VERSION ""

NS_ :

BS_:

BU_: Cooling DasFront DasRear Ecu Imu Lvac Pedals Pipo Raspberry Steering SteeringWheel TsacMainboard Acquisinator

BO_ 1260 ImuAngularRate: 6 Imu
 SG_ x : 7|16@0- (0.01,0) [0|245] "dps"  Vector__XXX
 SG_ y : 23|16@0- (0.01,0) [0|245] "dps"  Vector__XXX
 SG_ z : 39|16@0- (0.01,0) [0|245] "dps"  Vector__XXX

BO_ 1261 ImuAcceleration: 8 Imu
 SG_ x : 7|16@0- (0.01,0) [0|8] "g"  Vector__XXX
 SG_ y : 23|16@0- (0.01,0) [0|8] "g"  Vector__XXX
 SG_ z : 39|16@0- (0.01,0) [0|8] "g"  Vector__XXX
 SG_ temperature : 55|16@0- (1,-32768) [-32768|32767] "degC"  Vector__XXX

BO_ 1227 DasRearFsm: 1 DasRear
 SG_ status : 0|2@1+ (1,0) [0|0] "enum"  Vector__XXX

BO_ 1636 DasRearVersion: 6 DasRear
 SG_ major : 0|16@1+ (1,0) [0|65535] "U"  Vector__XXX
 SG_ minor : 16|16@1+ (1,0) [0|65535] "U"  Vector__XXX
 SG_ patch : 32|16@1+ (1,0) [0|65535] "U"  Vector__XXX

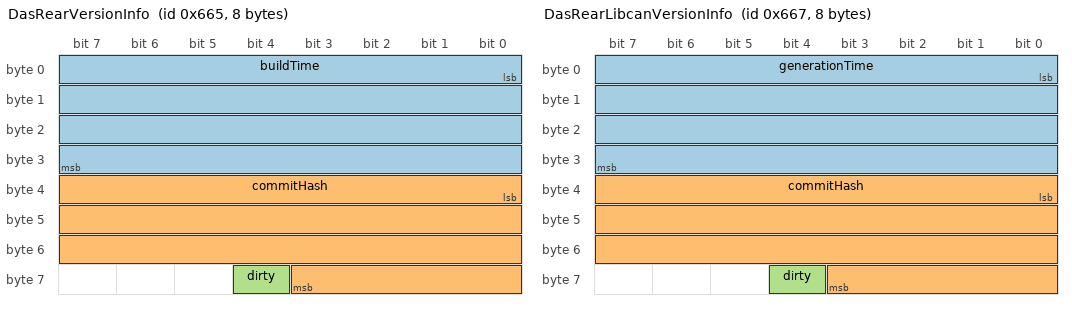
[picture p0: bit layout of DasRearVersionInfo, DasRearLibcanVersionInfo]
BO_ 1637 DasRearVersionInfo: 8 DasRear
 SG_ buildTime : 0|32@1+ (1,0) [0|4294967295] "s"  Vector__XXX
 SG_ commitHash : 32|28@1+ (1,0) [0|268435455] "U"  Vector__XXX
 SG_ dirty : 60|1@1+ (1,0) [0|1] "bool"  Vector__XXX

BO_ 1638 DasRearLibcanVersion: 6 DasRear
 SG_ major : 0|16@1+ (1,0) [0|65535] "U"  Vector__XXX
 SG_ minor : 16|16@1+ (1,0) [0|65535] "U"  Vector__XXX
 SG_ patch : 32|16@1+ (1,0) [0|65535] "U"  Vector__XXX

BO_ 1639 DasRearLibcanVersionInfo: 8 DasRear
 SG_ generationTime : 0|32@1+ (1,0) [0|4294967295] "s"  Vector__XXX
 SG_ commitHash : 32|28@1+ (1,0) [0|268435455] "U"  Vector__XXX
 SG_ dirty : 60|1@1+ (1,0) [0|1] "bool"  Vector__XXX

BO_ 1228 TyreTemperatureRear: 2 DasRear
 SG_ rearRight : 0|8@1+ (1,-20) [-20|150] "degC"  Vector__XXX
 SG_ rearLeft : 8|8@1+ (1,-20) [-20|150] "degC"  Vector__XXX

BO_ 1229 SuspensionRear: 4 DasRear
 SG_ heave : 0|13@1+ (0.01,0) [0|50] "mm"  Vector__XXX
 SG_ roll : 13|14@1+ (0.01,-50) [-50|50] "mm"  Vector__XXX

BO_ 1230 PipoFsm: 1 Pipo
 SG_ status : 0|2@1+ (1,0) [0|0] "enum"  Vector__XXX

BO_ 1640 PipoVersion: 6 Pipo
 SG_ major : 0|16@1+ (1,0) [0|65535] "U"  Vector__XXX
 SG_ minor : 16|16@1+ (1,0) [0|65535] "U"  Vector__XXX
 SG_ patch : 32|16@1+ (1,0) [0|65535] "U"  Vector__XXX

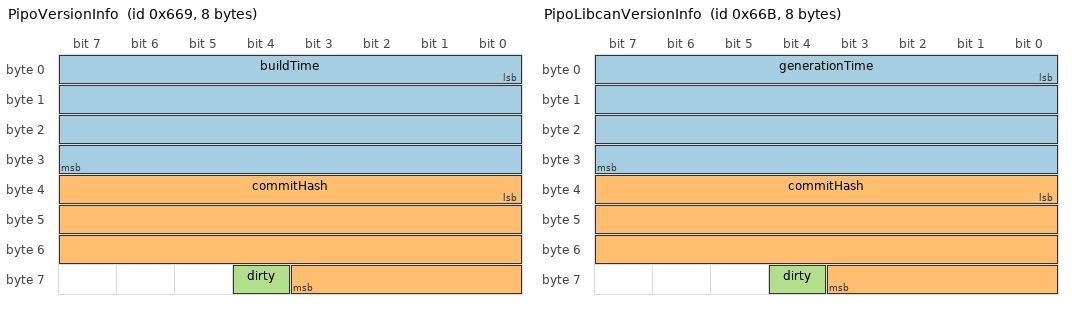
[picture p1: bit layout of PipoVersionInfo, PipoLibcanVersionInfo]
BO_ 1641 PipoVersionInfo: 8 Pipo
 SG_ buildTime : 0|32@1+ (1,0) [0|4294967295] "s"  Vector__XXX
 SG_ commitHash : 32|28@1+ (1,0) [0|268435455] "U"  Vector__XXX
 SG_ dirty : 60|1@1+ (1,0) [0|1] "bool"  Vector__XXX

BO_ 1642 PipoLibcanVersion: 6 Pipo
 SG_ major : 0|16@1+ (1,0) [0|65535] "U"  Vector__XXX
 SG_ minor : 16|16@1+ (1,0) [0|65535] "U"  Vector__XXX
 SG_ patch : 32|16@1+ (1,0) [0|65535] "U"  Vector__XXX

BO_ 1643 PipoLibcanVersionInfo: 8 Pipo
 SG_ generationTime : 0|32@1+ (1,0) [0|4294967295] "s"  Vector__XXX
 SG_ commitHash : 32|28@1+ (1,0) [0|268435455] "U"  Vector__XXX
 SG_ dirty : 60|1@1+ (1,0) [0|1] "bool"  Vector__XXX

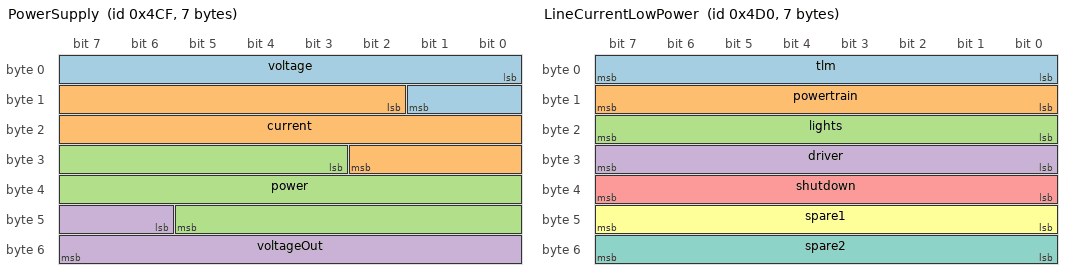
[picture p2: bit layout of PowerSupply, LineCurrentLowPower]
BO_ 1231 PowerSupply: 7 Pipo
 SG_ voltage : 0|10@1+ (0.03,0) [0|27] "V"  Vector__XXX
 SG_ current : 10|17@1+ (0.001,0) [0|100] "A"  Vector__XXX
 SG_ power : 27|19@1+ (0.01,0) [0|2700] "W"  Vector__XXX
 SG_ voltageOut : 46|10@1+ (0.03,0) [0|27] "V"  Vector__XXX

BO_ 1232 LineCurrentLowPower: 7 Pipo
 SG_ tlm : 0|8@1+ (0.05,0) [0|10] "A"  Vector__XXX
 SG_ powertrain : 8|8@1+ (0.05,0) [0|10] "A"  Vector__XXX
 SG_ lights : 16|8@1+ (0.05,0) [0|10] "A"  Vector__XXX
 SG_ driver : 24|8@1+ (0.05,0) [0|10] "A"  Vector__XXX
 SG_ shutdown : 32|8@1+ (0.05,0) [0|10] "A"  Vector__XXX
 SG_ spare1 : 40|8@1+ (0.05,0) [0|10] "A"  Vector__XXX
 SG_ spare2 : 48|8@1+ (0.05,0) [0|10] "A"  Vector__XXX

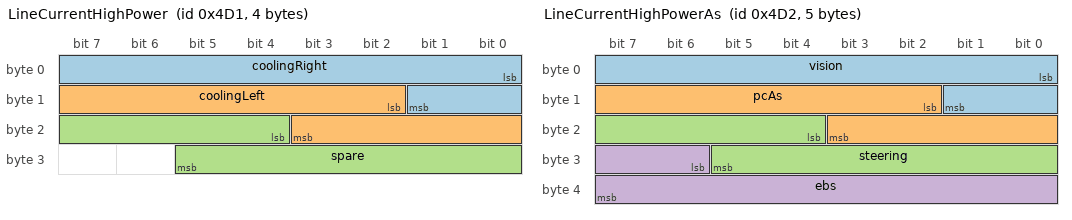
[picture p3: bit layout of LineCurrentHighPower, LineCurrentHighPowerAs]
BO_ 1233 LineCurrentHighPower: 4 Pipo
 SG_ coolingRight : 0|10@1+ (0.05,0) [0|30] "A"  Vector__XXX
 SG_ coolingLeft : 10|10@1+ (0.05,0) [0|30] "A"  Vector__XXX
 SG_ spare : 20|10@1+ (0.05,0) [0|30] "A"  Vector__XXX

BO_ 1234 LineCurrentHighPowerAs: 5 Pipo
 SG_ vision : 0|10@1+ (0.05,0) [0|30] "A"  Vector__XXX
 SG_ pcAs : 10|10@1+ (0.05,0) [0|30] "A"  Vector__XXX
 SG_ steering : 20|10@1+ (0.05,0) [0|30] "A"  Vector__XXX
 SG_ ebs : 30|10@1+ (0.05,0) [0|30] "A"  Vector__XXX

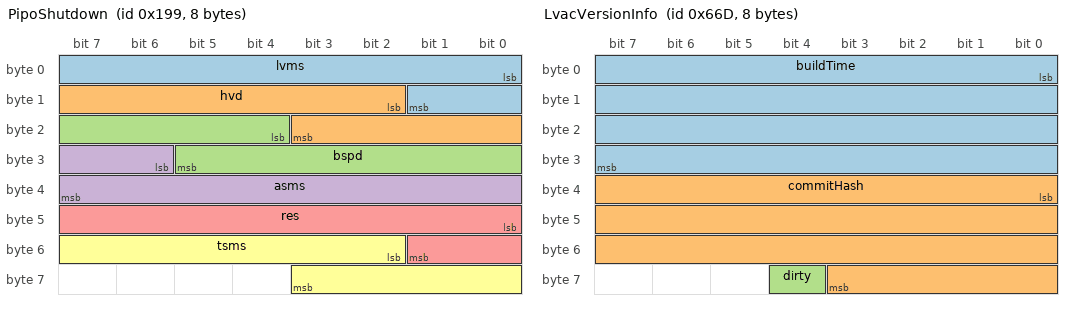
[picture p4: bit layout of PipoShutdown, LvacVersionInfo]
BO_ 409 PipoShutdown: 8 Pipo
 SG_ lvms : 0|10@1+ (0.03,0) [0|27] "V"  Vector__XXX
 SG_ hvd : 10|10@1+ (0.03,0) [0|27] "V"  Vector__XXX
 SG_ bspd : 20|10@1+ (0.03,0) [0|27] "V"  Vector__XXX
 SG_ asms : 30|10@1+ (0.03,0) [0|27] "V"  Vector__XXX
 SG_ res : 40|10@1+ (0.03,0) [0|27] "V"  Vector__XXX
 SG_ tsms : 50|10@1+ (0.03,0) [0|27] "V"  Vector__XXX

BO_ 1235 LvacFsm: 1 Lvac
 SG_ status : 0|2@1+ (1,0) [0|0] "enum"  Vector__XXX

BO_ 1644 LvacVersion: 6 Lvac
 SG_ major : 0|16@1+ (1,0) [0|65535] "U"  Vector__XXX
 SG_ minor : 16|16@1+ (1,0) [0|65535] "U"  Vector__XXX
 SG_ patch : 32|16@1+ (1,0) [0|65535] "U"  Vector__XXX

BO_ 1645 LvacVersionInfo: 8 Lvac
 SG_ buildTime : 0|32@1+ (1,0) [0|4294967295] "s"  Vector__XXX
 SG_ commitHash : 32|28@1+ (1,0) [0|268435455] "U"  Vector__XXX
 SG_ dirty : 60|1@1+ (1,0) [0|1] "bool"  Vector__XXX

BO_ 1646 LvacLibcanVersion: 6 Lvac
 SG_ major : 0|16@1+ (1,0) [0|65535] "U"  Vector__XXX
 SG_ minor : 16|16@1+ (1,0) [0|65535] "U"  Vector__XXX
 SG_ patch : 32|16@1+ (1,0) [0|65535] "U"  Vector__XXX

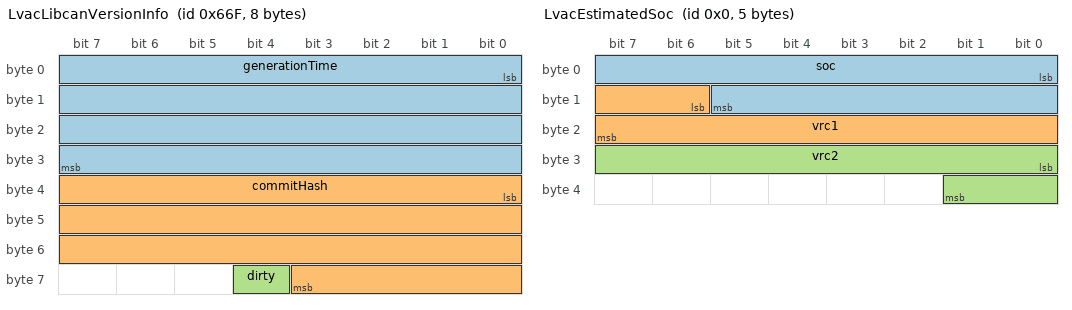
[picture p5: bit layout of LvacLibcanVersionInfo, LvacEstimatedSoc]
BO_ 1647 LvacLibcanVersionInfo: 8 Lvac
 SG_ generationTime : 0|32@1+ (1,0) [0|4294967295] "s"  Vector__XXX
 SG_ commitHash : 32|28@1+ (1,0) [0|268435455] "U"  Vector__XXX
 SG_ dirty : 60|1@1+ (1,0) [0|1] "bool"  Vector__XXX

BO_ 0 LvacEstimatedSoc: 5 Lvac
 SG_ soc : 0|14@1+ (0.0001,0) [0|1] "U"  Vector__XXX
 SG_ vrc1 : 14|10@1+ (0.005,0) [0|4.5] "V"  Vector__XXX
 SG_ vrc2 : 24|10@1+ (0.005,0) [0|4.5] "V"  Vector__XXX

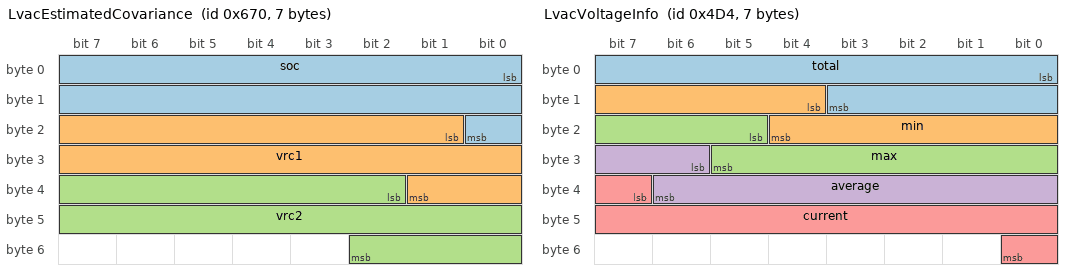
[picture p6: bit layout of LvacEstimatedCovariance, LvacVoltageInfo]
BO_ 1648 LvacEstimatedCovariance: 7 Lvac
 SG_ soc : 0|17@1+ (0.0001,0) [0|10] "U"  Vector__XXX
 SG_ vrc1 : 17|17@1+ (0.001,0) [0|100] "V"  Vector__XXX
 SG_ vrc2 : 34|17@1+ (0.001,0) [0|100] "V"  Vector__XXX

BO_ 1236 LvacVoltageInfo: 7 Lvac
 SG_ total : 0|12@1+ (0.01,0) [0|27] "V"  Vector__XXX
 SG_ min : 12|9@1+ (0.005,2) [2|4.5] "V"  Vector__XXX
 SG_ max : 21|9@1+ (0.005,2) [2|4.5] "V"  Vector__XXX
 SG_ average : 30|9@1+ (0.005,2) [2|4.5] "V"  Vector__XXX
 SG_ current : 39|10@1+ (0.05,0) [0|30] "A"  Vector__XXX

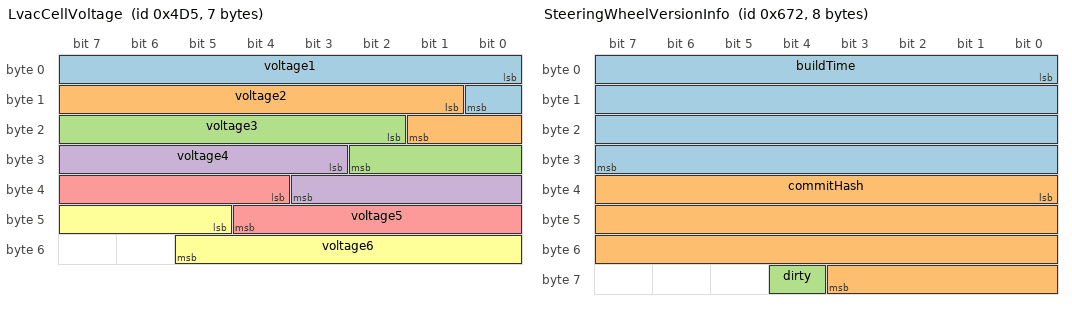
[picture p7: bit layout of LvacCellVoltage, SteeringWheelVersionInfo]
BO_ 1237 LvacCellVoltage: 7 Lvac
 SG_ voltage1 : 0|9@1+ (0.005,2) [2|4.5] "V"  Vector__XXX
 SG_ voltage2 : 9|9@1+ (0.005,2) [2|4.5] "V"  Vector__XXX
 SG_ voltage3 : 18|9@1+ (0.005,2) [2|4.5] "V"  Vector__XXX
 SG_ voltage4 : 27|9@1+ (0.005,2) [2|4.5] "V"  Vector__XXX
 SG_ voltage5 : 36|9@1+ (0.005,2) [2|4.5] "V"  Vector__XXX
 SG_ voltage6 : 45|9@1+ (0.005,2) [2|4.5] "V"  Vector__XXX

BO_ 1238 LvacTemperatureInfo: 6 Lvac
 SG_ min : 0|16@1+ (0.005,-50) [-50|125] "degC"  Vector__XXX
 SG_ max : 16|16@1+ (0.005,-50) [-50|125] "degC"  Vector__XXX
 SG_ average : 32|16@1+ (0.005,-50) [-50|125] "degC"  Vector__XXX

BO_ 1239 LvacTemperature: 7 Lvac
 SG_ group M : 0|1@1+ (1,0) [0|1] "U"  Vector__XXX
 SG_ temperature1 m0 : 1|9@1+ (0.005,2) [2|4.5] "degC"  Vector__XXX
 SG_ temperature2 m0 : 10|9@1+ (0.005,2) [2|4.5] "degC"  Vector__XXX
 SG_ temperature3 m0 : 19|9@1+ (0.005,2) [2|4.5] "degC"  Vector__XXX
 SG_ temperature4 m0 : 28|9@1+ (0.005,2) [2|4.5] "degC"  Vector__XXX
 SG_ temperature5 m0 : 37|9@1+ (0.005,2) [2|4.5] "degC"  Vector__XXX
 SG_ temperature6 m0 : 46|9@1+ (0.005,2) [2|4.5] "degC"  Vector__XXX
 SG_ temperature7 m1 : 1|9@1+ (0.005,2) [2|4.5] "degC"  Vector__XXX
 SG_ temperature8 m1 : 10|9@1+ (0.005,2) [2|4.5] "degC"  Vector__XXX
 SG_ temperature9 m1 : 19|9@1+ (0.005,2) [2|4.5] "degC"  Vector__XXX
 SG_ temperature10 m1 : 28|9@1+ (0.005,2) [2|4.5] "degC"  Vector__XXX
 SG_ temperature11 m1 : 37|9@1+ (0.005,2) [2|4.5] "degC"  Vector__XXX
 SG_ temperature12 m1 : 46|9@1+ (0.005,2) [2|4.5] "degC"  Vector__XXX

BO_ 1240 SteeringWheelFsm: 1 SteeringWheel
 SG_ status : 0|3@1+ (1,0) [0|0] "enum"  Vector__XXX

BO_ 1649 SteeringWheelVersion: 6 SteeringWheel
 SG_ major : 0|16@1+ (1,0) [0|65535] "U"  Vector__XXX
 SG_ minor : 16|16@1+ (1,0) [0|65535] "U"  Vector__XXX
 SG_ patch : 32|16@1+ (1,0) [0|65535] "U"  Vector__XXX

BO_ 1650 SteeringWheelVersionInfo: 8 SteeringWheel
 SG_ buildTime : 0|32@1+ (1,0) [0|4294967295] "s"  Vector__XXX
 SG_ commitHash : 32|28@1+ (1,0) [0|268435455] "U"  Vector__XXX
 SG_ dirty : 60|1@1+ (1,0) [0|1] "bool"  Vector__XXX

BO_ 1651 SteeringWheelLibcanVersion: 6 SteeringWheel
 SG_ major : 0|16@1+ (1,0) [0|65535] "U"  Vector__XXX
 SG_ minor : 16|16@1+ (1,0) [0|65535] "U"  Vector__XXX
 SG_ patch : 32|16@1+ (1,0) [0|65535] "U"  Vector__XXX

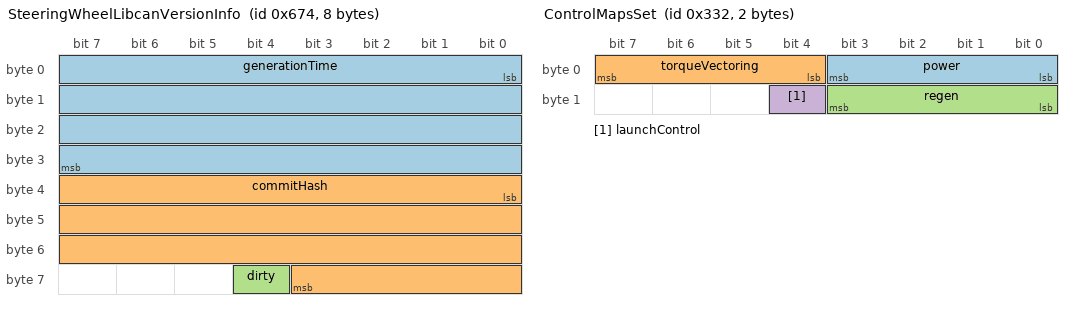
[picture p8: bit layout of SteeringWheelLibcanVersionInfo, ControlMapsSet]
BO_ 1652 SteeringWheelLibcanVersionInfo: 8 SteeringWheel
 SG_ generationTime : 0|32@1+ (1,0) [0|4294967295] "s"  Vector__XXX
 SG_ commitHash : 32|28@1+ (1,0) [0|268435455] "U"  Vector__XXX
 SG_ dirty : 60|1@1+ (1,0) [0|1] "bool"  Vector__XXX

BO_ 818 ControlMapsSet: 2 SteeringWheel
 SG_ power : 0|4@1+ (0.1,0) [0|1] "U"  Vector__XXX
 SG_ torqueVectoring : 4|4@1+ (0.1,0) [0|1] "U"  Vector__XXX
 SG_ regen : 8|4@1+ (0.1,0) [0|1] "U"  Vector__XXX
 SG_ launchControl : 12|1@1+ (1,0) [0|1] "bool"  Vector__XXX

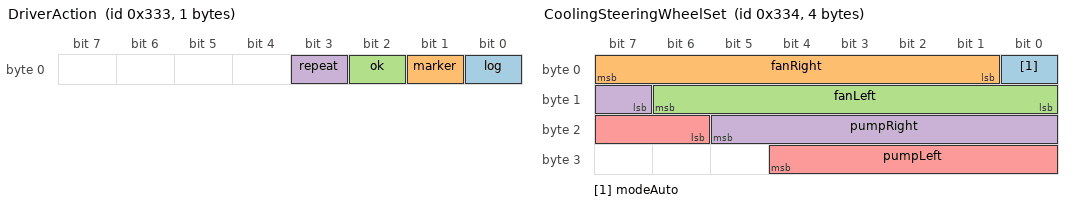
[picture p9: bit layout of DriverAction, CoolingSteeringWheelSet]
BO_ 819 DriverAction: 1 SteeringWheel
 SG_ log : 0|1@1+ (1,0) [0|1] "bool"  Vector__XXX
 SG_ marker : 1|1@1+ (1,0) [0|1] "bool"  Vector__XXX
 SG_ ok : 2|1@1+ (1,0) [0|1] "bool"  Vector__XXX
 SG_ repeat : 3|1@1+ (1,0) [0|1] "bool"  Vector__XXX

BO_ 1 SteeringWheelButtonStatus: 1 SteeringWheel
 SG_ tson : 0|1@1+ (1,0) [0|1] "bool"  Vector__XXX
 SG_ ptt : 1|1@1+ (1,0) [0|1] "bool"  Vector__XXX

BO_ 820 CoolingSteeringWheelSet: 4 SteeringWheel
 SG_ modeAuto : 0|1@1+ (1,0) [0|1] "bool"  Vector__XXX
 SG_ fanRight : 1|7@1+ (0.01,0) [0|1] "U"  Vector__XXX
 SG_ fanLeft : 8|7@1+ (0.01,0) [0|1] "U"  Vector__XXX
 SG_ pumpRight : 15|7@1+ (0.01,0) [0|1] "U"  Vector__XXX
 SG_ pumpLeft : 22|7@1+ (0.01,0) [0|1] "U"  Vector__XXX

BO_ 1241 CoolingFsm: 1 Cooling
 SG_ status : 0|2@1+ (1,0) [0|0] "enum"  Vector__XXX

BO_ 1653 CoolingVersion: 6 Cooling
 SG_ major : 0|16@1+ (1,0) [0|65535] "U"  Vector__XXX
 SG_ minor : 16|16@1+ (1,0) [0|65535] "U"  Vector__XXX
 SG_ patch : 32|16@1+ (1,0) [0|65535] "U"  Vector__XXX

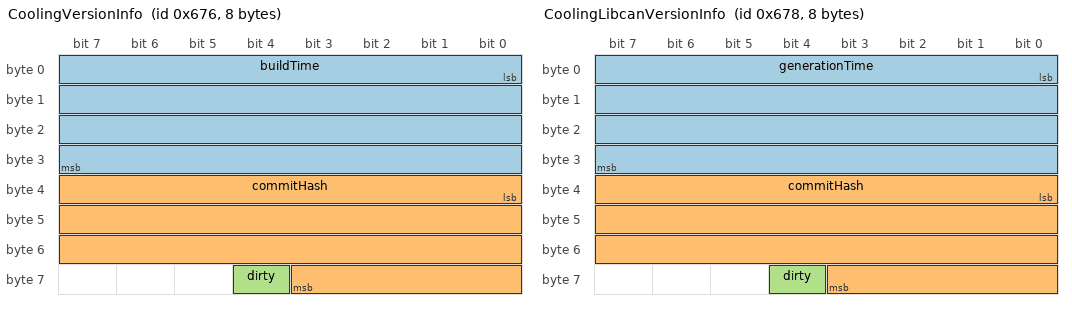
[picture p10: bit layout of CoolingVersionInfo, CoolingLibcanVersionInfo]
BO_ 1654 CoolingVersionInfo: 8 Cooling
 SG_ buildTime : 0|32@1+ (1,0) [0|4294967295] "s"  Vector__XXX
 SG_ commitHash : 32|28@1+ (1,0) [0|268435455] "U"  Vector__XXX
 SG_ dirty : 60|1@1+ (1,0) [0|1] "bool"  Vector__XXX

BO_ 1655 CoolingLibcanVersion: 6 Cooling
 SG_ major : 0|16@1+ (1,0) [0|65535] "U"  Vector__XXX
 SG_ minor : 16|16@1+ (1,0) [0|65535] "U"  Vector__XXX
 SG_ patch : 32|16@1+ (1,0) [0|65535] "U"  Vector__XXX

BO_ 1656 CoolingLibcanVersionInfo: 8 Cooling
 SG_ generationTime : 0|32@1+ (1,0) [0|4294967295] "s"  Vector__XXX
 SG_ commitHash : 32|28@1+ (1,0) [0|268435455] "U"  Vector__XXX
 SG_ dirty : 60|1@1+ (1,0) [0|1] "bool"  Vector__XXX

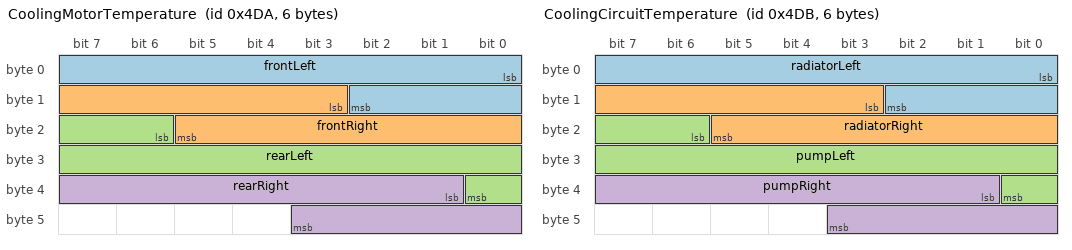
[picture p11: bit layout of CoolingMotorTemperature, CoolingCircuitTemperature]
BO_ 1242 CoolingMotorTemperature: 6 Cooling
 SG_ frontLeft : 0|11@1+ (0.1,-50) [-50|125] "degC"  Vector__XXX
 SG_ frontRight : 11|11@1+ (0.1,-50) [-50|125] "degC"  Vector__XXX
 SG_ rearLeft : 22|11@1+ (0.1,-50) [-50|125] "degC"  Vector__XXX
 SG_ rearRight : 33|11@1+ (0.1,-50) [-50|125] "degC"  Vector__XXX

BO_ 1243 CoolingCircuitTemperature: 6 Cooling
 SG_ radiatorLeft : 0|11@1+ (0.1,-50) [-50|125] "degC"  Vector__XXX
 SG_ radiatorRight : 11|11@1+ (0.1,-50) [-50|125] "degC"  Vector__XXX
 SG_ pumpLeft : 22|11@1+ (0.1,-50) [-50|125] "degC"  Vector__XXX
 SG_ pumpRight : 33|11@1+ (0.1,-50) [-50|125] "degC"  Vector__XXX

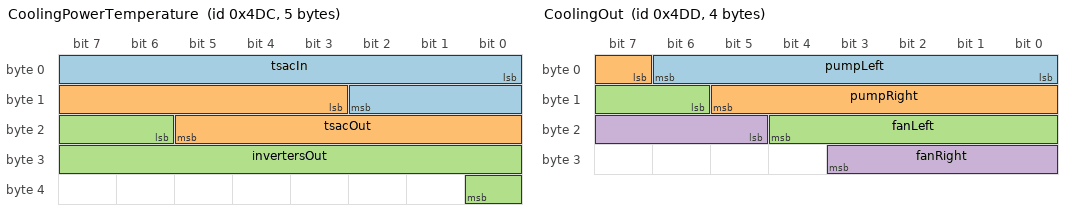
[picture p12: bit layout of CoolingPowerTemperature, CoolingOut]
BO_ 1244 CoolingPowerTemperature: 5 Cooling
 SG_ tsacIn : 0|11@1+ (0.1,-50) [-50|125] "degC"  Vector__XXX
 SG_ tsacOut : 11|11@1+ (0.1,-50) [-50|125] "degC"  Vector__XXX
 SG_ invertersOut : 22|11@1+ (0.1,-50) [-50|125] "degC"  Vector__XXX

BO_ 1245 CoolingOut: 4 Cooling
 SG_ pumpLeft : 0|7@1+ (0.01,0) [0|1] "U"  Vector__XXX
 SG_ pumpRight : 7|7@1+ (0.01,0) [0|1] "U"  Vector__XXX
 SG_ fanLeft : 14|7@1+ (0.01,0) [0|1] "U"  Vector__XXX
 SG_ fanRight : 21|7@1+ (0.01,0) [0|1] "U"  Vector__XXX

BO_ 1246 SteeringFsm: 1 Steering
 SG_ status : 0|2@1+ (1,0) [0|0] "enum"  Vector__XXX

BO_ 1657 SteeringVersion: 6 Steering
 SG_ major : 0|16@1+ (1,0) [0|65535] "U"  Vector__XXX
 SG_ minor : 16|16@1+ (1,0) [0|65535] "U"  Vector__XXX
 SG_ patch : 32|16@1+ (1,0) [0|65535] "U"  Vector__XXX

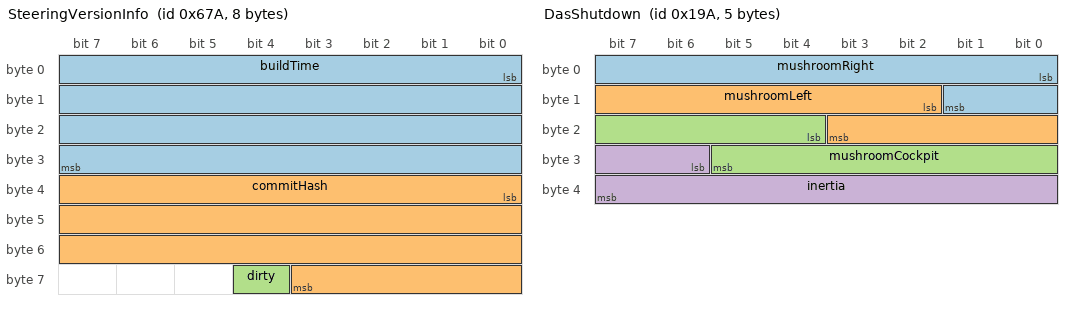
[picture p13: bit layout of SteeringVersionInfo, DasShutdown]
BO_ 1658 SteeringVersionInfo: 8 Steering
 SG_ buildTime : 0|32@1+ (1,0) [0|4294967295] "s"  Vector__XXX
 SG_ commitHash : 32|28@1+ (1,0) [0|268435455] "U"  Vector__XXX
 SG_ dirty : 60|1@1+ (1,0) [0|1] "bool"  Vector__XXX

BO_ 1659 SteeringLibcanVersion: 6 Steering
 SG_ major : 0|16@1+ (1,0) [0|65535] "U"  Vector__XXX
 SG_ minor : 16|16@1+ (1,0) [0|65535] "U"  Vector__XXX
 SG_ patch : 32|16@1+ (1,0) [0|65535] "U"  Vector__XXX

BO_ 1660 SteeringLibcanVersionInfo: 8 Steering
 SG_ generationTime : 0|32@1+ (1,0) [0|4294967295] "s"  Vector__XXX
 SG_ commitHash : 32|28@1+ (1,0) [0|268435455] "U"  Vector__XXX
 SG_ dirty : 60|1@1+ (1,0) [0|1] "bool"  Vector__XXX

BO_ 1247 SteeringEncoder: 2 Steering
 SG_ angle : 0|13@1+ (0.001,0) [-2.1|2.1] "rad"  Vector__XXX

BO_ 1248 DasFrontFsm: 1 DasFront
 SG_ status : 0|2@1+ (1,0) [0|0] "enum"  Vector__XXX

BO_ 1661 DasFrontVersion: 6 DasFront
 SG_ major : 0|16@1+ (1,0) [0|65535] "U"  Vector__XXX
 SG_ minor : 16|16@1+ (1,0) [0|65535] "U"  Vector__XXX
 SG_ patch : 32|16@1+ (1,0) [0|65535] "U"  Vector__XXX

BO_ 1662 DasFrontVersionInfo: 8 DasFront
 SG_ buildTime : 0|32@1+ (1,0) [0|4294967295] "s"  Vector__XXX
 SG_ commitHash : 32|28@1+ (1,0) [0|268435455] "U"  Vector__XXX
 SG_ dirty : 60|1@1+ (1,0) [0|1] "bool"  Vector__XXX

BO_ 1663 DasFrontLibcanVersion: 6 DasFront
 SG_ major : 0|16@1+ (1,0) [0|65535] "U"  Vector__XXX
 SG_ minor : 16|16@1+ (1,0) [0|65535] "U"  Vector__XXX
 SG_ patch : 32|16@1+ (1,0) [0|65535] "U"  Vector__XXX

BO_ 1664 DasFrontLibcanVersionInfo: 8 DasFront
 SG_ generationTime : 0|32@1+ (1,0) [0|4294967295] "s"  Vector__XXX
 SG_ commitHash : 32|28@1+ (1,0) [0|268435455] "U"  Vector__XXX
 SG_ dirty : 60|1@1+ (1,0) [0|1] "bool"  Vector__XXX

BO_ 1249 TyreTemperatureFront: 2 DasFront
 SG_ frontRight : 0|8@1+ (1,-20) [-20|150] "degC"  Vector__XXX
 SG_ frontLeft : 8|8@1+ (1,-20) [-20|150] "degC"  Vector__XXX

BO_ 1250 SuspensionFront: 4 DasFront
 SG_ heave : 0|13@1+ (0.01,0) [0|50] "mm"  Vector__XXX
 SG_ roll : 13|14@1+ (0.01,-50) [-50|50] "mm"  Vector__XXX

BO_ 410 DasShutdown: 5 Das
 SG_ mushroomRight : 0|10@1+ (0.03,0) [0|27] "V"  Vector__XXX
 SG_ mushroomLeft : 10|10@1+ (0.03,0) [0|27] "V"  Vector__XXX
 SG_ mushroomCockpit : 20|10@1+ (0.03,0) [0|27] "V"  Vector__XXX
 SG_ inertia : 30|10@1+ (0.03,0) [0|27] "V"  Vector__XXX

BO_ 2 EcuFsm: 2 Ecu
 SG_ vehicleStatus : 0|4@1+ (1,0) [0|0] "enum"  Vector__XXX
 SG_ krakenStatus : 4|5@1+ (1,0) [0|0] "enum"  Vector__XXX

BO_ 1665 EcuVersion: 6 Ecu
 SG_ major : 0|16@1+ (1,0) [0|65535] "U"  Vector__XXX
 SG_ minor : 16|16@1+ (1,0) [0|65535] "U"  Vector__XXX
 SG_ patch : 32|16@1+ (1,0) [0|65535] "U"  Vector__XXX

BO_ 1666 EcuVersionInfo: 8 Ecu
 SG_ buildTime : 0|32@1+ (1,0) [0|4294967295] "s"  Vector__XXX
 SG_ commitHash : 32|28@1+ (1,0) [0|268435455] "U"  Vector__XXX
 SG_ dirty : 60|1@1+ (1,0) [0|1] "bool"  Vector__XXX

BO_ 1667 EcuLibcanVersion: 6 Ecu
 SG_ major : 0|16@1+ (1,0) [0|65535] "U"  Vector__XXX
 SG_ minor : 16|16@1+ (1,0) [0|65535] "U"  Vector__XXX
 SG_ patch : 32|16@1+ (1,0) [0|65535] "U"  Vector__XXX

BO_ 1668 EcuLibcanVersionInfo: 8 Ecu
 SG_ generationTime : 0|32@1+ (1,0) [0|4294967295] "s"  Vector__XXX
 SG_ commitHash : 32|28@1+ (1,0) [0|268435455] "U"  Vector__XXX
 SG_ dirty : 60|1@1+ (1,0) [0|1] "bool"  Vector__XXX

BO_ 3 BmsSet: 1 Ecu
 SG_ status : 0|1@1+ (1,0) [0|1] "bool"  Vector__XXX

BO_ 411 ShutdownState: 3 Ecu
 SG_ voltageIn : 0|10@1+ (0.03,0) [0|27] "V"  Vector__XXX
 SG_ voltageOut : 10|10@1+ (0.03,0) [0|27] "V"  Vector__XXX

BO_ 1251 Ptt: 1 Ecu
 SG_ status : 0|1@1+ (1,0) [0|1] "bool"  Vector__XXX

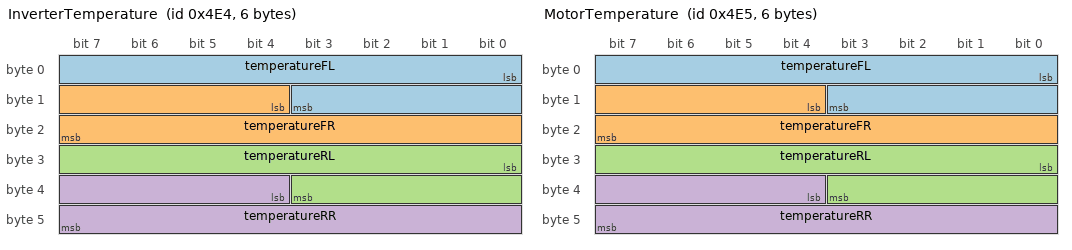
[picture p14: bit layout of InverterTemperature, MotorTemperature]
BO_ 1252 InverterTemperature: 6 Ecu
 SG_ temperatureFL : 0|12@1+ (0.0625,0) [0|255.9375] "degC"  Vector__XXX
 SG_ temperatureFR : 12|12@1+ (0.0625,0) [0|255.9375] "degC"  Vector__XXX
 SG_ temperatureRL : 24|12@1+ (0.0625,0) [0|255.9375] "degC"  Vector__XXX
 SG_ temperatureRR : 36|12@1+ (0.0625,0) [0|255.9375] "degC"  Vector__XXX

BO_ 1253 MotorTemperature: 6 Ecu
 SG_ temperatureFL : 0|12@1+ (0.125,-256) [-256|255.875] "degC"  Vector__XXX
 SG_ temperatureFR : 12|12@1+ (0.125,-256) [-256|255.875] "degC"  Vector__XXX
 SG_ temperatureRL : 24|12@1+ (0.125,-256) [-256|255.875] "degC"  Vector__XXX
 SG_ temperatureRR : 36|12@1+ (0.125,-256) [-256|255.875] "degC"  Vector__XXX

BO_ 1254 MotorTorque: 8 Ecu
 SG_ torqueFL : 0|16@1+ (0.00390625,-128) [-128|127.99609375] "Nm"  Vector__XXX
 SG_ torqueFR : 16|16@1+ (0.00390625,-128) [-128|127.99609375] "Nm"  Vector__XXX
 SG_ torqueRL : 32|16@1+ (0.00390625,-128) [-128|127.99609375] "Nm"  Vector__XXX
 SG_ torqueRR : 48|16@1+ (0.00390625,-128) [-128|127.99609375] "Nm"  Vector__XXX

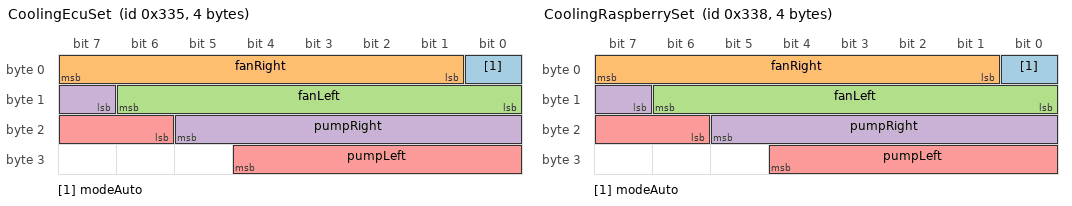
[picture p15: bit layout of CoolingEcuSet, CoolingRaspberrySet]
BO_ 821 CoolingEcuSet: 4 Ecu
 SG_ modeAuto : 0|1@1+ (1,0) [0|1] "bool"  Vector__XXX
 SG_ fanRight : 1|7@1+ (0.01,0) [0|1] "U"  Vector__XXX
 SG_ fanLeft : 8|7@1+ (0.01,0) [0|1] "U"  Vector__XXX
 SG_ pumpRight : 15|7@1+ (0.01,0) [0|1] "U"  Vector__XXX
 SG_ pumpLeft : 22|7@1+ (0.01,0) [0|1] "U"  Vector__XXX

BO_ 1255 TelemetryFsm: 1 Raspberry
 SG_ status : 0|3@1+ (1,0) [0|0] "enum"  SteeringWheel

BO_ 1669 TelemetryVersion: 6 Raspberry
 SG_ major : 0|16@1+ (1,0) [0|65535] "U"  Vector__XXX
 SG_ minor : 16|16@1+ (1,0) [0|65535] "U"  Vector__XXX
 SG_ patch : 32|16@1+ (1,0) [0|65535] "U"  Vector__XXX

BO_ 1670 TelemetryVersionInfo: 8 Raspberry
 SG_ buildTime : 0|32@1+ (1,0) [0|4294967295] "s"  Vector__XXX
 SG_ commitHash : 32|28@1+ (1,0) [0|268435455] "U"  Vector__XXX
 SG_ dirty : 60|1@1+ (1,0) [0|1] "bool"  Vector__XXX

BO_ 1671 TelemetryLibcanVersion: 6 Raspberry
 SG_ major : 0|16@1+ (1,0) [0|65535] "U"  Vector__XXX
 SG_ minor : 16|16@1+ (1,0) [0|65535] "U"  Vector__XXX
 SG_ patch : 32|16@1+ (1,0) [0|65535] "U"  Vector__XXX

BO_ 1672 TelemetryLibcanVersionInfo: 8 Raspberry
 SG_ generationTime : 0|32@1+ (1,0) [0|4294967295] "s"  Vector__XXX
 SG_ commitHash : 32|28@1+ (1,0) [0|268435455] "U"  Vector__XXX
 SG_ dirty : 60|1@1+ (1,0) [0|1] "bool"  Vector__XXX

BO_ 1256 EstimatedVehiclePosition: 8 Raspberry
 SG_ x : 0|22@1+ (0.001,-2000) [-2000|2000] "m"  Vector__XXX
 SG_ y : 22|22@1+ (0.001,-2000) [-2000|2000] "m"  Vector__XXX
 SG_ psi : 44|18@1+ (1e-05,0) [0|6.283185307179586] "rad"  Vector__XXX

BO_ 1257 EstimatedVehicleVelocity: 4 Raspberry
 SG_ u : 0|16@1+ (0.001,0) [0|45] "mps"  SteeringWheel
 SG_ v : 16|16@1+ (0.001,-20) [-20|20] "mps"  Vector__XXX

BO_ 1258 CurrentLap: 4 Raspberry
 SG_ number : 0|7@1+ (1,0) [0|127] "U"  SteeringWheel
 SG_ deltaBestLap : 7|18@1+ (0.001,-128) [-128|127] "s"  SteeringWheel

BO_ 1259 BestLap: 4 Raspberry
 SG_ number : 0|7@1+ (1,0) [0|127] "U"  Vector__XXX
 SG_ time : 7|19@1+ (0.001,0) [0|511] "s"  SteeringWheel

BO_ 1262 LastLap: 3 Raspberry
 SG_ time : 0|19@1+ (0.001,0) [0|511] "s"  Vector__XXX

BO_ 1263 Laps: 3 Raspberry
 SG_ totalNumber : 0|7@1+ (1,0) [0|127] "U"  SteeringWheel
 SG_ totalTime : 7|13@1+ (1,0) [0|8191] "s"  Vector__XXX

BO_ 1264 CurvilinearCoordinates: 4 Raspberry
 SG_ s : 0|18@1+ (0.01,0) [0|2000] "m"  Vector__XXX
 SG_ n : 18|13@1+ (0.01,-25) [-25|25] "m"  Vector__XXX

BO_ 822 RaspberryTsacBalancingSet: 1 Raspberry
 SG_ start : 0|1@1+ (1,0) [0|0] "bool"  Vector__XXX
 SG_ threshold : 1|6@1+ (0.005,0) [0|0.2] "V"  Vector__XXX

BO_ 823 RaspberryLvacBalancingSet: 1 Raspberry
 SG_ start : 0|1@1+ (1,0) [0|0] "bool"  Vector__XXX
 SG_ threshold : 1|6@1+ (0.005,0) [0|0.2] "V"  Vector__XXX

BO_ 1673 ControlsVersion: 6 Raspberry
 SG_ major : 0|16@1+ (1,0) [0|65535] "U"  Vector__XXX
 SG_ minor : 16|16@1+ (1,0) [0|65535] "U"  Vector__XXX
 SG_ patch : 32|16@1+ (1,0) [0|65535] "U"  Vector__XXX

BO_ 1674 ControlsVersionInfo: 8 Raspberry
 SG_ buildTime : 0|32@1+ (1,0) [0|4294967295] "s"  Vector__XXX
 SG_ commitHash : 32|28@1+ (1,0) [0|268435455] "U"  Vector__XXX
 SG_ dirty : 60|1@1+ (1,0) [0|1] "bool"  Vector__XXX

BO_ 1675 ControlsLibcanVersion: 6 Raspberry
 SG_ major : 0|16@1+ (1,0) [0|65535] "U"  Vector__XXX
 SG_ minor : 16|16@1+ (1,0) [0|65535] "U"  Vector__XXX
 SG_ patch : 32|16@1+ (1,0) [0|65535] "U"  Vector__XXX

BO_ 1676 ControlsLibcanVersionInfo: 8 Raspberry
 SG_ generationTime : 0|32@1+ (1,0) [0|4294967295] "s"  Vector__XXX
 SG_ commitHash : 32|28@1+ (1,0) [0|268435455] "U"  Vector__XXX
 SG_ dirty : 60|1@1+ (1,0) [0|1] "bool"  Vector__XXX

BO_ 824 CoolingRaspberrySet: 4 Raspberry
 SG_ modeAuto : 0|1@1+ (1,0) [0|1] "bool"  Vector__XXX
 SG_ fanRight : 1|7@1+ (0.01,0) [0|1] "U"  Vector__XXX
 SG_ fanLeft : 8|7@1+ (0.01,0) [0|1] "U"  Vector__XXX
 SG_ pumpRight : 15|7@1+ (0.01,0) [0|1] "U"  Vector__XXX
 SG_ pumpLeft : 22|7@1+ (0.01,0) [0|1] "U"  Vector__XXX

BO_ 1265 PedalsFsm: 1 Pedals
 SG_ status : 0|2@1+ (1,0) [0|0] "enum"  Vector__XXX

BO_ 1677 PedalsVersion: 6 Pedals
 SG_ major : 0|16@1+ (1,0) [0|65535] "U"  Vector__XXX
 SG_ minor : 16|16@1+ (1,0) [0|65535] "U"  Vector__XXX
 SG_ patch : 32|16@1+ (1,0) [0|65535] "U"  Vector__XXX

BO_ 1678 PedalsVersionInfo: 8 Pedals
 SG_ buildTime : 0|32@1+ (1,0) [0|4294967295] "s"  Vector__XXX
 SG_ commitHash : 32|28@1+ (1,0) [0|268435455] "U"  Vector__XXX
 SG_ dirty : 60|1@1+ (1,0) [0|1] "bool"  Vector__XXX

BO_ 1679 PedalsLibcanVersion: 6 Pedals
 SG_ major : 0|16@1+ (1,0) [0|65535] "U"  Vector__XXX
 SG_ minor : 16|16@1+ (1,0) [0|65535] "U"  Vector__XXX
 SG_ patch : 32|16@1+ (1,0) [0|65535] "U"  Vector__XXX

BO_ 1680 PedalsLibcanVersionInfo: 8 Pedals
 SG_ generationTime : 0|32@1+ (1,0) [0|4294967295] "s"  Vector__XXX
 SG_ commitHash : 32|28@1+ (1,0) [0|268435455] "U"  Vector__XXX
 SG_ dirty : 60|1@1+ (1,0) [0|1] "bool"  Vector__XXX

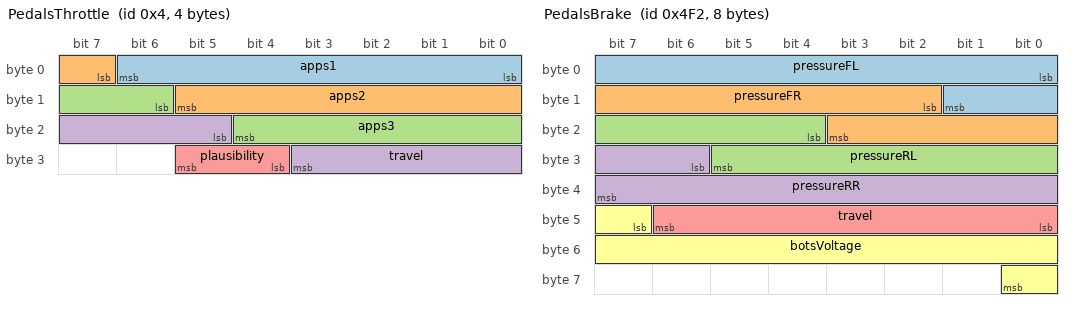
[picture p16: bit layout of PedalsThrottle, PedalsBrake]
BO_ 4 PedalsThrottle: 4 Pedals
 SG_ apps1 : 0|7@1+ (0.01,0) [0|1] "U"  Vector__XXX
 SG_ apps2 : 7|7@1+ (0.01,0) [0|1] "U"  Vector__XXX
 SG_ apps3 : 14|7@1+ (0.01,0) [0|1] "U"  Vector__XXX
 SG_ travel : 21|7@1+ (0.01,0) [0|1] "U"  Vector__XXX
 SG_ plausibility : 28|2@1+ (1,0) [0|0] "enum"  Vector__XXX

BO_ 1266 PedalsBrake: 8 Pedals
 SG_ pressureFL : 0|10@1+ (0.1,0) [0|100] "bar"  Vector__XXX
 SG_ pressureFR : 10|10@1+ (0.1,0) [0|100] "bar"  Vector__XXX
 SG_ pressureRL : 20|10@1+ (0.1,0) [0|100] "bar"  Vector__XXX
 SG_ pressureRR : 30|10@1+ (0.1,0) [0|100] "bar"  Vector__XXX
 SG_ travel : 40|7@1+ (0.01,0) [0|1] "U"  Vector__XXX
 SG_ botsVoltage : 47|10@1+ (0.03,0) [0|27] "V"  Vector__XXX

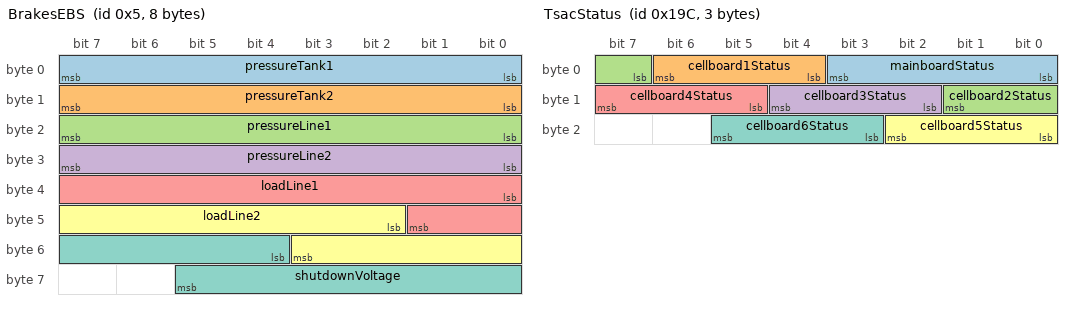
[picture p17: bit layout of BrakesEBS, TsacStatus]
BO_ 5 BrakesEBS: 8 Pedals
 SG_ pressureTank1 : 0|8@1+ (0.1,0) [0|15] "bar"  Vector__XXX
 SG_ pressureTank2 : 8|8@1+ (0.1,0) [0|15] "bar"  Vector__XXX
 SG_ pressureLine1 : 16|8@1+ (0.1,0) [0|15] "bar"  Vector__XXX
 SG_ pressureLine2 : 24|8@1+ (0.1,0) [0|15] "bar"  Vector__XXX
 SG_ loadLine1 : 32|10@1+ (1,0) [0|800] "N"  Vector__XXX
 SG_ loadLine2 : 42|10@1+ (1,0) [0|800] "N"  Vector__XXX
 SG_ shutdownVoltage : 52|10@1+ (0.03,0) [0|27] "V"  Vector__XXX

BO_ 412 TsacStatus: 3 TsacMainboard
 SG_ mainboardStatus : 0|4@1+ (1,0) [0|0] "enum"  Vector__XXX
 SG_ cellboard1Status : 4|3@1+ (1,0) [0|0] "enum"  Vector__XXX
 SG_ cellboard2Status : 7|3@1+ (1,0) [0|0] "enum"  Vector__XXX
 SG_ cellboard3Status : 10|3@1+ (1,0) [0|0] "enum"  Vector__XXX
 SG_ cellboard4Status : 13|3@1+ (1,0) [0|0] "enum"  Vector__XXX
 SG_ cellboard5Status : 16|3@1+ (1,0) [0|0] "enum"  Vector__XXX
 SG_ cellboard6Status : 19|3@1+ (1,0) [0|0] "enum"  Vector__XXX

BO_ 1681 TsacMainboardVersion: 6 TsacMainboard
 SG_ major : 0|16@1+ (1,0) [0|65535] "U"  Vector__XXX
 SG_ minor : 16|16@1+ (1,0) [0|65535] "U"  Vector__XXX
 SG_ patch : 32|16@1+ (1,0) [0|65535] "U"  Vector__XXX

BO_ 1682 TsacMainboardVersionInfo: 8 TsacMainboard
 SG_ buildTime : 0|32@1+ (1,0) [0|4294967295] "s"  Vector__XXX
 SG_ commitHash : 32|28@1+ (1,0) [0|268435455] "U"  Vector__XXX
 SG_ dirty : 60|1@1+ (1,0) [0|1] "bool"  Vector__XXX

BO_ 1683 TsacMainboardLibcanVersion: 6 TsacMainboard
 SG_ major : 0|16@1+ (1,0) [0|65535] "U"  Vector__XXX
 SG_ minor : 16|16@1+ (1,0) [0|65535] "U"  Vector__XXX
 SG_ patch : 32|16@1+ (1,0) [0|65535] "U"  Vector__XXX

BO_ 1684 TsacMainboardLibcanVersionInfo: 8 TsacMainboard
 SG_ generationTime : 0|32@1+ (1,0) [0|4294967295] "s"  Vector__XXX
 SG_ commitHash : 32|28@1+ (1,0) [0|268435455] "U"  Vector__XXX
 SG_ dirty : 60|1@1+ (1,0) [0|1] "bool"  Vector__XXX

BO_ 1685 TsacCellboard1Version: 6 TsacMainboard
 SG_ major : 0|16@1+ (1,0) [0|65535] "U"  Vector__XXX
 SG_ minor : 16|16@1+ (1,0) [0|65535] "U"  Vector__XXX
 SG_ patch : 32|16@1+ (1,0) [0|65535] "U"  Vector__XXX

BO_ 1686 TsacCellboard1VersionInfo: 8 TsacMainboard
 SG_ buildTime : 0|32@1+ (1,0) [0|4294967295] "s"  Vector__XXX
 SG_ commitHash : 32|28@1+ (1,0) [0|268435455] "U"  Vector__XXX
 SG_ dirty : 60|1@1+ (1,0) [0|1] "bool"  Vector__XXX

BO_ 1687 TsacCellboard1LibcanVersion: 6 TsacMainboard
 SG_ major : 0|16@1+ (1,0) [0|65535] "U"  Vector__XXX
 SG_ minor : 16|16@1+ (1,0) [0|65535] "U"  Vector__XXX
 SG_ patch : 32|16@1+ (1,0) [0|65535] "U"  Vector__XXX

BO_ 1688 TsacCellboard1LibcanVersionInfo: 8 TsacMainboard
 SG_ generationTime : 0|32@1+ (1,0) [0|4294967295] "s"  Vector__XXX
 SG_ commitHash : 32|28@1+ (1,0) [0|268435455] "U"  Vector__XXX
 SG_ dirty : 60|1@1+ (1,0) [0|1] "bool"  Vector__XXX

BO_ 1689 TsacCellboard2Version: 6 TsacMainboard
 SG_ major : 0|16@1+ (1,0) [0|65535] "U"  Vector__XXX
 SG_ minor : 16|16@1+ (1,0) [0|65535] "U"  Vector__XXX
 SG_ patch : 32|16@1+ (1,0) [0|65535] "U"  Vector__XXX

BO_ 1690 TsacCellboard2VersionInfo: 8 TsacMainboard
 SG_ buildTime : 0|32@1+ (1,0) [0|4294967295] "s"  Vector__XXX
 SG_ commitHash : 32|28@1+ (1,0) [0|268435455] "U"  Vector__XXX
 SG_ dirty : 60|1@1+ (1,0) [0|1] "bool"  Vector__XXX

BO_ 1691 TsacCellboard2LibcanVersion: 6 TsacMainboard
 SG_ major : 0|16@1+ (1,0) [0|65535] "U"  Vector__XXX
 SG_ minor : 16|16@1+ (1,0) [0|65535] "U"  Vector__XXX
 SG_ patch : 32|16@1+ (1,0) [0|65535] "U"  Vector__XXX

BO_ 1692 TsacCellboard2LibcanVersionInfo: 8 TsacMainboard
 SG_ generationTime : 0|32@1+ (1,0) [0|4294967295] "s"  Vector__XXX
 SG_ commitHash : 32|28@1+ (1,0) [0|268435455] "U"  Vector__XXX
 SG_ dirty : 60|1@1+ (1,0) [0|1] "bool"  Vector__XXX

BO_ 1693 TsacCellboard3Version: 6 TsacMainboard
 SG_ major : 0|16@1+ (1,0) [0|65535] "U"  Vector__XXX
 SG_ minor : 16|16@1+ (1,0) [0|65535] "U"  Vector__XXX
 SG_ patch : 32|16@1+ (1,0) [0|65535] "U"  Vector__XXX

BO_ 1694 TsacCellboard3VersionInfo: 8 TsacMainboard
 SG_ buildTime : 0|32@1+ (1,0) [0|4294967295] "s"  Vector__XXX
 SG_ commitHash : 32|28@1+ (1,0) [0|268435455] "U"  Vector__XXX
 SG_ dirty : 60|1@1+ (1,0) [0|1] "bool"  Vector__XXX

BO_ 1695 TsacCellboard3LibcanVersion: 6 TsacMainboard
 SG_ major : 0|16@1+ (1,0) [0|65535] "U"  Vector__XXX
 SG_ minor : 16|16@1+ (1,0) [0|65535] "U"  Vector__XXX
 SG_ patch : 32|16@1+ (1,0) [0|65535] "U"  Vector__XXX

BO_ 1696 TsacCellboard3LibcanVersionInfo: 8 TsacMainboard
 SG_ generationTime : 0|32@1+ (1,0) [0|4294967295] "s"  Vector__XXX
 SG_ commitHash : 32|28@1+ (1,0) [0|268435455] "U"  Vector__XXX
 SG_ dirty : 60|1@1+ (1,0) [0|1] "bool"  Vector__XXX

BO_ 1697 TsacCellboard4Version: 6 TsacMainboard
 SG_ major : 0|16@1+ (1,0) [0|65535] "U"  Vector__XXX
 SG_ minor : 16|16@1+ (1,0) [0|65535] "U"  Vector__XXX
 SG_ patch : 32|16@1+ (1,0) [0|65535] "U"  Vector__XXX

BO_ 1698 TsacCellboard4VersionInfo: 8 TsacMainboard
 SG_ buildTime : 0|32@1+ (1,0) [0|4294967295] "s"  Vector__XXX
 SG_ commitHash : 32|28@1+ (1,0) [0|268435455] "U"  Vector__XXX
 SG_ dirty : 60|1@1+ (1,0) [0|1] "bool"  Vector__XXX

BO_ 1699 TsacCellboard4LibcanVersion: 6 TsacMainboard
 SG_ major : 0|16@1+ (1,0) [0|65535] "U"  Vector__XXX
 SG_ minor : 16|16@1+ (1,0) [0|65535] "U"  Vector__XXX
 SG_ patch : 32|16@1+ (1,0) [0|65535] "U"  Vector__XXX

BO_ 1700 TsacCellboard4LibcanVersionInfo: 8 TsacMainboard
 SG_ generationTime : 0|32@1+ (1,0) [0|4294967295] "s"  Vector__XXX
 SG_ commitHash : 32|28@1+ (1,0) [0|268435455] "U"  Vector__XXX
 SG_ dirty : 60|1@1+ (1,0) [0|1] "bool"  Vector__XXX

BO_ 1701 TsacCellboard5Version: 6 TsacMainboard
 SG_ major : 0|16@1+ (1,0) [0|65535] "U"  Vector__XXX
 SG_ minor : 16|16@1+ (1,0) [0|65535] "U"  Vector__XXX
 SG_ patch : 32|16@1+ (1,0) [0|65535] "U"  Vector__XXX

BO_ 1702 TsacCellboard5VersionInfo: 8 TsacMainboard
 SG_ buildTime : 0|32@1+ (1,0) [0|4294967295] "s"  Vector__XXX
 SG_ commitHash : 32|28@1+ (1,0) [0|268435455] "U"  Vector__XXX
 SG_ dirty : 60|1@1+ (1,0) [0|1] "bool"  Vector__XXX

BO_ 1703 TsacCellboard5LibcanVersion: 6 TsacMainboard
 SG_ major : 0|16@1+ (1,0) [0|65535] "U"  Vector__XXX
 SG_ minor : 16|16@1+ (1,0) [0|65535] "U"  Vector__XXX
 SG_ patch : 32|16@1+ (1,0) [0|65535] "U"  Vector__XXX

BO_ 1704 TsacCellboard5LibcanVersionInfo: 8 TsacMainboard
 SG_ generationTime : 0|32@1+ (1,0) [0|4294967295] "s"  Vector__XXX
 SG_ commitHash : 32|28@1+ (1,0) [0|268435455] "U"  Vector__XXX
 SG_ dirty : 60|1@1+ (1,0) [0|1] "bool"  Vector__XXX

BO_ 1705 TsacCellboard6Version: 6 TsacMainboard
 SG_ major : 0|16@1+ (1,0) [0|65535] "U"  Vector__XXX
 SG_ minor : 16|16@1+ (1,0) [0|65535] "U"  Vector__XXX
 SG_ patch : 32|16@1+ (1,0) [0|65535] "U"  Vector__XXX

BO_ 1706 TsacCellboard6VersionInfo: 8 TsacMainboard
 SG_ buildTime : 0|32@1+ (1,0) [0|4294967295] "s"  Vector__XXX
 SG_ commitHash : 32|28@1+ (1,0) [0|268435455] "U"  Vector__XXX
 SG_ dirty : 60|1@1+ (1,0) [0|1] "bool"  Vector__XXX

BO_ 1707 TsacCellboard6LibcanVersion: 6 TsacMainboard
 SG_ major : 0|16@1+ (1,0) [0|65535] "U"  Vector__XXX
 SG_ minor : 16|16@1+ (1,0) [0|65535] "U"  Vector__XXX
 SG_ patch : 32|16@1+ (1,0) [0|65535] "U"  Vector__XXX

BO_ 1708 TsacCellboard6LibcanVersionInfo: 8 TsacMainboard
 SG_ generationTime : 0|32@1+ (1,0) [0|4294967295] "s"  Vector__XXX
 SG_ commitHash : 32|28@1+ (1,0) [0|268435455] "U"  Vector__XXX
 SG_ dirty : 60|1@1+ (1,0) [0|1] "bool"  Vector__XXX

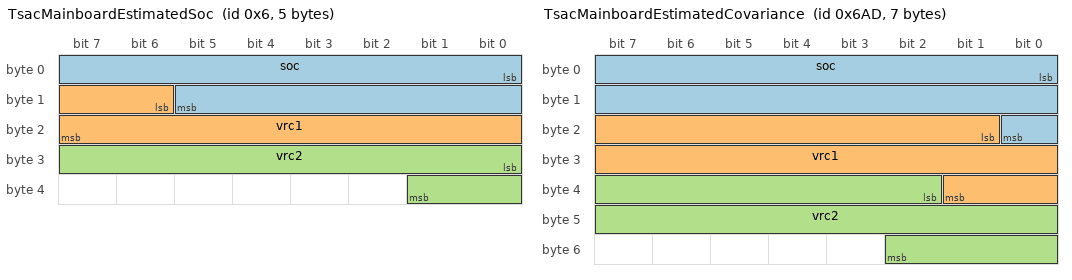
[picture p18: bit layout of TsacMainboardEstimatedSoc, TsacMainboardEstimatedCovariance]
BO_ 6 TsacMainboardEstimatedSoc: 5 TsacMainboard
 SG_ soc : 0|14@1+ (0.0001,0) [0|1] "U"  Vector__XXX
 SG_ vrc1 : 14|10@1+ (0.005,0) [0|4.5] "V"  Vector__XXX
 SG_ vrc2 : 24|10@1+ (0.005,0) [0|4.5] "V"  Vector__XXX

BO_ 1709 TsacMainboardEstimatedCovariance: 7 TsacMainboard
 SG_ soc : 0|17@1+ (0.0001,0) [0|10] "U"  Vector__XXX
 SG_ vrc1 : 17|17@1+ (0.001,0) [0|100] "V"  Vector__XXX
 SG_ vrc2 : 34|17@1+ (0.001,0) [0|100] "V"  Vector__XXX

BO_ 413 TsacMainboardCurrentInfo: 3 TsacMainboard
 SG_ current : 0|12@1+ (0.1,-150) [-150|250] "A"  Vector__XXX
 SG_ power : 12|11@1+ (0.1,-100) [-100|100] "kW"  Vector__XXX

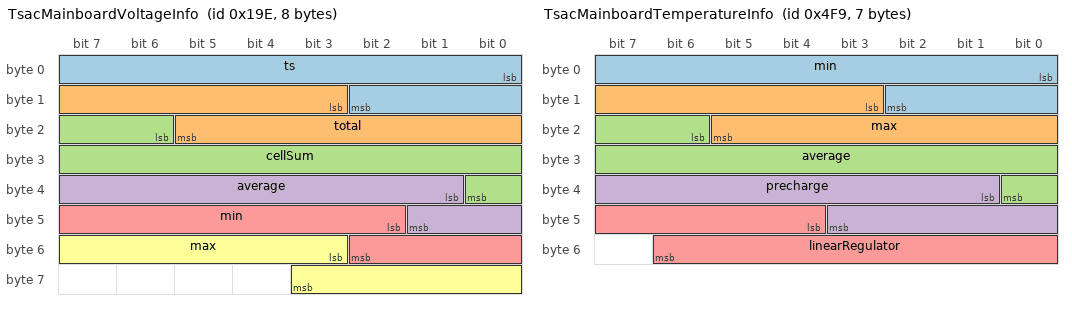
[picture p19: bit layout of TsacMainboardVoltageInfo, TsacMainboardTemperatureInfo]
BO_ 414 TsacMainboardVoltageInfo: 8 TsacMainboard
 SG_ ts : 0|11@1+ (0.5,0) [0|650] "V"  Vector__XXX
 SG_ total : 11|11@1+ (0.5,0) [0|650] "V"  Vector__XXX
 SG_ cellSum : 22|11@1+ (0.5,0) [0|650] "V"  Vector__XXX
 SG_ average : 33|9@1+ (0.005,2) [2|4.5] "V"  Vector__XXX
 SG_ min : 42|9@1+ (0.005,2) [2|4.5] "V"  Vector__XXX
 SG_ max : 51|9@1+ (0.005,2) [2|4.5] "V"  Vector__XXX

BO_ 1267 TsacCellboard1Voltage: 8 TsacMainboard
 SG_ group M : 0|3@1+ (1,0) [0|5] "U"  Vector__XXX
 SG_ cell1 m0 : 3|9@1+ (0.005,2) [2|4.5] "V"  Vector__XXX
 SG_ cell2 m0 : 12|9@1+ (0.005,2) [2|4.5] "V"  Vector__XXX
 SG_ cell3 m0 : 21|9@1+ (0.005,2) [2|4.5] "V"  Vector__XXX
 SG_ cell4 m0 : 30|9@1+ (0.005,2) [2|4.5] "V"  Vector__XXX
 SG_ cell5 m0 : 39|9@1+ (0.005,2) [2|4.5] "V"  Vector__XXX
 SG_ cell6 m0 : 48|9@1+ (0.005,2) [2|4.5] "V"  Vector__XXX
 SG_ cell7 m1 : 3|9@1+ (0.005,2) [2|4.5] "V"  Vector__XXX
 SG_ cell8 m1 : 12|9@1+ (0.005,2) [2|4.5] "V"  Vector__XXX
 SG_ cell9 m1 : 21|9@1+ (0.005,2) [2|4.5] "V"  Vector__XXX
 SG_ cell10 m1 : 30|9@1+ (0.005,2) [2|4.5] "V"  Vector__XXX
 SG_ cell11 m1 : 39|9@1+ (0.005,2) [2|4.5] "V"  Vector__XXX
 SG_ cell12 m1 : 48|9@1+ (0.005,2) [2|4.5] "V"  Vector__XXX
 SG_ cell13 m2 : 3|9@1+ (0.005,2) [2|4.5] "V"  Vector__XXX
 SG_ cell14 m2 : 12|9@1+ (0.005,2) [2|4.5] "V"  Vector__XXX
 SG_ cell15 m2 : 21|9@1+ (0.005,2) [2|4.5] "V"  Vector__XXX
 SG_ cell16 m2 : 30|9@1+ (0.005,2) [2|4.5] "V"  Vector__XXX
 SG_ cell17 m2 : 39|9@1+ (0.005,2) [2|4.5] "V"  Vector__XXX
 SG_ cell18 m2 : 48|9@1+ (0.005,2) [2|4.5] "V"  Vector__XXX
 SG_ cell19 m3 : 3|9@1+ (0.005,2) [2|4.5] "V"  Vector__XXX
 SG_ cell20 m3 : 12|9@1+ (0.005,2) [2|4.5] "V"  Vector__XXX
 SG_ cell21 m3 : 21|9@1+ (0.005,2) [2|4.5] "V"  Vector__XXX
 SG_ cell22 m3 : 30|9@1+ (0.005,2) [2|4.5] "V"  Vector__XXX
 SG_ cell23 m3 : 39|9@1+ (0.005,2) [2|4.5] "V"  Vector__XXX
 SG_ cell24 m3 : 48|9@1+ (0.005,2) [2|4.5] "V"  Vector__XXX

BO_ 1268 TsacCellboard2Voltage: 8 TsacMainboard
 SG_ group M : 0|3@1+ (1,0) [0|5] "U"  Vector__XXX
 SG_ cell1 m0 : 3|9@1+ (0.005,2) [2|4.5] "V"  Vector__XXX
 SG_ cell2 m0 : 12|9@1+ (0.005,2) [2|4.5] "V"  Vector__XXX
 SG_ cell3 m0 : 21|9@1+ (0.005,2) [2|4.5] "V"  Vector__XXX
 SG_ cell4 m0 : 30|9@1+ (0.005,2) [2|4.5] "V"  Vector__XXX
 SG_ cell5 m0 : 39|9@1+ (0.005,2) [2|4.5] "V"  Vector__XXX
 SG_ cell6 m0 : 48|9@1+ (0.005,2) [2|4.5] "V"  Vector__XXX
 SG_ cell7 m1 : 3|9@1+ (0.005,2) [2|4.5] "V"  Vector__XXX
 SG_ cell8 m1 : 12|9@1+ (0.005,2) [2|4.5] "V"  Vector__XXX
 SG_ cell9 m1 : 21|9@1+ (0.005,2) [2|4.5] "V"  Vector__XXX
 SG_ cell10 m1 : 30|9@1+ (0.005,2) [2|4.5] "V"  Vector__XXX
 SG_ cell11 m1 : 39|9@1+ (0.005,2) [2|4.5] "V"  Vector__XXX
 SG_ cell12 m1 : 48|9@1+ (0.005,2) [2|4.5] "V"  Vector__XXX
 SG_ cell13 m2 : 3|9@1+ (0.005,2) [2|4.5] "V"  Vector__XXX
 SG_ cell14 m2 : 12|9@1+ (0.005,2) [2|4.5] "V"  Vector__XXX
 SG_ cell15 m2 : 21|9@1+ (0.005,2) [2|4.5] "V"  Vector__XXX
 SG_ cell16 m2 : 30|9@1+ (0.005,2) [2|4.5] "V"  Vector__XXX
 SG_ cell17 m2 : 39|9@1+ (0.005,2) [2|4.5] "V"  Vector__XXX
 SG_ cell18 m2 : 48|9@1+ (0.005,2) [2|4.5] "V"  Vector__XXX
 SG_ cell19 m3 : 3|9@1+ (0.005,2) [2|4.5] "V"  Vector__XXX
 SG_ cell20 m3 : 12|9@1+ (0.005,2) [2|4.5] "V"  Vector__XXX
 SG_ cell21 m3 : 21|9@1+ (0.005,2) [2|4.5] "V"  Vector__XXX
 SG_ cell22 m3 : 30|9@1+ (0.005,2) [2|4.5] "V"  Vector__XXX
 SG_ cell23 m3 : 39|9@1+ (0.005,2) [2|4.5] "V"  Vector__XXX
 SG_ cell24 m3 : 48|9@1+ (0.005,2) [2|4.5] "V"  Vector__XXX

BO_ 1269 TsacCellboard3Voltage: 8 TsacMainboard
 SG_ group M : 0|3@1+ (1,0) [0|5] "U"  Vector__XXX
 SG_ cell1 m0 : 3|9@1+ (0.005,2) [2|4.5] "V"  Vector__XXX
 SG_ cell2 m0 : 12|9@1+ (0.005,2) [2|4.5] "V"  Vector__XXX
 SG_ cell3 m0 : 21|9@1+ (0.005,2) [2|4.5] "V"  Vector__XXX
 SG_ cell4 m0 : 30|9@1+ (0.005,2) [2|4.5] "V"  Vector__XXX
 SG_ cell5 m0 : 39|9@1+ (0.005,2) [2|4.5] "V"  Vector__XXX
 SG_ cell6 m0 : 48|9@1+ (0.005,2) [2|4.5] "V"  Vector__XXX
 SG_ cell7 m1 : 3|9@1+ (0.005,2) [2|4.5] "V"  Vector__XXX
 SG_ cell8 m1 : 12|9@1+ (0.005,2) [2|4.5] "V"  Vector__XXX
 SG_ cell9 m1 : 21|9@1+ (0.005,2) [2|4.5] "V"  Vector__XXX
 SG_ cell10 m1 : 30|9@1+ (0.005,2) [2|4.5] "V"  Vector__XXX
 SG_ cell11 m1 : 39|9@1+ (0.005,2) [2|4.5] "V"  Vector__XXX
 SG_ cell12 m1 : 48|9@1+ (0.005,2) [2|4.5] "V"  Vector__XXX
 SG_ cell13 m2 : 3|9@1+ (0.005,2) [2|4.5] "V"  Vector__XXX
 SG_ cell14 m2 : 12|9@1+ (0.005,2) [2|4.5] "V"  Vector__XXX
 SG_ cell15 m2 : 21|9@1+ (0.005,2) [2|4.5] "V"  Vector__XXX
 SG_ cell16 m2 : 30|9@1+ (0.005,2) [2|4.5] "V"  Vector__XXX
 SG_ cell17 m2 : 39|9@1+ (0.005,2) [2|4.5] "V"  Vector__XXX
 SG_ cell18 m2 : 48|9@1+ (0.005,2) [2|4.5] "V"  Vector__XXX
 SG_ cell19 m3 : 3|9@1+ (0.005,2) [2|4.5] "V"  Vector__XXX
 SG_ cell20 m3 : 12|9@1+ (0.005,2) [2|4.5] "V"  Vector__XXX
 SG_ cell21 m3 : 21|9@1+ (0.005,2) [2|4.5] "V"  Vector__XXX
 SG_ cell22 m3 : 30|9@1+ (0.005,2) [2|4.5] "V"  Vector__XXX
 SG_ cell23 m3 : 39|9@1+ (0.005,2) [2|4.5] "V"  Vector__XXX
 SG_ cell24 m3 : 48|9@1+ (0.005,2) [2|4.5] "V"  Vector__XXX

BO_ 1270 TsacCellboard4Voltage: 8 TsacMainboard
 SG_ group M : 0|3@1+ (1,0) [0|5] "U"  Vector__XXX
 SG_ cell1 m0 : 3|9@1+ (0.005,2) [2|4.5] "V"  Vector__XXX
 SG_ cell2 m0 : 12|9@1+ (0.005,2) [2|4.5] "V"  Vector__XXX
 SG_ cell3 m0 : 21|9@1+ (0.005,2) [2|4.5] "V"  Vector__XXX
 SG_ cell4 m0 : 30|9@1+ (0.005,2) [2|4.5] "V"  Vector__XXX
 SG_ cell5 m0 : 39|9@1+ (0.005,2) [2|4.5] "V"  Vector__XXX
 SG_ cell6 m0 : 48|9@1+ (0.005,2) [2|4.5] "V"  Vector__XXX
 SG_ cell7 m1 : 3|9@1+ (0.005,2) [2|4.5] "V"  Vector__XXX
 SG_ cell8 m1 : 12|9@1+ (0.005,2) [2|4.5] "V"  Vector__XXX
 SG_ cell9 m1 : 21|9@1+ (0.005,2) [2|4.5] "V"  Vector__XXX
 SG_ cell10 m1 : 30|9@1+ (0.005,2) [2|4.5] "V"  Vector__XXX
 SG_ cell11 m1 : 39|9@1+ (0.005,2) [2|4.5] "V"  Vector__XXX
 SG_ cell12 m1 : 48|9@1+ (0.005,2) [2|4.5] "V"  Vector__XXX
 SG_ cell13 m2 : 3|9@1+ (0.005,2) [2|4.5] "V"  Vector__XXX
 SG_ cell14 m2 : 12|9@1+ (0.005,2) [2|4.5] "V"  Vector__XXX
 SG_ cell15 m2 : 21|9@1+ (0.005,2) [2|4.5] "V"  Vector__XXX
 SG_ cell16 m2 : 30|9@1+ (0.005,2) [2|4.5] "V"  Vector__XXX
 SG_ cell17 m2 : 39|9@1+ (0.005,2) [2|4.5] "V"  Vector__XXX
 SG_ cell18 m2 : 48|9@1+ (0.005,2) [2|4.5] "V"  Vector__XXX
 SG_ cell19 m3 : 3|9@1+ (0.005,2) [2|4.5] "V"  Vector__XXX
 SG_ cell20 m3 : 12|9@1+ (0.005,2) [2|4.5] "V"  Vector__XXX
 SG_ cell21 m3 : 21|9@1+ (0.005,2) [2|4.5] "V"  Vector__XXX
 SG_ cell22 m3 : 30|9@1+ (0.005,2) [2|4.5] "V"  Vector__XXX
 SG_ cell23 m3 : 39|9@1+ (0.005,2) [2|4.5] "V"  Vector__XXX
 SG_ cell24 m3 : 48|9@1+ (0.005,2) [2|4.5] "V"  Vector__XXX

BO_ 1271 TsacCellboard5Voltage: 8 TsacMainboard
 SG_ group M : 0|3@1+ (1,0) [0|5] "U"  Vector__XXX
 SG_ cell1 m0 : 3|9@1+ (0.005,2) [2|4.5] "V"  Vector__XXX
 SG_ cell2 m0 : 12|9@1+ (0.005,2) [2|4.5] "V"  Vector__XXX
 SG_ cell3 m0 : 21|9@1+ (0.005,2) [2|4.5] "V"  Vector__XXX
 SG_ cell4 m0 : 30|9@1+ (0.005,2) [2|4.5] "V"  Vector__XXX
 SG_ cell5 m0 : 39|9@1+ (0.005,2) [2|4.5] "V"  Vector__XXX
 SG_ cell6 m0 : 48|9@1+ (0.005,2) [2|4.5] "V"  Vector__XXX
 SG_ cell7 m1 : 3|9@1+ (0.005,2) [2|4.5] "V"  Vector__XXX
 SG_ cell8 m1 : 12|9@1+ (0.005,2) [2|4.5] "V"  Vector__XXX
 SG_ cell9 m1 : 21|9@1+ (0.005,2) [2|4.5] "V"  Vector__XXX
 SG_ cell10 m1 : 30|9@1+ (0.005,2) [2|4.5] "V"  Vector__XXX
 SG_ cell11 m1 : 39|9@1+ (0.005,2) [2|4.5] "V"  Vector__XXX
 SG_ cell12 m1 : 48|9@1+ (0.005,2) [2|4.5] "V"  Vector__XXX
 SG_ cell13 m2 : 3|9@1+ (0.005,2) [2|4.5] "V"  Vector__XXX
 SG_ cell14 m2 : 12|9@1+ (0.005,2) [2|4.5] "V"  Vector__XXX
 SG_ cell15 m2 : 21|9@1+ (0.005,2) [2|4.5] "V"  Vector__XXX
 SG_ cell16 m2 : 30|9@1+ (0.005,2) [2|4.5] "V"  Vector__XXX
 SG_ cell17 m2 : 39|9@1+ (0.005,2) [2|4.5] "V"  Vector__XXX
 SG_ cell18 m2 : 48|9@1+ (0.005,2) [2|4.5] "V"  Vector__XXX
 SG_ cell19 m3 : 3|9@1+ (0.005,2) [2|4.5] "V"  Vector__XXX
 SG_ cell20 m3 : 12|9@1+ (0.005,2) [2|4.5] "V"  Vector__XXX
 SG_ cell21 m3 : 21|9@1+ (0.005,2) [2|4.5] "V"  Vector__XXX
 SG_ cell22 m3 : 30|9@1+ (0.005,2) [2|4.5] "V"  Vector__XXX
 SG_ cell23 m3 : 39|9@1+ (0.005,2) [2|4.5] "V"  Vector__XXX
 SG_ cell24 m3 : 48|9@1+ (0.005,2) [2|4.5] "V"  Vector__XXX

BO_ 1272 TsacCellboard6Voltage: 8 TsacMainboard
 SG_ group M : 0|3@1+ (1,0) [0|5] "U"  Vector__XXX
 SG_ cell1 m0 : 3|9@1+ (0.005,2) [2|4.5] "V"  Vector__XXX
 SG_ cell2 m0 : 12|9@1+ (0.005,2) [2|4.5] "V"  Vector__XXX
 SG_ cell3 m0 : 21|9@1+ (0.005,2) [2|4.5] "V"  Vector__XXX
 SG_ cell4 m0 : 30|9@1+ (0.005,2) [2|4.5] "V"  Vector__XXX
 SG_ cell5 m0 : 39|9@1+ (0.005,2) [2|4.5] "V"  Vector__XXX
 SG_ cell6 m0 : 48|9@1+ (0.005,2) [2|4.5] "V"  Vector__XXX
 SG_ cell7 m1 : 3|9@1+ (0.005,2) [2|4.5] "V"  Vector__XXX
 SG_ cell8 m1 : 12|9@1+ (0.005,2) [2|4.5] "V"  Vector__XXX
 SG_ cell9 m1 : 21|9@1+ (0.005,2) [2|4.5] "V"  Vector__XXX
 SG_ cell10 m1 : 30|9@1+ (0.005,2) [2|4.5] "V"  Vector__XXX
 SG_ cell11 m1 : 39|9@1+ (0.005,2) [2|4.5] "V"  Vector__XXX
 SG_ cell12 m1 : 48|9@1+ (0.005,2) [2|4.5] "V"  Vector__XXX
 SG_ cell13 m2 : 3|9@1+ (0.005,2) [2|4.5] "V"  Vector__XXX
 SG_ cell14 m2 : 12|9@1+ (0.005,2) [2|4.5] "V"  Vector__XXX
 SG_ cell15 m2 : 21|9@1+ (0.005,2) [2|4.5] "V"  Vector__XXX
 SG_ cell16 m2 : 30|9@1+ (0.005,2) [2|4.5] "V"  Vector__XXX
 SG_ cell17 m2 : 39|9@1+ (0.005,2) [2|4.5] "V"  Vector__XXX
 SG_ cell18 m2 : 48|9@1+ (0.005,2) [2|4.5] "V"  Vector__XXX
 SG_ cell19 m3 : 3|9@1+ (0.005,2) [2|4.5] "V"  Vector__XXX
 SG_ cell20 m3 : 12|9@1+ (0.005,2) [2|4.5] "V"  Vector__XXX
 SG_ cell21 m3 : 21|9@1+ (0.005,2) [2|4.5] "V"  Vector__XXX
 SG_ cell22 m3 : 30|9@1+ (0.005,2) [2|4.5] "V"  Vector__XXX
 SG_ cell23 m3 : 39|9@1+ (0.005,2) [2|4.5] "V"  Vector__XXX
 SG_ cell24 m3 : 48|9@1+ (0.005,2) [2|4.5] "V"  Vector__XXX

BO_ 1273 TsacMainboardTemperatureInfo: 7 Mainboard
 SG_ min : 0|11@1+ (0.1,-50) [-50|125] "degC"  Vector__XXX
 SG_ max : 11|11@1+ (0.1,-50) [-50|125] "degC"  Vector__XXX
 SG_ average : 22|11@1+ (0.1,-50) [-50|125] "degC"  Vector__XXX
 SG_ precharge : 33|11@1+ (0.1,-50) [-50|125] "degC"  Vector__XXX
 SG_ linearRegulator : 44|11@1+ (0.1,-50) [-50|125] "degC"  Vector__XXX

BO_ 1274 TsacCellboard1Temperature: 8 TsacMainboard
 SG_ group M : 0|4@1+ (1,0) [0|9] "U"  Vector__XXX
 SG_ cell1 m0 : 4|11@1+ (0.1,-50) [-50|125] "degC"  Vector__XXX
 SG_ cell2 m0 : 15|11@1+ (0.1,-50) [-50|125] "degC"  Vector__XXX
 SG_ cell3 m0 : 26|11@1+ (0.1,-50) [-50|125] "degC"  Vector__XXX
 SG_ cell4 m0 : 37|11@1+ (0.1,-50) [-50|125] "degC"  Vector__XXX
 SG_ cell5 m0 : 48|11@1+ (0.1,-50) [-50|125] "degC"  Vector__XXX
 SG_ cell6 m1 : 4|11@1+ (0.1,-50) [-50|125] "degC"  Vector__XXX
 SG_ cell7 m1 : 15|11@1+ (0.1,-50) [-50|126] "degC"  Vector__XXX
 SG_ cell8 m1 : 26|11@1+ (0.1,-50) [-50|125] "degC"  Vector__XXX
 SG_ cell9 m1 : 37|11@1+ (0.1,-50) [-50|125] "degC"  Vector__XXX
 SG_ cell10 m1 : 48|11@1+ (0.1,-50) [-50|125] "degC"  Vector__XXX
 SG_ cell11 m2 : 4|11@1+ (0.1,-50) [-50|125] "degC"  Vector__XXX
 SG_ cell12 m2 : 15|11@1+ (0.1,-50) [-50|125] "degC"  Vector__XXX
 SG_ cell13 m2 : 26|11@1+ (0.1,-50) [-50|125] "degC"  Vector__XXX
 SG_ cell14 m2 : 37|11@1+ (0.1,-50) [-50|125] "degC"  Vector__XXX
 SG_ cell15 m2 : 48|11@1+ (0.1,-50) [-50|125] "degC"  Vector__XXX
 SG_ cell16 m3 : 4|11@1+ (0.1,-50) [-50|125] "degC"  Vector__XXX
 SG_ cell17 m3 : 15|11@1+ (0.1,-50) [-50|125] "degC"  Vector__XXX
 SG_ cell18 m3 : 26|11@1+ (0.1,-50) [-50|125] "degC"  Vector__XXX
 SG_ cell19 m3 : 37|11@1+ (0.1,-50) [-50|125] "degC"  Vector__XXX
 SG_ cell20 m3 : 48|11@1+ (0.1,-50) [-50|125] "degC"  Vector__XXX
 SG_ cell21 m4 : 4|11@1+ (0.1,-50) [-50|125] "degC"  Vector__XXX
 SG_ cell22 m4 : 15|11@1+ (0.1,-50) [-50|125] "degC"  Vector__XXX
 SG_ cell23 m4 : 26|11@1+ (0.1,-50) [-50|125] "degC"  Vector__XXX
 SG_ cell24 m4 : 37|11@1+ (0.1,-50) [-50|125] "degC"  Vector__XXX
 SG_ cell25 m4 : 48|11@1+ (0.1,-50) [-50|125] "degC"  Vector__XXX
 SG_ cell26 m5 : 4|11@1+ (0.1,-50) [-50|125] "degC"  Vector__XXX
 SG_ cell27 m5 : 15|11@1+ (0.1,-50) [-50|125] "degC"  Vector__XXX
 SG_ cell28 m5 : 26|11@1+ (0.1,-50) [-50|125] "degC"  Vector__XXX
 SG_ cell29 m5 : 37|11@1+ (0.1,-50) [-50|125] "degC"  Vector__XXX
 SG_ cell30 m5 : 48|11@1+ (0.1,-50) [-50|125] "degC"  Vector__XXX
 SG_ cell31 m6 : 4|11@1+ (0.1,-50) [-50|125] "degC"  Vector__XXX
 SG_ cell32 m6 : 15|11@1+ (0.1,-50) [-50|125] "degC"  Vector__XXX
 SG_ cell33 m6 : 26|11@1+ (0.1,-50) [-50|125] "degC"  Vector__XXX
 SG_ cell34 m6 : 37|11@1+ (0.1,-50) [-50|125] "degC"  Vector__XXX
 SG_ cell35 m6 : 48|11@1+ (0.1,-50) [-50|125] "degC"  Vector__XXX
 SG_ cell36 m7 : 4|11@1+ (0.1,-50) [-50|125] "degC"  Vector__XXX
 SG_ cell37 m7 : 15|11@1+ (0.1,-50) [-50|125] "degC"  Vector__XXX
 SG_ cell38 m7 : 26|11@1+ (0.1,-50) [-50|125] "degC"  Vector__XXX
 SG_ cell39 m7 : 37|11@1+ (0.1,-50) [-50|125] "degC"  Vector__XXX
 SG_ cell40 m7 : 48|11@1+ (0.1,-50) [-50|125] "degC"  Vector__XXX
 SG_ cell41 m8 : 4|11@1+ (0.1,-50) [-50|125] "degC"  Vector__XXX
 SG_ cell42 m8 : 15|11@1+ (0.1,-50) [-50|125] "degC"  Vector__XXX
 SG_ cell43 m8 : 26|11@1+ (0.1,-50) [-50|125] "degC"  Vector__XXX
 SG_ cell44 m8 : 37|11@1+ (0.1,-50) [-50|125] "degC"  Vector__XXX
 SG_ cell45 m8 : 48|11@1+ (0.1,-50) [-50|125] "degC"  Vector__XXX
 SG_ cell46 m9 : 4|11@1+ (0.1,-50) [-50|125] "degC"  Vector__XXX
 SG_ cell47 m9 : 15|11@1+ (0.1,-50) [-50|125] "degC"  Vector__XXX
 SG_ cell48 m9 : 26|11@1+ (0.1,-50) [-50|125] "degC"  Vector__XXX

BO_ 1275 TsacCellboard2Temperature: 8 TsacMainboard
 SG_ group M : 0|4@1+ (1,0) [0|9] "U"  Vector__XXX
 SG_ cell1 m0 : 4|11@1+ (0.1,-50) [-50|125] "degC"  Vector__XXX
 SG_ cell2 m0 : 15|11@1+ (0.1,-50) [-50|125] "degC"  Vector__XXX
 SG_ cell3 m0 : 26|11@1+ (0.1,-50) [-50|125] "degC"  Vector__XXX
 SG_ cell4 m0 : 37|11@1+ (0.1,-50) [-50|125] "degC"  Vector__XXX
 SG_ cell5 m0 : 48|11@1+ (0.1,-50) [-50|125] "degC"  Vector__XXX
 SG_ cell6 m1 : 4|11@1+ (0.1,-50) [-50|125] "degC"  Vector__XXX
 SG_ cell7 m1 : 15|11@1+ (0.1,-50) [-50|126] "degC"  Vector__XXX
 SG_ cell8 m1 : 26|11@1+ (0.1,-50) [-50|125] "degC"  Vector__XXX
 SG_ cell9 m1 : 37|11@1+ (0.1,-50) [-50|125] "degC"  Vector__XXX
 SG_ cell10 m1 : 48|11@1+ (0.1,-50) [-50|125] "degC"  Vector__XXX
 SG_ cell11 m2 : 4|11@1+ (0.1,-50) [-50|125] "degC"  Vector__XXX
 SG_ cell12 m2 : 15|11@1+ (0.1,-50) [-50|125] "degC"  Vector__XXX
 SG_ cell13 m2 : 26|11@1+ (0.1,-50) [-50|125] "degC"  Vector__XXX
 SG_ cell14 m2 : 37|11@1+ (0.1,-50) [-50|125] "degC"  Vector__XXX
 SG_ cell15 m2 : 48|11@1+ (0.1,-50) [-50|125] "degC"  Vector__XXX
 SG_ cell16 m3 : 4|11@1+ (0.1,-50) [-50|125] "degC"  Vector__XXX
 SG_ cell17 m3 : 15|11@1+ (0.1,-50) [-50|125] "degC"  Vector__XXX
 SG_ cell18 m3 : 26|11@1+ (0.1,-50) [-50|125] "degC"  Vector__XXX
 SG_ cell19 m3 : 37|11@1+ (0.1,-50) [-50|125] "degC"  Vector__XXX
 SG_ cell20 m3 : 48|11@1+ (0.1,-50) [-50|125] "degC"  Vector__XXX
 SG_ cell21 m4 : 4|11@1+ (0.1,-50) [-50|125] "degC"  Vector__XXX
 SG_ cell22 m4 : 15|11@1+ (0.1,-50) [-50|125] "degC"  Vector__XXX
 SG_ cell23 m4 : 26|11@1+ (0.1,-50) [-50|125] "degC"  Vector__XXX
 SG_ cell24 m4 : 37|11@1+ (0.1,-50) [-50|125] "degC"  Vector__XXX
 SG_ cell25 m4 : 48|11@1+ (0.1,-50) [-50|125] "degC"  Vector__XXX
 SG_ cell26 m5 : 4|11@1+ (0.1,-50) [-50|125] "degC"  Vector__XXX
 SG_ cell27 m5 : 15|11@1+ (0.1,-50) [-50|125] "degC"  Vector__XXX
 SG_ cell28 m5 : 26|11@1+ (0.1,-50) [-50|125] "degC"  Vector__XXX
 SG_ cell29 m5 : 37|11@1+ (0.1,-50) [-50|125] "degC"  Vector__XXX
 SG_ cell30 m5 : 48|11@1+ (0.1,-50) [-50|125] "degC"  Vector__XXX
 SG_ cell31 m6 : 4|11@1+ (0.1,-50) [-50|125] "degC"  Vector__XXX
 SG_ cell32 m6 : 15|11@1+ (0.1,-50) [-50|125] "degC"  Vector__XXX
 SG_ cell33 m6 : 26|11@1+ (0.1,-50) [-50|125] "degC"  Vector__XXX
 SG_ cell34 m6 : 37|11@1+ (0.1,-50) [-50|125] "degC"  Vector__XXX
 SG_ cell35 m6 : 48|11@1+ (0.1,-50) [-50|125] "degC"  Vector__XXX
 SG_ cell36 m7 : 4|11@1+ (0.1,-50) [-50|125] "degC"  Vector__XXX
 SG_ cell37 m7 : 15|11@1+ (0.1,-50) [-50|125] "degC"  Vector__XXX
 SG_ cell38 m7 : 26|11@1+ (0.1,-50) [-50|125] "degC"  Vector__XXX
 SG_ cell39 m7 : 37|11@1+ (0.1,-50) [-50|125] "degC"  Vector__XXX
 SG_ cell40 m7 : 48|11@1+ (0.1,-50) [-50|125] "degC"  Vector__XXX
 SG_ cell41 m8 : 4|11@1+ (0.1,-50) [-50|125] "degC"  Vector__XXX
 SG_ cell42 m8 : 15|11@1+ (0.1,-50) [-50|125] "degC"  Vector__XXX
 SG_ cell43 m8 : 26|11@1+ (0.1,-50) [-50|125] "degC"  Vector__XXX
 SG_ cell44 m8 : 37|11@1+ (0.1,-50) [-50|125] "degC"  Vector__XXX
 SG_ cell45 m8 : 48|11@1+ (0.1,-50) [-50|125] "degC"  Vector__XXX
 SG_ cell46 m9 : 4|11@1+ (0.1,-50) [-50|125] "degC"  Vector__XXX
 SG_ cell47 m9 : 15|11@1+ (0.1,-50) [-50|125] "degC"  Vector__XXX
 SG_ cell48 m9 : 26|11@1+ (0.1,-50) [-50|125] "degC"  Vector__XXX

BO_ 1276 TsacCellboard3Temperature: 8 TsacMainboard
 SG_ group M : 0|4@1+ (1,0) [0|9] "U"  Vector__XXX
 SG_ cell1 m0 : 4|11@1+ (0.1,-50) [-50|125] "degC"  Vector__XXX
 SG_ cell2 m0 : 15|11@1+ (0.1,-50) [-50|125] "degC"  Vector__XXX
 SG_ cell3 m0 : 26|11@1+ (0.1,-50) [-50|125] "degC"  Vector__XXX
 SG_ cell4 m0 : 37|11@1+ (0.1,-50) [-50|125] "degC"  Vector__XXX
 SG_ cell5 m0 : 48|11@1+ (0.1,-50) [-50|125] "degC"  Vector__XXX
 SG_ cell6 m1 : 4|11@1+ (0.1,-50) [-50|125] "degC"  Vector__XXX
 SG_ cell7 m1 : 15|11@1+ (0.1,-50) [-50|126] "degC"  Vector__XXX
 SG_ cell8 m1 : 26|11@1+ (0.1,-50) [-50|125] "degC"  Vector__XXX
 SG_ cell9 m1 : 37|11@1+ (0.1,-50) [-50|125] "degC"  Vector__XXX
 SG_ cell10 m1 : 48|11@1+ (0.1,-50) [-50|125] "degC"  Vector__XXX
 SG_ cell11 m2 : 4|11@1+ (0.1,-50) [-50|125] "degC"  Vector__XXX
 SG_ cell12 m2 : 15|11@1+ (0.1,-50) [-50|125] "degC"  Vector__XXX
 SG_ cell13 m2 : 26|11@1+ (0.1,-50) [-50|125] "degC"  Vector__XXX
 SG_ cell14 m2 : 37|11@1+ (0.1,-50) [-50|125] "degC"  Vector__XXX
 SG_ cell15 m2 : 48|11@1+ (0.1,-50) [-50|125] "degC"  Vector__XXX
 SG_ cell16 m3 : 4|11@1+ (0.1,-50) [-50|125] "degC"  Vector__XXX
 SG_ cell17 m3 : 15|11@1+ (0.1,-50) [-50|125] "degC"  Vector__XXX
 SG_ cell18 m3 : 26|11@1+ (0.1,-50) [-50|125] "degC"  Vector__XXX
 SG_ cell19 m3 : 37|11@1+ (0.1,-50) [-50|125] "degC"  Vector__XXX
 SG_ cell20 m3 : 48|11@1+ (0.1,-50) [-50|125] "degC"  Vector__XXX
 SG_ cell21 m4 : 4|11@1+ (0.1,-50) [-50|125] "degC"  Vector__XXX
 SG_ cell22 m4 : 15|11@1+ (0.1,-50) [-50|125] "degC"  Vector__XXX
 SG_ cell23 m4 : 26|11@1+ (0.1,-50) [-50|125] "degC"  Vector__XXX
 SG_ cell24 m4 : 37|11@1+ (0.1,-50) [-50|125] "degC"  Vector__XXX
 SG_ cell25 m4 : 48|11@1+ (0.1,-50) [-50|125] "degC"  Vector__XXX
 SG_ cell26 m5 : 4|11@1+ (0.1,-50) [-50|125] "degC"  Vector__XXX
 SG_ cell27 m5 : 15|11@1+ (0.1,-50) [-50|125] "degC"  Vector__XXX
 SG_ cell28 m5 : 26|11@1+ (0.1,-50) [-50|125] "degC"  Vector__XXX
 SG_ cell29 m5 : 37|11@1+ (0.1,-50) [-50|125] "degC"  Vector__XXX
 SG_ cell30 m5 : 48|11@1+ (0.1,-50) [-50|125] "degC"  Vector__XXX
 SG_ cell31 m6 : 4|11@1+ (0.1,-50) [-50|125] "degC"  Vector__XXX
 SG_ cell32 m6 : 15|11@1+ (0.1,-50) [-50|125] "degC"  Vector__XXX
 SG_ cell33 m6 : 26|11@1+ (0.1,-50) [-50|125] "degC"  Vector__XXX
 SG_ cell34 m6 : 37|11@1+ (0.1,-50) [-50|125] "degC"  Vector__XXX
 SG_ cell35 m6 : 48|11@1+ (0.1,-50) [-50|125] "degC"  Vector__XXX
 SG_ cell36 m7 : 4|11@1+ (0.1,-50) [-50|125] "degC"  Vector__XXX
 SG_ cell37 m7 : 15|11@1+ (0.1,-50) [-50|125] "degC"  Vector__XXX
 SG_ cell38 m7 : 26|11@1+ (0.1,-50) [-50|125] "degC"  Vector__XXX
 SG_ cell39 m7 : 37|11@1+ (0.1,-50) [-50|125] "degC"  Vector__XXX
 SG_ cell40 m7 : 48|11@1+ (0.1,-50) [-50|125] "degC"  Vector__XXX
 SG_ cell41 m8 : 4|11@1+ (0.1,-50) [-50|125] "degC"  Vector__XXX
 SG_ cell42 m8 : 15|11@1+ (0.1,-50) [-50|125] "degC"  Vector__XXX
 SG_ cell43 m8 : 26|11@1+ (0.1,-50) [-50|125] "degC"  Vector__XXX
 SG_ cell44 m8 : 37|11@1+ (0.1,-50) [-50|125] "degC"  Vector__XXX
 SG_ cell45 m8 : 48|11@1+ (0.1,-50) [-50|125] "degC"  Vector__XXX
 SG_ cell46 m9 : 4|11@1+ (0.1,-50) [-50|125] "degC"  Vector__XXX
 SG_ cell47 m9 : 15|11@1+ (0.1,-50) [-50|125] "degC"  Vector__XXX
 SG_ cell48 m9 : 26|11@1+ (0.1,-50) [-50|125] "degC"  Vector__XXX

BO_ 1277 TsacCellboard4Temperature: 8 TsacMainboard
 SG_ group M : 0|4@1+ (1,0) [0|9] "U"  Vector__XXX
 SG_ cell1 m0 : 4|11@1+ (0.1,-50) [-50|125] "degC"  Vector__XXX
 SG_ cell2 m0 : 15|11@1+ (0.1,-50) [-50|125] "degC"  Vector__XXX
 SG_ cell3 m0 : 26|11@1+ (0.1,-50) [-50|125] "degC"  Vector__XXX
 SG_ cell4 m0 : 37|11@1+ (0.1,-50) [-50|125] "degC"  Vector__XXX
 SG_ cell5 m0 : 48|11@1+ (0.1,-50) [-50|125] "degC"  Vector__XXX
 SG_ cell6 m1 : 4|11@1+ (0.1,-50) [-50|125] "degC"  Vector__XXX
 SG_ cell7 m1 : 15|11@1+ (0.1,-50) [-50|126] "degC"  Vector__XXX
 SG_ cell8 m1 : 26|11@1+ (0.1,-50) [-50|125] "degC"  Vector__XXX
 SG_ cell9 m1 : 37|11@1+ (0.1,-50) [-50|125] "degC"  Vector__XXX
 SG_ cell10 m1 : 48|11@1+ (0.1,-50) [-50|125] "degC"  Vector__XXX
 SG_ cell11 m2 : 4|11@1+ (0.1,-50) [-50|125] "degC"  Vector__XXX
 SG_ cell12 m2 : 15|11@1+ (0.1,-50) [-50|125] "degC"  Vector__XXX
 SG_ cell13 m2 : 26|11@1+ (0.1,-50) [-50|125] "degC"  Vector__XXX
 SG_ cell14 m2 : 37|11@1+ (0.1,-50) [-50|125] "degC"  Vector__XXX
 SG_ cell15 m2 : 48|11@1+ (0.1,-50) [-50|125] "degC"  Vector__XXX
 SG_ cell16 m3 : 4|11@1+ (0.1,-50) [-50|125] "degC"  Vector__XXX
 SG_ cell17 m3 : 15|11@1+ (0.1,-50) [-50|125] "degC"  Vector__XXX
 SG_ cell18 m3 : 26|11@1+ (0.1,-50) [-50|125] "degC"  Vector__XXX
 SG_ cell19 m3 : 37|11@1+ (0.1,-50) [-50|125] "degC"  Vector__XXX
 SG_ cell20 m3 : 48|11@1+ (0.1,-50) [-50|125] "degC"  Vector__XXX
 SG_ cell21 m4 : 4|11@1+ (0.1,-50) [-50|125] "degC"  Vector__XXX
 SG_ cell22 m4 : 15|11@1+ (0.1,-50) [-50|125] "degC"  Vector__XXX
 SG_ cell23 m4 : 26|11@1+ (0.1,-50) [-50|125] "degC"  Vector__XXX
 SG_ cell24 m4 : 37|11@1+ (0.1,-50) [-50|125] "degC"  Vector__XXX
 SG_ cell25 m4 : 48|11@1+ (0.1,-50) [-50|125] "degC"  Vector__XXX
 SG_ cell26 m5 : 4|11@1+ (0.1,-50) [-50|125] "degC"  Vector__XXX
 SG_ cell27 m5 : 15|11@1+ (0.1,-50) [-50|125] "degC"  Vector__XXX
 SG_ cell28 m5 : 26|11@1+ (0.1,-50) [-50|125] "degC"  Vector__XXX
 SG_ cell29 m5 : 37|11@1+ (0.1,-50) [-50|125] "degC"  Vector__XXX
 SG_ cell30 m5 : 48|11@1+ (0.1,-50) [-50|125] "degC"  Vector__XXX
 SG_ cell31 m6 : 4|11@1+ (0.1,-50) [-50|125] "degC"  Vector__XXX
 SG_ cell32 m6 : 15|11@1+ (0.1,-50) [-50|125] "degC"  Vector__XXX
 SG_ cell33 m6 : 26|11@1+ (0.1,-50) [-50|125] "degC"  Vector__XXX
 SG_ cell34 m6 : 37|11@1+ (0.1,-50) [-50|125] "degC"  Vector__XXX
 SG_ cell35 m6 : 48|11@1+ (0.1,-50) [-50|125] "degC"  Vector__XXX
 SG_ cell36 m7 : 4|11@1+ (0.1,-50) [-50|125] "degC"  Vector__XXX
 SG_ cell37 m7 : 15|11@1+ (0.1,-50) [-50|125] "degC"  Vector__XXX
 SG_ cell38 m7 : 26|11@1+ (0.1,-50) [-50|125] "degC"  Vector__XXX
 SG_ cell39 m7 : 37|11@1+ (0.1,-50) [-50|125] "degC"  Vector__XXX
 SG_ cell40 m7 : 48|11@1+ (0.1,-50) [-50|125] "degC"  Vector__XXX
 SG_ cell41 m8 : 4|11@1+ (0.1,-50) [-50|125] "degC"  Vector__XXX
 SG_ cell42 m8 : 15|11@1+ (0.1,-50) [-50|125] "degC"  Vector__XXX
 SG_ cell43 m8 : 26|11@1+ (0.1,-50) [-50|125] "degC"  Vector__XXX
 SG_ cell44 m8 : 37|11@1+ (0.1,-50) [-50|125] "degC"  Vector__XXX
 SG_ cell45 m8 : 48|11@1+ (0.1,-50) [-50|125] "degC"  Vector__XXX
 SG_ cell46 m9 : 4|11@1+ (0.1,-50) [-50|125] "degC"  Vector__XXX
 SG_ cell47 m9 : 15|11@1+ (0.1,-50) [-50|125] "degC"  Vector__XXX
 SG_ cell48 m9 : 26|11@1+ (0.1,-50) [-50|125] "degC"  Vector__XXX

CM_ BU_ Cooling "The cooling board is a board that receives temperatures through sensors and CAN bus and modulates the fans and pumps accordingly.";
CM_ BU_ DasFront "Front Das is a board that receives data from multiple sources and sends it resampled to the main network.";
CM_ BU_ DasRear "Rear Das is a board that receives data from multiple sources and sends it resampled to the main network.";
CM_ BU_ Ecu "Ecu of the vehicle, talks to inverters and keeps car state.";
CM_ BU_ Imu "Inertial Measurement Unit, reads acceleration and angular velocity from the IMU sensor and provides it to other nodes.";
CM_ BU_ Lvac "Low Voltage Battery Management System (LVBMS) is a device that monitors and manages the low voltage battery system. It provides information about the battery status, voltage, current, and other parameters.";
CM_ BU_ Pedals "Pedals handle throttle and brake inputs, as well as BOTS and brake pressures.";
CM_ BU_ Pipo "Power-in Power-out (PIPO) is a device that controls the power supply to various components in the system. It monitors all the low voltage rails.";
CM_ BU_ Raspberry "Reads and writes";
CM_ BU_ Steering "Steering board control the steering actuator and reads the steering encoder.";
CM_ BU_ SteeringWheel "This node represents the steering wheel, which controls parameters in the car via its inputs and displays values in the screen.";
CM_ BU_ TsacMainboard "High Voltage Battery Management System (HVBMS) is a device that monitors and manages the high voltage battery system. It provides information about the battery status, voltage, current, and other parameters.";
BA_DEF_ SG_  "StandardName" STRING ;
BA_DEF_ SG_  "SignalTypeName" STRING ;
BA_DEF_ SG_  "SignalType" STRING ;
BA_DEF_ SG_  "Bitfield" STRING ;
BA_DEF_ BO_  "SystemMessageLongSymbol" STRING ;
BA_DEF_ SG_  "SystemSignalLongSymbol" STRING ;
BA_DEF_ BO_  "GenMsgCycleTime" INT 0 65535;
BA_DEF_DEF_  "StandardName" "";
BA_DEF_DEF_  "SignalTypeName" "";
BA_DEF_DEF_  "SignalType" "";
BA_DEF_DEF_  "Bitfield" "false";
BA_DEF_DEF_  "SystemMessageLongSymbol" "";
BA_DEF_DEF_  "SystemSignalLongSymbol" "";
BA_DEF_DEF_  "GenMsgCycleTime" 0;
BA_ "StandardName" SG_ 1260 z "VehicleState_Imu_angularRateZ_dps";
BA_ "StandardName" SG_ 1260 y "VehicleState_Imu_angularRateY_dps";
BA_ "StandardName" SG_ 1260 x "VehicleState_Imu_angularRateX_dps";
BA_ "StandardName" SG_ 1261 temperature "VehicleState_Imu_temperature_degC";
BA_ "StandardName" SG_ 1261 z "VehicleState_Imu_accelerationZ_g";
BA_ "StandardName" SG_ 1261 y "VehicleState_Imu_accelerationY_g";
BA_ "StandardName" SG_ 1261 x "VehicleState_Imu_accelerationX_g";
BA_ "StandardName" SG_ 1227 status "Kraken_DasRearFsm_status_enum";
BA_ "SignalTypeName" SG_ 1227 status "DasRearStatus";
BA_ "SignalType" SG_ 1227 status "enum";
BA_ "StandardName" SG_ 1636 patch "Kraken_DasRearVersion_patch_U";
BA_ "StandardName" SG_ 1636 minor "Kraken_DasRearVersion_minor_U";
BA_ "StandardName" SG_ 1636 major "Kraken_DasRearVersion_major_U";
BA_ "StandardName" SG_ 1637 dirty "Kraken_DasRearVersion_dirty_bool";
BA_ "SignalTypeName" SG_ 1637 dirty "bool";
BA_ "SignalType" SG_ 1637 dirty "bool";
BA_ "StandardName" SG_ 1637 commitHash "Kraken_DasRearVersion_commitHash_U";
BA_ "StandardName" SG_ 1637 buildTime "Kraken_DasRearVersion_buildTime_s";
BA_ "StandardName" SG_ 1638 patch "Kraken_DasRearVersionLibcan_patch_U";
BA_ "StandardName" SG_ 1638 minor "Kraken_DasRearVersionLibcan_minor_U";
BA_ "StandardName" SG_ 1638 major "Kraken_DasRearVersionLibcan_major_U";
BA_ "StandardName" SG_ 1639 dirty "Kraken_DasRearVersionLibcan_dirty_bool";
BA_ "SignalTypeName" SG_ 1639 dirty "bool";
BA_ "SignalType" SG_ 1639 dirty "bool";
BA_ "StandardName" SG_ 1639 commitHash "Kraken_DasRearVersionLibcan_commitHash_U";
BA_ "StandardName" SG_ 1639 generationTime "Kraken_DasRearVersionLibcan_generationTime_s";
BA_ "StandardName" SG_ 1228 rearLeft "Powertrain_TyreRL_temperature_degC";
BA_ "StandardName" SG_ 1228 rearRight "Powertrain_TyreRR_temperature_degC";
BA_ "StandardName" SG_ 1229 roll "Suspensions_RollR_travel_mm";
BA_ "StandardName" SG_ 1229 heave "Suspensions_HeaveR_travel_mm";
BA_ "StandardName" SG_ 1230 status "Kraken_PipoFsm_status_enum";
BA_ "SignalTypeName" SG_ 1230 status "PipoStatus";
BA_ "SignalType" SG_ 1230 status "enum";
BA_ "StandardName" SG_ 1640 patch "Kraken_PipoVersion_patch_U";
BA_ "StandardName" SG_ 1640 minor "Kraken_PipoVersion_minor_U";
BA_ "StandardName" SG_ 1640 major "Kraken_PipoVersion_major_U";
BA_ "StandardName" SG_ 1641 dirty "Kraken_PipoVersion_dirty_bool";
BA_ "SignalTypeName" SG_ 1641 dirty "bool";
BA_ "SignalType" SG_ 1641 dirty "bool";
BA_ "StandardName" SG_ 1641 commitHash "Kraken_PipoVersion_commitHash_U";
BA_ "StandardName" SG_ 1641 buildTime "Kraken_PipoVersion_buildTime_s";
BA_ "StandardName" SG_ 1642 patch "Kraken_PipoVersionLibcan_patch_U";
BA_ "StandardName" SG_ 1642 minor "Kraken_PipoVersionLibcan_minor_U";
BA_ "StandardName" SG_ 1642 major "Kraken_PipoVersionLibcan_major_U";
BA_ "StandardName" SG_ 1643 dirty "Kraken_PipoVersionLibcan_dirty_bool";
BA_ "SignalTypeName" SG_ 1643 dirty "bool";
BA_ "SignalType" SG_ 1643 dirty "bool";
BA_ "StandardName" SG_ 1643 commitHash "Kraken_PipoVersionLibcan_commitHash_U";
BA_ "StandardName" SG_ 1643 generationTime "Kraken_PipoVersionLibcan_generationTime_s";
BA_ "StandardName" SG_ 1231 voltageOut "Kraken_PipoVoltage_lowPower_V";
BA_ "StandardName" SG_ 1231 power "LowVoltage_PowerSupply_power_W";
BA_ "StandardName" SG_ 1231 current "LowVoltage_PowerSupply_current_A";
BA_ "StandardName" SG_ 1231 voltage "LowVoltage_PowerSupply_voltage_V";
BA_ "StandardName" SG_ 1232 spare2 "Kraken_PipoCurrentLowPower_spare2_A";
BA_ "StandardName" SG_ 1232 spare1 "Kraken_PipoCurrentLowPower_spare1_A";
BA_ "StandardName" SG_ 1232 shutdown "Kraken_PipoCurrentLowPower_shutdown_A";
BA_ "StandardName" SG_ 1232 driver "Kraken_PipoCurrentLowPower_driver_A";
BA_ "StandardName" SG_ 1232 lights "Kraken_PipoCurrentLowPower_lights_A";
BA_ "StandardName" SG_ 1232 powertrain "Kraken_PipoCurrentLowPower_powertrain_A";
BA_ "StandardName" SG_ 1232 tlm "Kraken_PipoCurrentLowPower_tlm_A";
BA_ "StandardName" SG_ 1233 spare "Kraken_PipoCurrentHighPower_spare_A";
BA_ "StandardName" SG_ 1233 coolingLeft "Kraken_PipoCurrentHighPower_coolingLeft_A";
BA_ "StandardName" SG_ 1233 coolingRight "Kraken_PipoCurrentHighPower_coolingRight_A";
BA_ "StandardName" SG_ 1234 ebs "Kraken_PipoCurrentHighPower_ebs_A";
BA_ "StandardName" SG_ 1234 steering "Kraken_PipoCurrentHighPower_steer_A";
BA_ "StandardName" SG_ 1234 pcAs "Kraken_PipoCurrentHighPower_pcAs_A";
BA_ "StandardName" SG_ 1234 vision "Kraken_PipoCurrentHighPower_vision_A";
BA_ "StandardName" SG_ 409 tsms "ShutDown_Tsms_voltage_V";
BA_ "StandardName" SG_ 409 res "ShutDown_Res_voltage_V";
BA_ "StandardName" SG_ 409 asms "ShutDown_Asms_voltage_V";
BA_ "StandardName" SG_ 409 bspd "ShutDown_Bspd_voltage_V";
BA_ "StandardName" SG_ 409 hvd "ShutDown_Hvd_voltage_V";
BA_ "StandardName" SG_ 409 lvms "ShutDown_Lvms_voltage_V";
BA_ "StandardName" SG_ 1235 status "Kraken_LvacFsm_status_enum";
BA_ "SignalTypeName" SG_ 1235 status "LvacStatus";
BA_ "SignalType" SG_ 1235 status "enum";
BA_ "StandardName" SG_ 1644 patch "Kraken_LvacVersion_patch_U";
BA_ "StandardName" SG_ 1644 minor "Kraken_LvacVersion_minor_U";
BA_ "StandardName" SG_ 1644 major "Kraken_LvacVersion_major_U";
BA_ "StandardName" SG_ 1645 dirty "Kraken_LvacVersion_dirty_bool";
BA_ "SignalTypeName" SG_ 1645 dirty "bool";
BA_ "SignalType" SG_ 1645 dirty "bool";
BA_ "StandardName" SG_ 1645 commitHash "Kraken_LvacVersion_commitHash_U";
BA_ "StandardName" SG_ 1645 buildTime "Kraken_LvacVersion_buildTime_s";
BA_ "StandardName" SG_ 1646 patch "Kraken_LvacVersionLibcan_patch_U";
BA_ "StandardName" SG_ 1646 minor "Kraken_LvacVersionLibcan_minor_U";
BA_ "StandardName" SG_ 1646 major "Kraken_LvacVersionLibcan_major_U";
BA_ "StandardName" SG_ 1647 dirty "Kraken_LvacVersionLibcan_dirty_bool";
BA_ "SignalTypeName" SG_ 1647 dirty "bool";
BA_ "SignalType" SG_ 1647 dirty "bool";
BA_ "StandardName" SG_ 1647 commitHash "Kraken_LvacVersionLibcan_commitHash_U";
BA_ "StandardName" SG_ 1647 generationTime "Kraken_LvacVersionLibcan_generationTime_s";
BA_ "StandardName" SG_ 0 vrc2 "LowVoltage_AccumulatorEstimated_vrc2_V";
BA_ "StandardName" SG_ 0 vrc1 "LowVoltage_AccumulatorEstimated_vrc1_V";
BA_ "StandardName" SG_ 0 soc "LowVoltage_AccumulatorEstimated_soc_U";
BA_ "StandardName" SG_ 1648 vrc2 "LowVoltage_AccumulatorEstimatedCovariance_vrc2_V";
BA_ "StandardName" SG_ 1648 vrc1 "LowVoltage_AccumulatorEstimatedCovariance_vrc1_V";
BA_ "StandardName" SG_ 1648 soc "LowVoltage_AccumulatorEstimatedCovariance_soc_U";
BA_ "StandardName" SG_ 1236 current "Kraken_LowVoltageAccumulatorCurrent_current_A";
BA_ "StandardName" SG_ 1236 average "Kraken_LowVoltageAccumulatorVoltage_average_V";
BA_ "StandardName" SG_ 1236 max "Kraken_LowVoltageAccumulatorVoltage_max_V";
BA_ "StandardName" SG_ 1236 min "Kraken_LowVoltageAccumulatorVoltage_min_V";
BA_ "StandardName" SG_ 1236 total "LowVoltage_AccumulatorVoltage_total_V";
BA_ "StandardName" SG_ 1237 voltage6 "Kraken_LowVoltageAccumulatorCellVoltage_voltage6_V";
BA_ "StandardName" SG_ 1237 voltage5 "Kraken_LowVoltageAccumulatorCellVoltage_voltage5_V";
BA_ "StandardName" SG_ 1237 voltage4 "Kraken_LowVoltageAccumulatorCellVoltage_voltage4_V";
BA_ "StandardName" SG_ 1237 voltage3 "Kraken_LowVoltageAccumulatorCellVoltage_voltage3_V";
BA_ "StandardName" SG_ 1237 voltage2 "Kraken_LowVoltageAccumulatorCellVoltage_voltage2_V";
BA_ "StandardName" SG_ 1237 voltage1 "Kraken_LowVoltageAccumulatorCellVoltage_voltage1_V";
BA_ "StandardName" SG_ 1238 average "LowVoltage_AccumulatorTemperature_average_degC";
BA_ "StandardName" SG_ 1238 max "LowVoltage_AccumulatorTemperature_max_degC";
BA_ "StandardName" SG_ 1238 min "LowVoltage_AccumulatorTemperature_min_degC";
BA_ "StandardName" SG_ 1239 temperature12 "Kraken_LowVoltageAccumulatorTemperature_temperature12_degC";
BA_ "StandardName" SG_ 1239 temperature6 "Kraken_LowVoltageAccumulatorTemperature_temperature6_degC";
BA_ "StandardName" SG_ 1239 temperature11 "Kraken_LowVoltageAccumulatorTemperature_temperature11_degC";
BA_ "StandardName" SG_ 1239 temperature5 "Kraken_LowVoltageAccumulatorTemperature_temperature5_degC";
BA_ "StandardName" SG_ 1239 temperature10 "Kraken_LowVoltageAccumulatorTemperature_temperature10_degC";
BA_ "StandardName" SG_ 1239 temperature4 "Kraken_LowVoltageAccumulatorTemperature_temperature4_degC";
BA_ "StandardName" SG_ 1239 temperature9 "Kraken_LowVoltageAccumulatorTemperature_temperature9_degC";
BA_ "StandardName" SG_ 1239 temperature3 "Kraken_LowVoltageAccumulatorTemperature_temperature3_degC";
BA_ "StandardName" SG_ 1239 temperature8 "Kraken_LowVoltageAccumulatorTemperature_temperature8_degC";
BA_ "StandardName" SG_ 1239 temperature2 "Kraken_LowVoltageAccumulatorTemperature_temperature2_degC";
BA_ "StandardName" SG_ 1239 temperature7 "Kraken_LowVoltageAccumulatorTemperature_temperature7_degC";
BA_ "StandardName" SG_ 1239 temperature1 "Kraken_LowVoltageAccumulatorTemperature_temperature1_degC";
BA_ "StandardName" SG_ 1240 status "Kraken_SteeringWheelFsm_status_enum";
BA_ "SignalTypeName" SG_ 1240 status "SteeringWheelStatus";
BA_ "SignalType" SG_ 1240 status "enum";
BA_ "StandardName" SG_ 1649 patch "Kraken_SteeringWheelVersion_patch_U";
BA_ "StandardName" SG_ 1649 minor "Kraken_SteeringWheelVersion_minor_U";
BA_ "StandardName" SG_ 1649 major "Kraken_SteeringWheelVersion_major_U";
BA_ "StandardName" SG_ 1650 dirty "Kraken_SteeringWheelVersion_dirty_bool";
BA_ "SignalTypeName" SG_ 1650 dirty "bool";
BA_ "SignalType" SG_ 1650 dirty "bool";
BA_ "StandardName" SG_ 1650 commitHash "Kraken_SteeringWheelVersion_commitHash_U";
BA_ "StandardName" SG_ 1650 buildTime "Kraken_SteeringWheelVersion_buildTime_s";
BA_ "StandardName" SG_ 1651 patch "Kraken_SteeringWheelVersionLibcan_patch_U";
BA_ "StandardName" SG_ 1651 minor "Kraken_SteeringWheelVersionLibcan_minor_U";
BA_ "StandardName" SG_ 1651 major "Kraken_SteeringWheelVersionLibcan_major_U";
BA_ "StandardName" SG_ 1652 dirty "Kraken_SteeringWheelVersionLibcan_dirty_bool";
BA_ "SignalTypeName" SG_ 1652 dirty "bool";
BA_ "SignalType" SG_ 1652 dirty "bool";
BA_ "StandardName" SG_ 1652 commitHash "Kraken_SteeringWheelVersionLibcan_commitHash_U";
BA_ "StandardName" SG_ 1652 generationTime "Kraken_SteeringWheelVersionLibcan_generationTime_s";
BA_ "StandardName" SG_ 818 launchControl "VehicleState_ControlMapsSet_launchControl_bool";
BA_ "SignalTypeName" SG_ 818 launchControl "bool";
BA_ "SignalType" SG_ 818 launchControl "bool";
BA_ "StandardName" SG_ 818 regen "VehicleState_ControlMapsSet_regen_U";
BA_ "StandardName" SG_ 818 torqueVectoring "VehicleState_ControlMapsSet_torqueVectoring_U";
BA_ "StandardName" SG_ 818 power "VehicleState_ControlMapsSet_power_U";
BA_ "StandardName" SG_ 819 repeat "Driver_Feedback_repeat_bool";
BA_ "SignalTypeName" SG_ 819 repeat "bool";
BA_ "SignalType" SG_ 819 repeat "bool";
BA_ "StandardName" SG_ 819 ok "Driver_Feedback_ok_bool";
BA_ "SignalTypeName" SG_ 819 ok "bool";
BA_ "SignalType" SG_ 819 ok "bool";
BA_ "StandardName" SG_ 819 marker "Telemetry_SessionSet_marker_bool";
BA_ "SignalTypeName" SG_ 819 marker "bool";
BA_ "SignalType" SG_ 819 marker "bool";
BA_ "StandardName" SG_ 819 log "Telemetry_SessionSet_log_bool";
BA_ "SignalTypeName" SG_ 819 log "bool";
BA_ "SignalType" SG_ 819 log "bool";
BA_ "StandardName" SG_ 1 ptt "Driver_Ptt_request_bool";
BA_ "SignalTypeName" SG_ 1 ptt "bool";
BA_ "SignalType" SG_ 1 ptt "bool";
BA_ "StandardName" SG_ 1 tson "Kraken_SteeringWheelTsonButton_status_bool";
BA_ "SignalTypeName" SG_ 1 tson "bool";
BA_ "SignalType" SG_ 1 tson "bool";
BA_ "SignalTypeName" SG_ 820 modeAuto "bool";
BA_ "SignalType" SG_ 820 modeAuto "bool";
BA_ "StandardName" SG_ 1241 status "Kraken_CoolingFsm_status_enum";
BA_ "SignalTypeName" SG_ 1241 status "CoolingStatus";
BA_ "SignalType" SG_ 1241 status "enum";
BA_ "StandardName" SG_ 1653 patch "Kraken_CoolingVersion_patch_U";
BA_ "StandardName" SG_ 1653 minor "Kraken_CoolingVersion_minor_U";
BA_ "StandardName" SG_ 1653 major "Kraken_CoolingVersion_major_U";
BA_ "StandardName" SG_ 1654 dirty "Kraken_CoolingVersion_dirty_bool";
BA_ "SignalTypeName" SG_ 1654 dirty "bool";
BA_ "SignalType" SG_ 1654 dirty "bool";
BA_ "StandardName" SG_ 1654 commitHash "Kraken_CoolingVersion_commitHash_U";
BA_ "StandardName" SG_ 1654 buildTime "Kraken_CoolingVersion_buildTime_s";
BA_ "StandardName" SG_ 1655 patch "Kraken_CoolingVersionLibcan_patch_U";
BA_ "StandardName" SG_ 1655 minor "Kraken_CoolingVersionLibcan_minor_U";
BA_ "StandardName" SG_ 1655 major "Kraken_CoolingVersionLibcan_major_U";
BA_ "StandardName" SG_ 1656 dirty "Kraken_CoolingVersionLibcan_dirty_bool";
BA_ "SignalTypeName" SG_ 1656 dirty "bool";
BA_ "SignalType" SG_ 1656 dirty "bool";
BA_ "StandardName" SG_ 1656 commitHash "Kraken_CoolingVersionLibcan_commitHash_U";
BA_ "StandardName" SG_ 1656 generationTime "Kraken_CoolingVersionLibcan_generationTime_s";
BA_ "StandardName" SG_ 1242 rearRight "Cooling_MotorRR_temperatureOut_degC";
BA_ "StandardName" SG_ 1242 rearLeft "Cooling_MotorRL_temperatureOut_degC";
BA_ "StandardName" SG_ 1242 frontRight "Cooling_MotorFR_temperatureOut_degC";
BA_ "StandardName" SG_ 1242 frontLeft "Cooling_MotorFL_temperatureOut_degC";
BA_ "StandardName" SG_ 1243 pumpRight "Cooling_PumpR_temperatureOut_degC";
BA_ "StandardName" SG_ 1243 pumpLeft "Cooling_PumpL_temperatureOut_degC";
BA_ "StandardName" SG_ 1243 radiatorRight "Cooling_RadiatorR_temperatureOut_degC";
BA_ "StandardName" SG_ 1243 radiatorLeft "Cooling_RadiatorL_temperatureOut_degC";
BA_ "StandardName" SG_ 1244 invertersOut "Cooling_Inverters_temperatureOut_degC";
BA_ "StandardName" SG_ 1244 tsacOut "Cooling_Tsac_temperatureOut_degC";
BA_ "StandardName" SG_ 1244 tsacIn "Cooling_Tsac_temperatureIn_degC";
BA_ "StandardName" SG_ 1245 fanRight "Cooling_FanR_coolingOut_U";
BA_ "StandardName" SG_ 1245 fanLeft "Cooling_FanL_coolingOut_U";
BA_ "StandardName" SG_ 1245 pumpRight "Cooling_PumpR_coolingOut_U";
BA_ "StandardName" SG_ 1245 pumpLeft "Cooling_PumpL_coolingOut_U";
BA_ "StandardName" SG_ 1246 status "Kraken_SteeringFsm_status_enum";
BA_ "SignalTypeName" SG_ 1246 status "SteeringStatus";
BA_ "SignalType" SG_ 1246 status "enum";
BA_ "StandardName" SG_ 1657 patch "Kraken_SteeringVersion_patch_U";
BA_ "StandardName" SG_ 1657 minor "Kraken_SteeringVersion_minor_U";
BA_ "StandardName" SG_ 1657 major "Kraken_SteeringVersion_major_U";
BA_ "StandardName" SG_ 1658 dirty "Kraken_SteeringVersion_dirty_bool";
BA_ "SignalTypeName" SG_ 1658 dirty "bool";
BA_ "SignalType" SG_ 1658 dirty "bool";
BA_ "StandardName" SG_ 1658 commitHash "Kraken_SteeringVersion_commitHash_U";
BA_ "StandardName" SG_ 1658 buildTime "Kraken_SteeringVersion_buildTime_s";
BA_ "StandardName" SG_ 1659 patch "Kraken_SteeringVersionLibcan_patch_U";
BA_ "StandardName" SG_ 1659 minor "Kraken_SteeringVersionLibcan_minor_U";
BA_ "StandardName" SG_ 1659 major "Kraken_SteeringVersionLibcan_major_U";
BA_ "StandardName" SG_ 1660 dirty "Kraken_SteeringVersionLibcan_dirty_bool";
BA_ "SignalTypeName" SG_ 1660 dirty "bool";
BA_ "SignalType" SG_ 1660 dirty "bool";
BA_ "StandardName" SG_ 1660 commitHash "Kraken_SteeringVersionLibcan_commitHash_U";
BA_ "StandardName" SG_ 1660 generationTime "Kraken_SteeringVersionLibcan_generationTime_s";
BA_ "StandardName" SG_ 1247 angle "Steering_steerAngle_rad";
BA_ "StandardName" SG_ 1248 status "Kraken_DasFrontFsm_status_enum";
BA_ "SignalTypeName" SG_ 1248 status "DasFrontStatus";
BA_ "SignalType" SG_ 1248 status "enum";
BA_ "StandardName" SG_ 1661 patch "Kraken_DasFrontVersion_patch_U";
BA_ "StandardName" SG_ 1661 minor "Kraken_DasFrontVersion_minor_U";
BA_ "StandardName" SG_ 1661 major "Kraken_DasFrontVersion_major_U";
BA_ "StandardName" SG_ 1662 dirty "Kraken_DasFrontVersion_dirty_bool";
BA_ "SignalTypeName" SG_ 1662 dirty "bool";
BA_ "SignalType" SG_ 1662 dirty "bool";
BA_ "StandardName" SG_ 1662 commitHash "Kraken_DasFrontVersion_commitHash_U";
BA_ "StandardName" SG_ 1662 buildTime "Kraken_DasFrontVersion_buildTime_s";
BA_ "StandardName" SG_ 1663 patch "Kraken_DasFrontVersionLibcan_patch_U";
BA_ "StandardName" SG_ 1663 minor "Kraken_DasFrontVersionLibcan_minor_U";
BA_ "StandardName" SG_ 1663 major "Kraken_DasFrontVersionLibcan_major_U";
BA_ "StandardName" SG_ 1664 dirty "Kraken_DasFrontVersionLibcan_dirty_bool";
BA_ "SignalTypeName" SG_ 1664 dirty "bool";
BA_ "SignalType" SG_ 1664 dirty "bool";
BA_ "StandardName" SG_ 1664 commitHash "Kraken_DasFrontVersionLibcan_commitHash_U";
BA_ "StandardName" SG_ 1664 generationTime "Kraken_DasFrontVersionLibcan_generationTime_s";
BA_ "StandardName" SG_ 1249 frontLeft "Powertrain_TyreFL_temperature_degC";
BA_ "StandardName" SG_ 1249 frontRight "Powertrain_TyreFR_temperature_degC";
BA_ "StandardName" SG_ 1250 roll "Suspensions_RollF_travel_mm";
BA_ "StandardName" SG_ 1250 heave "Suspensions_HeaveF_travel_mm";
BA_ "StandardName" SG_ 410 inertia "ShutDown_Inertia_voltage_V";
BA_ "StandardName" SG_ 410 mushroomCockpit "ShutDown_MushroomCockpit_voltage_V";
BA_ "StandardName" SG_ 410 mushroomLeft "ShutDown_MushroomLeft_voltage_V";
BA_ "StandardName" SG_ 410 mushroomRight "ShutDown_MushroomRight_voltage_V";
BA_ "StandardName" SG_ 2 krakenStatus "Kraken_EcuFsm_status_enum";
BA_ "SignalTypeName" SG_ 2 krakenStatus "KrakenStatus";
BA_ "SignalType" SG_ 2 krakenStatus "enum";
BA_ "StandardName" SG_ 2 vehicleStatus "VehicleState_Fsm_status_enum";
BA_ "SignalTypeName" SG_ 2 vehicleStatus "VehicleStatus";
BA_ "SignalType" SG_ 2 vehicleStatus "enum";
BA_ "StandardName" SG_ 1665 patch "Kraken_EcuVersion_patch_U";
BA_ "StandardName" SG_ 1665 minor "Kraken_EcuVersion_minor_U";
BA_ "StandardName" SG_ 1665 major "Kraken_EcuVersion_major_U";
BA_ "StandardName" SG_ 1666 dirty "Kraken_EcuVersion_dirty_bool";
BA_ "SignalTypeName" SG_ 1666 dirty "bool";
BA_ "SignalType" SG_ 1666 dirty "bool";
BA_ "StandardName" SG_ 1666 commitHash "Kraken_EcuVersion_commitHash_U";
BA_ "StandardName" SG_ 1666 buildTime "Kraken_EcuVersion_buildTime_s";
BA_ "StandardName" SG_ 1667 patch "VehicleState_VersionLibcan_patch_U";
BA_ "StandardName" SG_ 1667 minor "VehicleState_VersionLibcan_minor_U";
BA_ "StandardName" SG_ 1667 major "VehicleState_VersionLibcan_major_U";
BA_ "StandardName" SG_ 1668 dirty "VehicleState_VersionLibcan_dirty_bool";
BA_ "SignalTypeName" SG_ 1668 dirty "bool";
BA_ "SignalType" SG_ 1668 dirty "bool";
BA_ "StandardName" SG_ 1668 commitHash "VehicleState_VersionLibcan_commitHash_U";
BA_ "StandardName" SG_ 1668 generationTime "VehicleState_VersionLibcan_generationTime_s";
BA_ "StandardName" SG_ 3 status "Powertrain_BmsSet_status_bool";
BA_ "SignalTypeName" SG_ 3 status "bool";
BA_ "SignalType" SG_ 3 status "bool";
BA_ "StandardName" SG_ 411 voltageOut "ShutDown_Ecu_voltage_V";
BA_ "StandardName" SG_ 411 voltageIn "Kraken_EcuShutdownRelayIn_voltage_V";
BA_ "StandardName" SG_ 1251 status "VehicleState_Ptt_status_bool";
BA_ "SignalTypeName" SG_ 1251 status "bool";
BA_ "SignalType" SG_ 1251 status "bool";
BA_ "StandardName" SG_ 1252 temperatureRR "Powertrain_InverterRR_temperature_degC";
BA_ "StandardName" SG_ 1252 temperatureRL "Powertrain_InverterRL_temperature_degC";
BA_ "StandardName" SG_ 1252 temperatureFR "Powertrain_InverterFR_temperature_degC";
BA_ "StandardName" SG_ 1252 temperatureFL "Powertrain_InverterFL_temperature_degC";
BA_ "StandardName" SG_ 1253 temperatureRR "Powertrain_MotorRR_temperature_degC";
BA_ "StandardName" SG_ 1253 temperatureRL "Powertrain_MotorRL_temperature_degC";
BA_ "StandardName" SG_ 1253 temperatureFR "Powertrain_MotorFR_temperature_degC";
BA_ "StandardName" SG_ 1253 temperatureFL "Powertrain_MotorFL_temperature_degC";
BA_ "StandardName" SG_ 1254 torqueRR "Powertrain_WheelRR_torque_Nm";
BA_ "StandardName" SG_ 1254 torqueRL "Powertrain_WheelRL_torque_Nm";
BA_ "StandardName" SG_ 1254 torqueFR "Powertrain_WheelFR_torque_Nm";
BA_ "StandardName" SG_ 1254 torqueFL "Powertrain_WheelFL_torque_Nm";
BA_ "SignalTypeName" SG_ 821 modeAuto "bool";
BA_ "SignalType" SG_ 821 modeAuto "bool";
BA_ "StandardName" SG_ 1255 status "Telemetry_Fsm_status_enum";
BA_ "SignalTypeName" SG_ 1255 status "TelemetryStatus";
BA_ "SignalType" SG_ 1255 status "enum";
BA_ "StandardName" SG_ 1669 patch "Telemetry_Version_patch_U";
BA_ "StandardName" SG_ 1669 minor "Telemetry_Version_minor_U";
BA_ "StandardName" SG_ 1669 major "Telemetry_Version_major_U";
BA_ "StandardName" SG_ 1670 dirty "Telemetry_Version_dirty_bool";
BA_ "SignalTypeName" SG_ 1670 dirty "bool";
BA_ "SignalType" SG_ 1670 dirty "bool";
BA_ "StandardName" SG_ 1670 commitHash "Telemetry_Version_commitHash_U";
BA_ "StandardName" SG_ 1670 buildTime "Telemetry_Version_buildTime_s";
BA_ "StandardName" SG_ 1671 patch "Telemetry_VersionLibcan_patch_U";
BA_ "StandardName" SG_ 1671 minor "Telemetry_VersionLibcan_minor_U";
BA_ "StandardName" SG_ 1671 major "Telemetry_VersionLibcan_major_U";
BA_ "StandardName" SG_ 1672 dirty "Telemetry_VersionLibcan_dirty_bool";
BA_ "SignalTypeName" SG_ 1672 dirty "bool";
BA_ "SignalType" SG_ 1672 dirty "bool";
BA_ "StandardName" SG_ 1672 commitHash "Telemetry_VersionLibcan_commitHash_U";
BA_ "StandardName" SG_ 1672 generationTime "Telemetry_VersionLibcan_generationTime_s";
BA_ "StandardName" SG_ 1256 psi "VehicleState_Estimated_psi_rad";
BA_ "StandardName" SG_ 1256 y "VehicleState_Estimated_y_m";
BA_ "StandardName" SG_ 1256 x "VehicleState_Estimated_x_m";
BA_ "StandardName" SG_ 1257 v "VehicleState_Estimated_v_mps";
BA_ "StandardName" SG_ 1257 u "VehicleState_Estimated_u_mps";
BA_ "StandardName" SG_ 1258 deltaBestLap "TrackSession_CurrentLap_deltaBestLap_s";
BA_ "StandardName" SG_ 1258 number "TrackSession_CurrentLap_number_U";
BA_ "StandardName" SG_ 1259 time "TrackSession_BestLap_time_s";
BA_ "StandardName" SG_ 1259 number "TrackSession_BestLap_number_U";
BA_ "StandardName" SG_ 1262 time "TrackSession_LastLap_time_s";
BA_ "StandardName" SG_ 1263 totalTime "TrackSession_Laps_totalTime_s";
BA_ "StandardName" SG_ 1263 totalNumber "TrackSession_Laps_totalNumber_U";
BA_ "StandardName" SG_ 1264 n "TrackSession_CurvilinearCoordinates_n_m";
BA_ "StandardName" SG_ 1264 s "TrackSession_CurvilinearCoordinates_s_m";
BA_ "StandardName" SG_ 822 threshold "Kraken_RaspberryTsacBalancingSet_threshold_V";
BA_ "StandardName" SG_ 822 start "Kraken_RaspberryTsacBalancingSet_mainboardStart_bool";
BA_ "SignalTypeName" SG_ 822 start "bool";
BA_ "SignalType" SG_ 822 start "bool";
BA_ "StandardName" SG_ 823 threshold "Kraken_RaspberryLvacBalancingSet_threshold_V";
BA_ "StandardName" SG_ 823 start "Kraken_RaspberryLvacBalancingSet_start_bool";
BA_ "SignalTypeName" SG_ 823 start "bool";
BA_ "SignalType" SG_ 823 start "bool";
BA_ "StandardName" SG_ 1673 patch "Kraken_ControlsVersion_patch_U";
BA_ "StandardName" SG_ 1673 minor "Kraken_ControlsVersion_minor_U";
BA_ "StandardName" SG_ 1673 major "Kraken_ControlsVersion_major_U";
BA_ "StandardName" SG_ 1674 dirty "Kraken_ControlsVersion_dirty_bool";
BA_ "SignalTypeName" SG_ 1674 dirty "bool";
BA_ "SignalType" SG_ 1674 dirty "bool";
BA_ "StandardName" SG_ 1674 commitHash "Kraken_ControlsVersion_commitHash_U";
BA_ "StandardName" SG_ 1674 buildTime "Kraken_ControlsVersion_buildTime_s";
BA_ "StandardName" SG_ 1675 patch "Kraken_ControlsVersionLibcan_patch_U";
BA_ "StandardName" SG_ 1675 minor "Kraken_ControlsVersionLibcan_minor_U";
BA_ "StandardName" SG_ 1675 major "Kraken_ControlsVersionLibcan_major_U";
BA_ "StandardName" SG_ 1676 dirty "Kraken_ControlsVersionLibcan_dirty_bool";
BA_ "SignalTypeName" SG_ 1676 dirty "bool";
BA_ "SignalType" SG_ 1676 dirty "bool";
BA_ "StandardName" SG_ 1676 commitHash "Kraken_ControlsVersionLibcan_commitHash_U";
BA_ "StandardName" SG_ 1676 generationTime "Kraken_ControlsVersionLibcan_generationTime_s";
BA_ "SignalTypeName" SG_ 824 modeAuto "bool";
BA_ "SignalType" SG_ 824 modeAuto "bool";
BA_ "StandardName" SG_ 1265 status "Kraken_PedalsFsm_status_enum";
BA_ "SignalTypeName" SG_ 1265 status "PedalsStatus";
BA_ "SignalType" SG_ 1265 status "enum";
BA_ "StandardName" SG_ 1677 patch "Kraken_PedalsVersion_patch_U";
BA_ "StandardName" SG_ 1677 minor "Kraken_PedalsVersion_minor_U";
BA_ "StandardName" SG_ 1677 major "Kraken_PedalsVersion_major_U";
BA_ "StandardName" SG_ 1678 dirty "Kraken_PedalsVersion_dirty_bool";
BA_ "SignalTypeName" SG_ 1678 dirty "bool";
BA_ "SignalType" SG_ 1678 dirty "bool";
BA_ "StandardName" SG_ 1678 commitHash "Kraken_PedalsVersion_commitHash_U";
BA_ "StandardName" SG_ 1678 buildTime "Kraken_PedalsVersion_buildTime_s";
BA_ "StandardName" SG_ 1679 patch "Kraken_PedalsVersionLibcan_patch_U";
BA_ "StandardName" SG_ 1679 minor "Kraken_PedalsVersionLibcan_minor_U";
BA_ "StandardName" SG_ 1679 major "Kraken_PedalsVersionLibcan_major_U";
BA_ "StandardName" SG_ 1680 dirty "Kraken_PedalsVersionLibcan_dirty_bool";
BA_ "SignalTypeName" SG_ 1680 dirty "bool";
BA_ "SignalType" SG_ 1680 dirty "bool";
BA_ "StandardName" SG_ 1680 commitHash "Kraken_PedalsVersionLibcan_commitHash_U";
BA_ "StandardName" SG_ 1680 generationTime "Kraken_PedalsVersionLibcan_generationTime_s";
BA_ "StandardName" SG_ 4 plausibility "Powertrain_PedalThrottle_plausibility_enum";
BA_ "SignalTypeName" SG_ 4 plausibility "ThrottlePlausibility";
BA_ "SignalType" SG_ 4 plausibility "enum";
BA_ "StandardName" SG_ 4 travel "Powertrain_PedalThrottle_travel_U";
BA_ "StandardName" SG_ 4 apps3 "Kraken_Pedals_apps3_U";
BA_ "StandardName" SG_ 4 apps2 "Kraken_Pedals_apps2_U";
BA_ "StandardName" SG_ 4 apps1 "Kraken_Pedals_apps1_U";
BA_ "StandardName" SG_ 1266 botsVoltage "ShutDown_Bots_voltage_V";
BA_ "StandardName" SG_ 1266 travel "Brakes_PedalBrake_travel_U";
BA_ "StandardName" SG_ 1266 pressureRR "Brakes_WheelRR_pressure_bar";
BA_ "StandardName" SG_ 1266 pressureRL "Brakes_WheelRL_pressure_bar";
BA_ "StandardName" SG_ 1266 pressureFR "Brakes_WheelFR_pressure_bar";
BA_ "StandardName" SG_ 1266 pressureFL "Brakes_WheelFL_pressure_bar";
BA_ "StandardName" SG_ 5 shutdownVoltage "ShutDown_Ebs_voltage_V";
BA_ "StandardName" SG_ 5 loadLine2 "Brakes_Ebs_loadLine2_N";
BA_ "StandardName" SG_ 5 loadLine1 "Brakes_Ebs_loadLine1_N";
BA_ "StandardName" SG_ 5 pressureLine2 "Brakes_Ebs_pressureLine2_bar";
BA_ "StandardName" SG_ 5 pressureLine1 "Brakes_Ebs_pressureLine1_bar";
BA_ "StandardName" SG_ 5 pressureTank2 "Brakes_Ebs_pressureTank2_bar";
BA_ "StandardName" SG_ 5 pressureTank1 "Brakes_Ebs_pressureTank1_bar";
BA_ "StandardName" SG_ 412 cellboard6Status "Kraken_TsacCellboardFsm_status_enum";
BA_ "SignalTypeName" SG_ 412 cellboard6Status "TsacCellboardStatus";
BA_ "SignalType" SG_ 412 cellboard6Status "enum";
BA_ "StandardName" SG_ 412 cellboard5Status "Kraken_TsacCellboardFsm_status_enum";
BA_ "SignalTypeName" SG_ 412 cellboard5Status "TsacCellboardStatus";
BA_ "SignalType" SG_ 412 cellboard5Status "enum";
BA_ "StandardName" SG_ 412 cellboard4Status "Kraken_TsacCellboardFsm_status_enum";
BA_ "SignalTypeName" SG_ 412 cellboard4Status "TsacCellboardStatus";
BA_ "SignalType" SG_ 412 cellboard4Status "enum";
BA_ "StandardName" SG_ 412 cellboard3Status "Kraken_TsacCellboardFsm_status_enum";
BA_ "SignalTypeName" SG_ 412 cellboard3Status "TsacCellboardStatus";
BA_ "SignalType" SG_ 412 cellboard3Status "enum";
BA_ "StandardName" SG_ 412 cellboard2Status "Kraken_TsacCellboardFsm_status_enum";
BA_ "SignalTypeName" SG_ 412 cellboard2Status "TsacCellboardStatus";
BA_ "SignalType" SG_ 412 cellboard2Status "enum";
BA_ "StandardName" SG_ 412 cellboard1Status "Kraken_TsacCellboardFsm_status_enum";
BA_ "SignalTypeName" SG_ 412 cellboard1Status "TsacCellboardStatus";
BA_ "SignalType" SG_ 412 cellboard1Status "enum";
BA_ "StandardName" SG_ 412 mainboardStatus "Kraken_TsacMainboardFsm_status_enum";
BA_ "SignalTypeName" SG_ 412 mainboardStatus "TsacMainboardStatus";
BA_ "SignalType" SG_ 412 mainboardStatus "enum";
BA_ "StandardName" SG_ 1681 patch "Kraken_TsacMainboardVersion_patch_U";
BA_ "StandardName" SG_ 1681 minor "Kraken_TsacMainboardVersion_minor_U";
BA_ "StandardName" SG_ 1681 major "Kraken_TsacMainboardVersion_major_U";
BA_ "StandardName" SG_ 1682 dirty "Kraken_TsacMainboardVersionLibcan_dirty_bool";
BA_ "SignalTypeName" SG_ 1682 dirty "bool";
BA_ "SignalType" SG_ 1682 dirty "bool";
BA_ "StandardName" SG_ 1682 commitHash "Kraken_TsacMainboardVersion_commitHash_U";
BA_ "StandardName" SG_ 1682 buildTime "Kraken_TsacMainboardVersion_buildTime_s";
BA_ "StandardName" SG_ 1683 patch "Kraken_TsacMainboardVersionLibcan_patch_U";
BA_ "StandardName" SG_ 1683 minor "Kraken_TsacMainboardVersionLibcan_minor_U";
BA_ "StandardName" SG_ 1683 major "Kraken_TsacMainboardVersionLibcan_major_U";
BA_ "StandardName" SG_ 1684 dirty "Kraken_TsacMainboardVersionLibcan_dirty_bool";
BA_ "SignalTypeName" SG_ 1684 dirty "bool";
BA_ "SignalType" SG_ 1684 dirty "bool";
BA_ "StandardName" SG_ 1684 commitHash "Kraken_TsacMainboardVersionLibcan_commitHash_U";
BA_ "StandardName" SG_ 1684 generationTime "Kraken_TsacMainboardVersionLibcan_generationTime_s";
BA_ "StandardName" SG_ 1685 patch "Kraken_TsacCellboard1Version_patch_U";
BA_ "StandardName" SG_ 1685 minor "Kraken_TsacCellboard1Version_minor_U";
BA_ "StandardName" SG_ 1685 major "Kraken_TsacCellboard1Version_major_U";
BA_ "StandardName" SG_ 1686 dirty "Kraken_TsacCellboard1VersionLibcan_dirty_bool";
BA_ "SignalTypeName" SG_ 1686 dirty "bool";
BA_ "SignalType" SG_ 1686 dirty "bool";
BA_ "StandardName" SG_ 1686 commitHash "Kraken_TsacCellboard1Version_commitHash_U";
BA_ "StandardName" SG_ 1686 buildTime "Kraken_TsacCellboard1Version_buildTime_s";
BA_ "StandardName" SG_ 1687 patch "Kraken_TsacCellboard1VersionLibcan_patch_U";
BA_ "StandardName" SG_ 1687 minor "Kraken_TsacCellboard1VersionLibcan_minor_U";
BA_ "StandardName" SG_ 1687 major "Kraken_TsacCellboard1VersionLibcan_major_U";
BA_ "StandardName" SG_ 1688 dirty "Kraken_TsacCellboard1VersionLibcan_dirty_bool";
BA_ "SignalTypeName" SG_ 1688 dirty "bool";
BA_ "SignalType" SG_ 1688 dirty "bool";
BA_ "StandardName" SG_ 1688 commitHash "Kraken_TsacCellboard1VersionLibcan_commitHash_U";
BA_ "StandardName" SG_ 1688 generationTime "Kraken_TsacCellboard1VersionLibcan_generationTime_s";
BA_ "StandardName" SG_ 1689 patch "Kraken_TsacCellboard2Version_patch_U";
BA_ "StandardName" SG_ 1689 minor "Kraken_TsacCellboard2Version_minor_U";
BA_ "StandardName" SG_ 1689 major "Kraken_TsacCellboard2Version_major_U";
BA_ "StandardName" SG_ 1690 dirty "Kraken_TsacCellboard2VersionLibcan_dirty_bool";
BA_ "SignalTypeName" SG_ 1690 dirty "bool";
BA_ "SignalType" SG_ 1690 dirty "bool";
BA_ "StandardName" SG_ 1690 commitHash "Kraken_TsacCellboard2Version_commitHash_U";
BA_ "StandardName" SG_ 1690 buildTime "Kraken_TsacCellboard2Version_buildTime_s";
BA_ "StandardName" SG_ 1691 patch "Kraken_TsacCellboard2VersionLibcan_patch_U";
BA_ "StandardName" SG_ 1691 minor "Kraken_TsacCellboard2VersionLibcan_minor_U";
BA_ "StandardName" SG_ 1691 major "Kraken_TsacCellboard2VersionLibcan_major_U";
BA_ "StandardName" SG_ 1692 dirty "Kraken_TsacCellboard2VersionLibcan_dirty_bool";
BA_ "SignalTypeName" SG_ 1692 dirty "bool";
BA_ "SignalType" SG_ 1692 dirty "bool";
BA_ "StandardName" SG_ 1692 commitHash "Kraken_TsacCellboard2VersionLibcan_commitHash_U";
BA_ "StandardName" SG_ 1692 generationTime "Kraken_TsacCellboard2VersionLibcan_generationTime_s";
BA_ "StandardName" SG_ 1693 patch "Kraken_TsacCellboard3Version_patch_U";
BA_ "StandardName" SG_ 1693 minor "Kraken_TsacCellboard3Version_minor_U";
BA_ "StandardName" SG_ 1693 major "Kraken_TsacCellboard3Version_major_U";
BA_ "StandardName" SG_ 1694 dirty "Kraken_TsacCellboard3VersionLibcan_dirty_bool";
BA_ "SignalTypeName" SG_ 1694 dirty "bool";
BA_ "SignalType" SG_ 1694 dirty "bool";
BA_ "StandardName" SG_ 1694 commitHash "Kraken_TsacCellboard3Version_commitHash_U";
BA_ "StandardName" SG_ 1694 buildTime "Kraken_TsacCellboard3Version_buildTime_s";
BA_ "StandardName" SG_ 1695 patch "Kraken_TsacCellboard3VersionLibcan_patch_U";
BA_ "StandardName" SG_ 1695 minor "Kraken_TsacCellboard3VersionLibcan_minor_U";
BA_ "StandardName" SG_ 1695 major "Kraken_TsacCellboard3VersionLibcan_major_U";
BA_ "StandardName" SG_ 1696 dirty "Kraken_TsacCellboard3VersionLibcan_dirty_bool";
BA_ "SignalTypeName" SG_ 1696 dirty "bool";
BA_ "SignalType" SG_ 1696 dirty "bool";
BA_ "StandardName" SG_ 1696 commitHash "Kraken_TsacCellboard3VersionLibcan_commitHash_U";
BA_ "StandardName" SG_ 1696 generationTime "Kraken_TsacCellboard3VersionLibcan_generationTime_s";
BA_ "StandardName" SG_ 1697 patch "Kraken_TsacCellboard4Version_patch_U";
BA_ "StandardName" SG_ 1697 minor "Kraken_TsacCellboard4Version_minor_U";
BA_ "StandardName" SG_ 1697 major "Kraken_TsacCellboard4Version_major_U";
BA_ "StandardName" SG_ 1698 dirty "Kraken_TsacCellboard4VersionLibcan_dirty_bool";
BA_ "SignalTypeName" SG_ 1698 dirty "bool";
BA_ "SignalType" SG_ 1698 dirty "bool";
BA_ "StandardName" SG_ 1698 commitHash "Kraken_TsacCellboard4Version_commitHash_U";
BA_ "StandardName" SG_ 1698 buildTime "Kraken_TsacCellboard4Version_buildTime_s";
BA_ "StandardName" SG_ 1699 patch "Kraken_TsacCellboard4VersionLibcan_patch_U";
BA_ "StandardName" SG_ 1699 minor "Kraken_TsacCellboard4VersionLibcan_minor_U";
BA_ "StandardName" SG_ 1699 major "Kraken_TsacCellboard4VersionLibcan_major_U";
BA_ "StandardName" SG_ 1700 dirty "Kraken_TsacCellboard4VersionLibcan_dirty_bool";
BA_ "SignalTypeName" SG_ 1700 dirty "bool";
BA_ "SignalType" SG_ 1700 dirty "bool";
BA_ "StandardName" SG_ 1700 commitHash "Kraken_TsacCellboard4VersionLibcan_commitHash_U";
BA_ "StandardName" SG_ 1700 generationTime "Kraken_TsacCellboard4VersionLibcan_generationTime_s";
BA_ "StandardName" SG_ 1701 patch "Kraken_TsacCellboard5Version_patch_U";
BA_ "StandardName" SG_ 1701 minor "Kraken_TsacCellboard5Version_minor_U";
BA_ "StandardName" SG_ 1701 major "Kraken_TsacCellboard5Version_major_U";
BA_ "StandardName" SG_ 1702 dirty "Kraken_TsacCellboard5VersionLibcan_dirty_bool";
BA_ "SignalTypeName" SG_ 1702 dirty "bool";
BA_ "SignalType" SG_ 1702 dirty "bool";
BA_ "StandardName" SG_ 1702 commitHash "Kraken_TsacCellboard5Version_commitHash_U";
BA_ "StandardName" SG_ 1702 buildTime "Kraken_TsacCellboard5Version_buildTime_s";
BA_ "StandardName" SG_ 1703 patch "Kraken_TsacCellboard5VersionLibcan_patch_U";
BA_ "StandardName" SG_ 1703 minor "Kraken_TsacCellboard5VersionLibcan_minor_U";
BA_ "StandardName" SG_ 1703 major "Kraken_TsacCellboard5VersionLibcan_major_U";
BA_ "StandardName" SG_ 1704 dirty "Kraken_TsacCellboard5VersionLibcan_dirty_bool";
BA_ "SignalTypeName" SG_ 1704 dirty "bool";
BA_ "SignalType" SG_ 1704 dirty "bool";
BA_ "StandardName" SG_ 1704 commitHash "Kraken_TsacCellboard5VersionLibcan_commitHash_U";
BA_ "StandardName" SG_ 1704 generationTime "Kraken_TsacCellboard5VersionLibcan_generationTime_s";
BA_ "StandardName" SG_ 1705 patch "Kraken_TsacCellboard6Version_patch_U";
BA_ "StandardName" SG_ 1705 minor "Kraken_TsacCellboard6Version_minor_U";
BA_ "StandardName" SG_ 1705 major "Kraken_TsacCellboard6Version_major_U";
BA_ "StandardName" SG_ 1706 dirty "Kraken_TsacCellboard6VersionLibcan_dirty_bool";
BA_ "SignalTypeName" SG_ 1706 dirty "bool";
BA_ "SignalType" SG_ 1706 dirty "bool";
BA_ "StandardName" SG_ 1706 commitHash "Kraken_TsacCellboard6Version_commitHash_U";
BA_ "StandardName" SG_ 1706 buildTime "Kraken_TsacCellboard6Version_buildTime_s";
BA_ "StandardName" SG_ 1707 patch "Kraken_TsacCellboard6VersionLibcan_patch_U";
BA_ "StandardName" SG_ 1707 minor "Kraken_TsacCellboard6VersionLibcan_minor_U";
BA_ "StandardName" SG_ 1707 major "Kraken_TsacCellboard6VersionLibcan_major_U";
BA_ "StandardName" SG_ 1708 dirty "Kraken_TsacCellboard6VersionLibcan_dirty_bool";
BA_ "SignalTypeName" SG_ 1708 dirty "bool";
BA_ "SignalType" SG_ 1708 dirty "bool";
BA_ "StandardName" SG_ 1708 commitHash "Kraken_TsacCellboard6VersionLibcan_commitHash_U";
BA_ "StandardName" SG_ 1708 generationTime "Kraken_TsacCellboard6VersionLibcan_generationTime_s";
BA_ "StandardName" SG_ 6 vrc2 "Powertrain_TsacEstimated_vrc2_V";
BA_ "StandardName" SG_ 6 vrc1 "Powertrain_TsacEstimated_vrc1_V";
BA_ "StandardName" SG_ 6 soc "Powertrain_TsacEstimated_soc_U";
BA_ "StandardName" SG_ 1709 vrc2 "Powertrain_TsacEstimatedCovariance_vrc2_V";
BA_ "StandardName" SG_ 1709 vrc1 "Powertrain_TsacEstimatedCovariance_vrc1_V";
BA_ "StandardName" SG_ 1709 soc "Powertrain_TsacEstimatedCovariance_soc_U";
BA_ "StandardName" SG_ 413 power "Powertrain_Tsac_power_kW";
BA_ "StandardName" SG_ 413 current "Powertrain_Tsac_current_A";
BA_ "StandardName" SG_ 414 max "Kraken_TsacMainboardVoltage_max_V";
BA_ "StandardName" SG_ 414 min "Kraken_TsacMainboardVoltage_min_V";
BA_ "StandardName" SG_ 414 average "Kraken_TsacMainboardVoltage_average_V";
BA_ "StandardName" SG_ 414 cellSum "Kraken_TsacMainboardVoltage_total_V";
BA_ "StandardName" SG_ 414 total "Powertrain_TsacVoltage_total_V";
BA_ "StandardName" SG_ 414 ts "Powertrain_TsacVoltage_ts_V";
BA_ "StandardName" SG_ 1267 cell24 "Kraken_TsacCellboard1Voltage_cell24_V";
BA_ "StandardName" SG_ 1267 cell18 "Kraken_TsacCellboard1Voltage_cell18_V";
BA_ "StandardName" SG_ 1267 cell12 "Kraken_TsacCellboard1Voltage_cell12_V";
BA_ "StandardName" SG_ 1267 cell6 "Kraken_TsacCellboard1Voltage_cell6_V";
BA_ "StandardName" SG_ 1267 cell23 "Kraken_TsacCellboard1Voltage_cell23_V";
BA_ "StandardName" SG_ 1267 cell17 "Kraken_TsacCellboard1Voltage_cell17_V";
BA_ "StandardName" SG_ 1267 cell11 "Kraken_TsacCellboard1Voltage_cell11_V";
BA_ "StandardName" SG_ 1267 cell5 "Kraken_TsacCellboard1Voltage_cell5_V";
BA_ "StandardName" SG_ 1267 cell22 "Kraken_TsacCellboard1Voltage_cell22_V";
BA_ "StandardName" SG_ 1267 cell16 "Kraken_TsacCellboard1Voltage_cell16_V";
BA_ "StandardName" SG_ 1267 cell10 "Kraken_TsacCellboard1Voltage_cell10_V";
BA_ "StandardName" SG_ 1267 cell4 "Kraken_TsacCellboard1Voltage_cell4_V";
BA_ "StandardName" SG_ 1267 cell21 "Kraken_TsacCellboard1Voltage_cell21_V";
BA_ "StandardName" SG_ 1267 cell15 "Kraken_TsacCellboard1Voltage_cell15_V";
BA_ "StandardName" SG_ 1267 cell9 "Kraken_TsacCellboard1Voltage_cell9_V";
BA_ "StandardName" SG_ 1267 cell3 "Kraken_TsacCellboard1Voltage_cell3_V";
BA_ "StandardName" SG_ 1267 cell20 "Kraken_TsacCellboard1Voltage_cell20_V";
BA_ "StandardName" SG_ 1267 cell14 "Kraken_TsacCellboard1Voltage_cell14_V";
BA_ "StandardName" SG_ 1267 cell8 "Kraken_TsacCellboard1Voltage_cell8_V";
BA_ "StandardName" SG_ 1267 cell2 "Kraken_TsacCellboard1Voltage_cell2_V";
BA_ "StandardName" SG_ 1267 cell19 "Kraken_TsacCellboard1Voltage_cell19_V";
BA_ "StandardName" SG_ 1267 cell13 "Kraken_TsacCellboard1Voltage_cell13_V";
BA_ "StandardName" SG_ 1267 cell7 "Kraken_TsacCellboard1Voltage_cell7_V";
BA_ "StandardName" SG_ 1267 cell1 "Kraken_TsacCellboard1Voltage_cell1_V";
BA_ "StandardName" SG_ 1268 cell24 "Kraken_TsacCellboard2Voltage_cell24_V";
BA_ "StandardName" SG_ 1268 cell18 "Kraken_TsacCellboard2Voltage_cell18_V";
BA_ "StandardName" SG_ 1268 cell12 "Kraken_TsacCellboard2Voltage_cell12_V";
BA_ "StandardName" SG_ 1268 cell6 "Kraken_TsacCellboard2Voltage_cell6_V";
BA_ "StandardName" SG_ 1268 cell23 "Kraken_TsacCellboard2Voltage_cell23_V";
BA_ "StandardName" SG_ 1268 cell17 "Kraken_TsacCellboard2Voltage_cell17_V";
BA_ "StandardName" SG_ 1268 cell11 "Kraken_TsacCellboard2Voltage_cell11_V";
BA_ "StandardName" SG_ 1268 cell5 "Kraken_TsacCellboard2Voltage_cell5_V";
BA_ "StandardName" SG_ 1268 cell22 "Kraken_TsacCellboard2Voltage_cell22_V";
BA_ "StandardName" SG_ 1268 cell16 "Kraken_TsacCellboard2Voltage_cell16_V";
BA_ "StandardName" SG_ 1268 cell10 "Kraken_TsacCellboard2Voltage_cell10_V";
BA_ "StandardName" SG_ 1268 cell4 "Kraken_TsacCellboard2Voltage_cell4_V";
BA_ "StandardName" SG_ 1268 cell21 "Kraken_TsacCellboard2Voltage_cell21_V";
BA_ "StandardName" SG_ 1268 cell15 "Kraken_TsacCellboard2Voltage_cell15_V";
BA_ "StandardName" SG_ 1268 cell9 "Kraken_TsacCellboard2Voltage_cell9_V";
BA_ "StandardName" SG_ 1268 cell3 "Kraken_TsacCellboard2Voltage_cell3_V";
BA_ "StandardName" SG_ 1268 cell20 "Kraken_TsacCellboard2Voltage_cell20_V";
BA_ "StandardName" SG_ 1268 cell14 "Kraken_TsacCellboard2Voltage_cell14_V";
BA_ "StandardName" SG_ 1268 cell8 "Kraken_TsacCellboard2Voltage_cell8_V";
BA_ "StandardName" SG_ 1268 cell2 "Kraken_TsacCellboard2Voltage_cell2_V";
BA_ "StandardName" SG_ 1268 cell19 "Kraken_TsacCellboard2Voltage_cell19_V";
BA_ "StandardName" SG_ 1268 cell13 "Kraken_TsacCellboard2Voltage_cell13_V";
BA_ "StandardName" SG_ 1268 cell7 "Kraken_TsacCellboard2Voltage_cell7_V";
BA_ "StandardName" SG_ 1268 cell1 "Kraken_TsacCellboard2Voltage_cell1_V";
BA_ "StandardName" SG_ 1269 cell24 "Kraken_TsacCellboard3Voltage_cell24_V";
BA_ "StandardName" SG_ 1269 cell18 "Kraken_TsacCellboard3Voltage_cell18_V";
BA_ "StandardName" SG_ 1269 cell12 "Kraken_TsacCellboard3Voltage_cell12_V";
BA_ "StandardName" SG_ 1269 cell6 "Kraken_TsacCellboard3Voltage_cell6_V";
BA_ "StandardName" SG_ 1269 cell23 "Kraken_TsacCellboard3Voltage_cell23_V";
BA_ "StandardName" SG_ 1269 cell17 "Kraken_TsacCellboard3Voltage_cell17_V";
BA_ "StandardName" SG_ 1269 cell11 "Kraken_TsacCellboard3Voltage_cell11_V";
BA_ "StandardName" SG_ 1269 cell5 "Kraken_TsacCellboard3Voltage_cell5_V";
BA_ "StandardName" SG_ 1269 cell22 "Kraken_TsacCellboard3Voltage_cell22_V";
BA_ "StandardName" SG_ 1269 cell16 "Kraken_TsacCellboard3Voltage_cell16_V";
BA_ "StandardName" SG_ 1269 cell10 "Kraken_TsacCellboard3Voltage_cell10_V";
BA_ "StandardName" SG_ 1269 cell4 "Kraken_TsacCellboard3Voltage_cell4_V";
BA_ "StandardName" SG_ 1269 cell21 "Kraken_TsacCellboard3Voltage_cell21_V";
BA_ "StandardName" SG_ 1269 cell15 "Kraken_TsacCellboard3Voltage_cell15_V";
BA_ "StandardName" SG_ 1269 cell9 "Kraken_TsacCellboard3Voltage_cell9_V";
BA_ "StandardName" SG_ 1269 cell3 "Kraken_TsacCellboard3Voltage_cell3_V";
BA_ "StandardName" SG_ 1269 cell20 "Kraken_TsacCellboard3Voltage_cell20_V";
BA_ "StandardName" SG_ 1269 cell14 "Kraken_TsacCellboard3Voltage_cell14_V";
BA_ "StandardName" SG_ 1269 cell8 "Kraken_TsacCellboard3Voltage_cell8_V";
BA_ "StandardName" SG_ 1269 cell2 "Kraken_TsacCellboard3Voltage_cell2_V";
BA_ "StandardName" SG_ 1269 cell19 "Kraken_TsacCellboard3Voltage_cell19_V";
BA_ "StandardName" SG_ 1269 cell13 "Kraken_TsacCellboard3Voltage_cell13_V";
BA_ "StandardName" SG_ 1269 cell7 "Kraken_TsacCellboard3Voltage_cell7_V";
BA_ "StandardName" SG_ 1269 cell1 "Kraken_TsacCellboard3Voltage_cell1_V";
BA_ "StandardName" SG_ 1270 cell24 "Kraken_TsacCellboard4Voltage_cell24_V";
BA_ "StandardName" SG_ 1270 cell18 "Kraken_TsacCellboard4Voltage_cell18_V";
BA_ "StandardName" SG_ 1270 cell12 "Kraken_TsacCellboard4Voltage_cell12_V";
BA_ "StandardName" SG_ 1270 cell6 "Kraken_TsacCellboard4Voltage_cell6_V";
BA_ "StandardName" SG_ 1270 cell23 "Kraken_TsacCellboard4Voltage_cell23_V";
BA_ "StandardName" SG_ 1270 cell17 "Kraken_TsacCellboard4Voltage_cell17_V";
BA_ "StandardName" SG_ 1270 cell11 "Kraken_TsacCellboard4Voltage_cell11_V";
BA_ "StandardName" SG_ 1270 cell5 "Kraken_TsacCellboard4Voltage_cell5_V";
BA_ "StandardName" SG_ 1270 cell22 "Kraken_TsacCellboard4Voltage_cell22_V";
BA_ "StandardName" SG_ 1270 cell16 "Kraken_TsacCellboard4Voltage_cell16_V";
BA_ "StandardName" SG_ 1270 cell10 "Kraken_TsacCellboard4Voltage_cell10_V";
BA_ "StandardName" SG_ 1270 cell4 "Kraken_TsacCellboard4Voltage_cell4_V";
BA_ "StandardName" SG_ 1270 cell21 "Kraken_TsacCellboard4Voltage_cell21_V";
BA_ "StandardName" SG_ 1270 cell15 "Kraken_TsacCellboard4Voltage_cell15_V";
BA_ "StandardName" SG_ 1270 cell9 "Kraken_TsacCellboard4Voltage_cell9_V";
BA_ "StandardName" SG_ 1270 cell3 "Kraken_TsacCellboard4Voltage_cell3_V";
BA_ "StandardName" SG_ 1270 cell20 "Kraken_TsacCellboard4Voltage_cell20_V";
BA_ "StandardName" SG_ 1270 cell14 "Kraken_TsacCellboard4Voltage_cell14_V";
BA_ "StandardName" SG_ 1270 cell8 "Kraken_TsacCellboard4Voltage_cell8_V";
BA_ "StandardName" SG_ 1270 cell2 "Kraken_TsacCellboard4Voltage_cell2_V";
BA_ "StandardName" SG_ 1270 cell19 "Kraken_TsacCellboard4Voltage_cell19_V";
BA_ "StandardName" SG_ 1270 cell13 "Kraken_TsacCellboard4Voltage_cell13_V";
BA_ "StandardName" SG_ 1270 cell7 "Kraken_TsacCellboard4Voltage_cell7_V";
BA_ "StandardName" SG_ 1270 cell1 "Kraken_TsacCellboard4Voltage_cell1_V";
BA_ "StandardName" SG_ 1271 cell24 "Kraken_TsacCellboard5Voltage_cell24_V";
BA_ "StandardName" SG_ 1271 cell18 "Kraken_TsacCellboard5Voltage_cell18_V";
BA_ "StandardName" SG_ 1271 cell12 "Kraken_TsacCellboard5Voltage_cell12_V";
BA_ "StandardName" SG_ 1271 cell6 "Kraken_TsacCellboard5Voltage_cell6_V";
BA_ "StandardName" SG_ 1271 cell23 "Kraken_TsacCellboard5Voltage_cell23_V";
BA_ "StandardName" SG_ 1271 cell17 "Kraken_TsacCellboard5Voltage_cell17_V";
BA_ "StandardName" SG_ 1271 cell11 "Kraken_TsacCellboard5Voltage_cell11_V";
BA_ "StandardName" SG_ 1271 cell5 "Kraken_TsacCellboard5Voltage_cell5_V";
BA_ "StandardName" SG_ 1271 cell22 "Kraken_TsacCellboard5Voltage_cell22_V";
BA_ "StandardName" SG_ 1271 cell16 "Kraken_TsacCellboard5Voltage_cell16_V";
BA_ "StandardName" SG_ 1271 cell10 "Kraken_TsacCellboard5Voltage_cell10_V";
BA_ "StandardName" SG_ 1271 cell4 "Kraken_TsacCellboard5Voltage_cell4_V";
BA_ "StandardName" SG_ 1271 cell21 "Kraken_TsacCellboard5Voltage_cell21_V";
BA_ "StandardName" SG_ 1271 cell15 "Kraken_TsacCellboard5Voltage_cell15_V";
BA_ "StandardName" SG_ 1271 cell9 "Kraken_TsacCellboard5Voltage_cell9_V";
BA_ "StandardName" SG_ 1271 cell3 "Kraken_TsacCellboard5Voltage_cell3_V";
BA_ "StandardName" SG_ 1271 cell20 "Kraken_TsacCellboard5Voltage_cell20_V";
BA_ "StandardName" SG_ 1271 cell14 "Kraken_TsacCellboard5Voltage_cell14_V";
BA_ "StandardName" SG_ 1271 cell8 "Kraken_TsacCellboard5Voltage_cell8_V";
BA_ "StandardName" SG_ 1271 cell2 "Kraken_TsacCellboard5Voltage_cell2_V";
BA_ "StandardName" SG_ 1271 cell19 "Kraken_TsacCellboard5Voltage_cell19_V";
BA_ "StandardName" SG_ 1271 cell13 "Kraken_TsacCellboard5Voltage_cell13_V";
BA_ "StandardName" SG_ 1271 cell7 "Kraken_TsacCellboard5Voltage_cell7_V";
BA_ "StandardName" SG_ 1271 cell1 "Kraken_TsacCellboard5Voltage_cell1_V";
BA_ "StandardName" SG_ 1272 cell24 "Kraken_TsacCellboard6Voltage_cell24_V";
BA_ "StandardName" SG_ 1272 cell18 "Kraken_TsacCellboard6Voltage_cell18_V";
BA_ "StandardName" SG_ 1272 cell12 "Kraken_TsacCellboard6Voltage_cell12_V";
BA_ "StandardName" SG_ 1272 cell6 "Kraken_TsacCellboard6Voltage_cell6_V";
BA_ "StandardName" SG_ 1272 cell23 "Kraken_TsacCellboard6Voltage_cell23_V";
BA_ "StandardName" SG_ 1272 cell17 "Kraken_TsacCellboard6Voltage_cell17_V";
BA_ "StandardName" SG_ 1272 cell11 "Kraken_TsacCellboard6Voltage_cell11_V";
BA_ "StandardName" SG_ 1272 cell5 "Kraken_TsacCellboard6Voltage_cell5_V";
BA_ "StandardName" SG_ 1272 cell22 "Kraken_TsacCellboard6Voltage_cell22_V";
BA_ "StandardName" SG_ 1272 cell16 "Kraken_TsacCellboard6Voltage_cell16_V";
BA_ "StandardName" SG_ 1272 cell10 "Kraken_TsacCellboard6Voltage_cell10_V";
BA_ "StandardName" SG_ 1272 cell4 "Kraken_TsacCellboard6Voltage_cell4_V";
BA_ "StandardName" SG_ 1272 cell21 "Kraken_TsacCellboard6Voltage_cell21_V";
BA_ "StandardName" SG_ 1272 cell15 "Kraken_TsacCellboard6Voltage_cell15_V";
BA_ "StandardName" SG_ 1272 cell9 "Kraken_TsacCellboard6Voltage_cell9_V";
BA_ "StandardName" SG_ 1272 cell3 "Kraken_TsacCellboard6Voltage_cell3_V";
BA_ "StandardName" SG_ 1272 cell20 "Kraken_TsacCellboard6Voltage_cell20_V";
BA_ "StandardName" SG_ 1272 cell14 "Kraken_TsacCellboard6Voltage_cell14_V";
BA_ "StandardName" SG_ 1272 cell8 "Kraken_TsacCellboard6Voltage_cell8_V";
BA_ "StandardName" SG_ 1272 cell2 "Kraken_TsacCellboard6Voltage_cell2_V";
BA_ "StandardName" SG_ 1272 cell19 "Kraken_TsacCellboard6Voltage_cell19_V";
BA_ "StandardName" SG_ 1272 cell13 "Kraken_TsacCellboard6Voltage_cell13_V";
BA_ "StandardName" SG_ 1272 cell7 "Kraken_TsacCellboard6Voltage_cell7_V";
BA_ "StandardName" SG_ 1272 cell1 "Kraken_TsacCellboard6Voltage_cell1_V";
BA_ "StandardName" SG_ 1273 linearRegulator "Kraken_TsacMainboardTemperature_linearRegulator_degC";
BA_ "StandardName" SG_ 1273 precharge "Powertrain_TsacTemperature_precharge_degC";
BA_ "StandardName" SG_ 1273 average "Powertrain_TsacTemperature_average_degC";
BA_ "StandardName" SG_ 1273 max "Powertrain_TsacTemperature_max_degC";
BA_ "StandardName" SG_ 1273 min "Powertrain_TsacTemperature_min_degC";
BA_ "StandardName" SG_ 1274 cell45 "Kraken_TsacCellboard1Temperature_cell45_degC";
BA_ "StandardName" SG_ 1274 cell40 "Kraken_TsacCellboard1Temperature_cell40_degC";
BA_ "StandardName" SG_ 1274 cell35 "Kraken_TsacCellboard1Temperature_cell35_degC";
BA_ "StandardName" SG_ 1274 cell30 "Kraken_TsacCellboard1Temperature_cell30_degC";
BA_ "StandardName" SG_ 1274 cell25 "Kraken_TsacCellboard1Temperature_cell25_degC";
BA_ "StandardName" SG_ 1274 cell20 "Kraken_TsacCellboard1Temperature_cell20_degC";
BA_ "StandardName" SG_ 1274 cell15 "Kraken_TsacCellboard1Temperature_cell15_degC";
BA_ "StandardName" SG_ 1274 cell10 "Kraken_TsacCellboard1Temperature_cell10_degC";
BA_ "StandardName" SG_ 1274 cell5 "Kraken_TsacCellboard1Temperature_cell5_degC";
BA_ "StandardName" SG_ 1274 cell44 "Kraken_TsacCellboard1Temperature_cell44_degC";
BA_ "StandardName" SG_ 1274 cell39 "Kraken_TsacCellboard1Temperature_cell39_degC";
BA_ "StandardName" SG_ 1274 cell34 "Kraken_TsacCellboard1Temperature_cell34_degC";
BA_ "StandardName" SG_ 1274 cell29 "Kraken_TsacCellboard1Temperature_cell29_degC";
BA_ "StandardName" SG_ 1274 cell24 "Kraken_TsacCellboard1Temperature_cell24_degC";
BA_ "StandardName" SG_ 1274 cell19 "Kraken_TsacCellboard1Temperature_cell19_degC";
BA_ "StandardName" SG_ 1274 cell14 "Kraken_TsacCellboard1Temperature_cell14_degC";
BA_ "StandardName" SG_ 1274 cell9 "Kraken_TsacCellboard1Temperature_cell9_degC";
BA_ "StandardName" SG_ 1274 cell4 "Kraken_TsacCellboard1Temperature_cell4_degC";
BA_ "StandardName" SG_ 1274 cell48 "Kraken_TsacCellboard1Temperature_cell48_degC";
BA_ "StandardName" SG_ 1274 cell43 "Kraken_TsacCellboard1Temperature_cell43_degC";
BA_ "StandardName" SG_ 1274 cell38 "Kraken_TsacCellboard1Temperature_cell38_degC";
BA_ "StandardName" SG_ 1274 cell33 "Kraken_TsacCellboard1Temperature_cell33_degC";
BA_ "StandardName" SG_ 1274 cell28 "Kraken_TsacCellboard1Temperature_cell28_degC";
BA_ "StandardName" SG_ 1274 cell23 "Kraken_TsacCellboard1Temperature_cell23_degC";
BA_ "StandardName" SG_ 1274 cell18 "Kraken_TsacCellboard1Temperature_cell18_degC";
BA_ "StandardName" SG_ 1274 cell13 "Kraken_TsacCellboard1Temperature_cell13_degC";
BA_ "StandardName" SG_ 1274 cell8 "Kraken_TsacCellboard1Temperature_cell8_degC";
BA_ "StandardName" SG_ 1274 cell3 "Kraken_TsacCellboard1Temperature_cell3_degC";
BA_ "StandardName" SG_ 1274 cell47 "Kraken_TsacCellboard1Temperature_cell47_degC";
BA_ "StandardName" SG_ 1274 cell42 "Kraken_TsacCellboard1Temperature_cell42_degC";
BA_ "StandardName" SG_ 1274 cell37 "Kraken_TsacCellboard1Temperature_cell37_degC";
BA_ "StandardName" SG_ 1274 cell32 "Kraken_TsacCellboard1Temperature_cell32_degC";
BA_ "StandardName" SG_ 1274 cell27 "Kraken_TsacCellboard1Temperature_cell27_degC";
BA_ "StandardName" SG_ 1274 cell22 "Kraken_TsacCellboard1Temperature_cell22_degC";
BA_ "StandardName" SG_ 1274 cell17 "Kraken_TsacCellboard1Temperature_cell17_degC";
BA_ "StandardName" SG_ 1274 cell12 "Kraken_TsacCellboard1Temperature_cell12_degC";
BA_ "StandardName" SG_ 1274 cell7 "Kraken_TsacCellboard1Temperature_cell7_degC";
BA_ "StandardName" SG_ 1274 cell2 "Kraken_TsacCellboard1Temperature_cell2_degC";
BA_ "StandardName" SG_ 1274 cell46 "Kraken_TsacCellboard1Temperature_cell46_degC";
BA_ "StandardName" SG_ 1274 cell41 "Kraken_TsacCellboard1Temperature_cell41_degC";
BA_ "StandardName" SG_ 1274 cell36 "Kraken_TsacCellboard1Temperature_cell36_degC";
BA_ "StandardName" SG_ 1274 cell31 "Kraken_TsacCellboard1Temperature_cell31_degC";
BA_ "StandardName" SG_ 1274 cell26 "Kraken_TsacCellboard1Temperature_cell26_degC";
BA_ "StandardName" SG_ 1274 cell21 "Kraken_TsacCellboard1Temperature_cell21_degC";
BA_ "StandardName" SG_ 1274 cell16 "Kraken_TsacCellboard1Temperature_cell16_degC";
BA_ "StandardName" SG_ 1274 cell11 "Kraken_TsacCellboard1Temperature_cell11_degC";
BA_ "StandardName" SG_ 1274 cell6 "Kraken_TsacCellboard1Temperature_cell6_degC";
BA_ "StandardName" SG_ 1274 cell1 "Kraken_TsacCellboard1Temperature_cell1_degC";
BA_ "StandardName" SG_ 1275 cell45 "Kraken_TsacCellboard2Temperature_cell45_degC";
BA_ "StandardName" SG_ 1275 cell40 "Kraken_TsacCellboard2Temperature_cell40_degC";
BA_ "StandardName" SG_ 1275 cell35 "Kraken_TsacCellboard2Temperature_cell35_degC";
BA_ "StandardName" SG_ 1275 cell30 "Kraken_TsacCellboard2Temperature_cell30_degC";
BA_ "StandardName" SG_ 1275 cell25 "Kraken_TsacCellboard2Temperature_cell25_degC";
BA_ "StandardName" SG_ 1275 cell20 "Kraken_TsacCellboard2Temperature_cell20_degC";
BA_ "StandardName" SG_ 1275 cell15 "Kraken_TsacCellboard2Temperature_cell15_degC";
BA_ "StandardName" SG_ 1275 cell10 "Kraken_TsacCellboard2Temperature_cell10_degC";
BA_ "StandardName" SG_ 1275 cell5 "Kraken_TsacCellboard2Temperature_cell5_degC";
BA_ "StandardName" SG_ 1275 cell44 "Kraken_TsacCellboard2Temperature_cell44_degC";
BA_ "StandardName" SG_ 1275 cell39 "Kraken_TsacCellboard2Temperature_cell39_degC";
BA_ "StandardName" SG_ 1275 cell34 "Kraken_TsacCellboard2Temperature_cell34_degC";
BA_ "StandardName" SG_ 1275 cell29 "Kraken_TsacCellboard2Temperature_cell29_degC";
BA_ "StandardName" SG_ 1275 cell24 "Kraken_TsacCellboard2Temperature_cell24_degC";
BA_ "StandardName" SG_ 1275 cell19 "Kraken_TsacCellboard2Temperature_cell19_degC";
BA_ "StandardName" SG_ 1275 cell14 "Kraken_TsacCellboard2Temperature_cell14_degC";
BA_ "StandardName" SG_ 1275 cell9 "Kraken_TsacCellboard2Temperature_cell9_degC";
BA_ "StandardName" SG_ 1275 cell4 "Kraken_TsacCellboard2Temperature_cell4_degC";
BA_ "StandardName" SG_ 1275 cell48 "Kraken_TsacCellboard2Temperature_cell48_degC";
BA_ "StandardName" SG_ 1275 cell43 "Kraken_TsacCellboard2Temperature_cell43_degC";
BA_ "StandardName" SG_ 1275 cell38 "Kraken_TsacCellboard2Temperature_cell38_degC";
BA_ "StandardName" SG_ 1275 cell33 "Kraken_TsacCellboard2Temperature_cell33_degC";
BA_ "StandardName" SG_ 1275 cell28 "Kraken_TsacCellboard2Temperature_cell28_degC";
BA_ "StandardName" SG_ 1275 cell23 "Kraken_TsacCellboard2Temperature_cell23_degC";
BA_ "StandardName" SG_ 1275 cell18 "Kraken_TsacCellboard2Temperature_cell18_degC";
BA_ "StandardName" SG_ 1275 cell13 "Kraken_TsacCellboard2Temperature_cell13_degC";
BA_ "StandardName" SG_ 1275 cell8 "Kraken_TsacCellboard2Temperature_cell8_degC";
BA_ "StandardName" SG_ 1275 cell3 "Kraken_TsacCellboard2Temperature_cell3_degC";
BA_ "StandardName" SG_ 1275 cell47 "Kraken_TsacCellboard2Temperature_cell47_degC";
BA_ "StandardName" SG_ 1275 cell42 "Kraken_TsacCellboard2Temperature_cell42_degC";
BA_ "StandardName" SG_ 1275 cell37 "Kraken_TsacCellboard2Temperature_cell37_degC";
BA_ "StandardName" SG_ 1275 cell32 "Kraken_TsacCellboard2Temperature_cell32_degC";
BA_ "StandardName" SG_ 1275 cell27 "Kraken_TsacCellboard2Temperature_cell27_degC";
BA_ "StandardName" SG_ 1275 cell22 "Kraken_TsacCellboard2Temperature_cell22_degC";
BA_ "StandardName" SG_ 1275 cell17 "Kraken_TsacCellboard2Temperature_cell17_degC";
BA_ "StandardName" SG_ 1275 cell12 "Kraken_TsacCellboard2Temperature_cell12_degC";
BA_ "StandardName" SG_ 1275 cell7 "Kraken_TsacCellboard2Temperature_cell7_degC";
BA_ "StandardName" SG_ 1275 cell2 "Kraken_TsacCellboard2Temperature_cell2_degC";
BA_ "StandardName" SG_ 1275 cell46 "Kraken_TsacCellboard2Temperature_cell46_degC";
BA_ "StandardName" SG_ 1275 cell41 "Kraken_TsacCellboard2Temperature_cell41_degC";
BA_ "StandardName" SG_ 1275 cell36 "Kraken_TsacCellboard2Temperature_cell36_degC";
BA_ "StandardName" SG_ 1275 cell31 "Kraken_TsacCellboard2Temperature_cell31_degC";
BA_ "StandardName" SG_ 1275 cell26 "Kraken_TsacCellboard2Temperature_cell26_degC";
BA_ "StandardName" SG_ 1275 cell21 "Kraken_TsacCellboard2Temperature_cell21_degC";
BA_ "StandardName" SG_ 1275 cell16 "Kraken_TsacCellboard2Temperature_cell16_degC";
BA_ "StandardName" SG_ 1275 cell11 "Kraken_TsacCellboard2Temperature_cell11_degC";
BA_ "StandardName" SG_ 1275 cell6 "Kraken_TsacCellboard2Temperature_cell6_degC";
BA_ "StandardName" SG_ 1275 cell1 "Kraken_TsacCellboard2Temperature_cell1_degC";
BA_ "StandardName" SG_ 1276 cell45 "Kraken_TsacCellboard3Temperature_cell45_degC";
BA_ "StandardName" SG_ 1276 cell40 "Kraken_TsacCellboard3Temperature_cell40_degC";
BA_ "StandardName" SG_ 1276 cell35 "Kraken_TsacCellboard3Temperature_cell35_degC";
BA_ "StandardName" SG_ 1276 cell30 "Kraken_TsacCellboard3Temperature_cell30_degC";
BA_ "StandardName" SG_ 1276 cell25 "Kraken_TsacCellboard3Temperature_cell25_degC";
BA_ "StandardName" SG_ 1276 cell20 "Kraken_TsacCellboard3Temperature_cell20_degC";
BA_ "StandardName" SG_ 1276 cell15 "Kraken_TsacCellboard3Temperature_cell15_degC";
BA_ "StandardName" SG_ 1276 cell10 "Kraken_TsacCellboard3Temperature_cell10_degC";
BA_ "StandardName" SG_ 1276 cell5 "Kraken_TsacCellboard3Temperature_cell5_degC";
BA_ "StandardName" SG_ 1276 cell44 "Kraken_TsacCellboard3Temperature_cell44_degC";
BA_ "StandardName" SG_ 1276 cell39 "Kraken_TsacCellboard3Temperature_cell39_degC";
BA_ "StandardName" SG_ 1276 cell34 "Kraken_TsacCellboard3Temperature_cell34_degC";
BA_ "StandardName" SG_ 1276 cell29 "Kraken_TsacCellboard3Temperature_cell29_degC";
BA_ "StandardName" SG_ 1276 cell24 "Kraken_TsacCellboard3Temperature_cell24_degC";
BA_ "StandardName" SG_ 1276 cell19 "Kraken_TsacCellboard3Temperature_cell19_degC";
BA_ "StandardName" SG_ 1276 cell14 "Kraken_TsacCellboard3Temperature_cell14_degC";
BA_ "StandardName" SG_ 1276 cell9 "Kraken_TsacCellboard3Temperature_cell9_degC";
BA_ "StandardName" SG_ 1276 cell4 "Kraken_TsacCellboard3Temperature_cell4_degC";
BA_ "StandardName" SG_ 1276 cell48 "Kraken_TsacCellboard3Temperature_cell48_degC";
BA_ "StandardName" SG_ 1276 cell43 "Kraken_TsacCellboard3Temperature_cell43_degC";
BA_ "StandardName" SG_ 1276 cell38 "Kraken_TsacCellboard3Temperature_cell38_degC";
BA_ "StandardName" SG_ 1276 cell33 "Kraken_TsacCellboard3Temperature_cell33_degC";
BA_ "StandardName" SG_ 1276 cell28 "Kraken_TsacCellboard3Temperature_cell28_degC";
BA_ "StandardName" SG_ 1276 cell23 "Kraken_TsacCellboard3Temperature_cell23_degC";
BA_ "StandardName" SG_ 1276 cell18 "Kraken_TsacCellboard3Temperature_cell18_degC";
BA_ "StandardName" SG_ 1276 cell13 "Kraken_TsacCellboard3Temperature_cell13_degC";
BA_ "StandardName" SG_ 1276 cell8 "Kraken_TsacCellboard3Temperature_cell8_degC";
BA_ "StandardName" SG_ 1276 cell3 "Kraken_TsacCellboard3Temperature_cell3_degC";
BA_ "StandardName" SG_ 1276 cell47 "Kraken_TsacCellboard3Temperature_cell47_degC";
BA_ "StandardName" SG_ 1276 cell42 "Kraken_TsacCellboard3Temperature_cell42_degC";
BA_ "StandardName" SG_ 1276 cell37 "Kraken_TsacCellboard3Temperature_cell37_degC";
BA_ "StandardName" SG_ 1276 cell32 "Kraken_TsacCellboard3Temperature_cell32_degC";
BA_ "StandardName" SG_ 1276 cell27 "Kraken_TsacCellboard3Temperature_cell27_degC";
BA_ "StandardName" SG_ 1276 cell22 "Kraken_TsacCellboard3Temperature_cell22_degC";
BA_ "StandardName" SG_ 1276 cell17 "Kraken_TsacCellboard3Temperature_cell17_degC";
BA_ "StandardName" SG_ 1276 cell12 "Kraken_TsacCellboard3Temperature_cell12_degC";
BA_ "StandardName" SG_ 1276 cell7 "Kraken_TsacCellboard3Temperature_cell7_degC";
BA_ "StandardName" SG_ 1276 cell2 "Kraken_TsacCellboard3Temperature_cell2_degC";
BA_ "StandardName" SG_ 1276 cell46 "Kraken_TsacCellboard3Temperature_cell46_degC";
BA_ "StandardName" SG_ 1276 cell41 "Kraken_TsacCellboard3Temperature_cell41_degC";
BA_ "StandardName" SG_ 1276 cell36 "Kraken_TsacCellboard3Temperature_cell36_degC";
BA_ "StandardName" SG_ 1276 cell31 "Kraken_TsacCellboard3Temperature_cell31_degC";
BA_ "StandardName" SG_ 1276 cell26 "Kraken_TsacCellboard3Temperature_cell26_degC";
BA_ "StandardName" SG_ 1276 cell21 "Kraken_TsacCellboard3Temperature_cell21_degC";
BA_ "StandardName" SG_ 1276 cell16 "Kraken_TsacCellboard3Temperature_cell16_degC";
BA_ "StandardName" SG_ 1276 cell11 "Kraken_TsacCellboard3Temperature_cell11_degC";
BA_ "StandardName" SG_ 1276 cell6 "Kraken_TsacCellboard3Temperature_cell6_degC";
BA_ "StandardName" SG_ 1276 cell1 "Kraken_TsacCellboard3Temperature_cell1_degC";
BA_ "StandardName" SG_ 1277 cell45 "Kraken_TsacCellboard4Temperature_cell45_degC";
BA_ "StandardName" SG_ 1277 cell40 "Kraken_TsacCellboard4Temperature_cell40_degC";
BA_ "StandardName" SG_ 1277 cell35 "Kraken_TsacCellboard4Temperature_cell35_degC";
BA_ "StandardName" SG_ 1277 cell30 "Kraken_TsacCellboard4Temperature_cell30_degC";
BA_ "StandardName" SG_ 1277 cell25 "Kraken_TsacCellboard4Temperature_cell25_degC";
BA_ "StandardName" SG_ 1277 cell20 "Kraken_TsacCellboard4Temperature_cell20_degC";
BA_ "StandardName" SG_ 1277 cell15 "Kraken_TsacCellboard4Temperature_cell15_degC";
BA_ "StandardName" SG_ 1277 cell10 "Kraken_TsacCellboard4Temperature_cell10_degC";
BA_ "StandardName" SG_ 1277 cell5 "Kraken_TsacCellboard4Temperature_cell5_degC";
BA_ "StandardName" SG_ 1277 cell44 "Kraken_TsacCellboard4Temperature_cell44_degC";
BA_ "StandardName" SG_ 1277 cell39 "Kraken_TsacCellboard4Temperature_cell39_degC";
BA_ "StandardName" SG_ 1277 cell34 "Kraken_TsacCellboard4Temperature_cell34_degC";
BA_ "StandardName" SG_ 1277 cell29 "Kraken_TsacCellboard4Temperature_cell29_degC";
BA_ "StandardName" SG_ 1277 cell24 "Kraken_TsacCellboard4Temperature_cell24_degC";
BA_ "StandardName" SG_ 1277 cell19 "Kraken_TsacCellboard4Temperature_cell19_degC";
BA_ "StandardName" SG_ 1277 cell14 "Kraken_TsacCellboard4Temperature_cell14_degC";
BA_ "StandardName" SG_ 1277 cell9 "Kraken_TsacCellboard4Temperature_cell9_degC";
BA_ "StandardName" SG_ 1277 cell4 "Kraken_TsacCellboard4Temperature_cell4_degC";
BA_ "StandardName" SG_ 1277 cell48 "Kraken_TsacCellboard4Temperature_cell48_degC";
BA_ "StandardName" SG_ 1277 cell43 "Kraken_TsacCellboard4Temperature_cell43_degC";
BA_ "StandardName" SG_ 1277 cell38 "Kraken_TsacCellboard4Temperature_cell38_degC";
BA_ "StandardName" SG_ 1277 cell33 "Kraken_TsacCellboard4Temperature_cell33_degC";
BA_ "StandardName" SG_ 1277 cell28 "Kraken_TsacCellboard4Temperature_cell28_degC";
BA_ "StandardName" SG_ 1277 cell23 "Kraken_TsacCellboard4Temperature_cell23_degC";
BA_ "StandardName" SG_ 1277 cell18 "Kraken_TsacCellboard4Temperature_cell18_degC";
BA_ "StandardName" SG_ 1277 cell13 "Kraken_TsacCellboard4Temperature_cell13_degC";
BA_ "StandardName" SG_ 1277 cell8 "Kraken_TsacCellboard4Temperature_cell8_degC";
BA_ "StandardName" SG_ 1277 cell3 "Kraken_TsacCellboard4Temperature_cell3_degC";
BA_ "StandardName" SG_ 1277 cell47 "Kraken_TsacCellboard4Temperature_cell47_degC";
BA_ "StandardName" SG_ 1277 cell42 "Kraken_TsacCellboard4Temperature_cell42_degC";
BA_ "StandardName" SG_ 1277 cell37 "Kraken_TsacCellboard4Temperature_cell37_degC";
BA_ "StandardName" SG_ 1277 cell32 "Kraken_TsacCellboard4Temperature_cell32_degC";
BA_ "StandardName" SG_ 1277 cell27 "Kraken_TsacCellboard4Temperature_cell27_degC";
BA_ "StandardName" SG_ 1277 cell22 "Kraken_TsacCellboard4Temperature_cell22_degC";
BA_ "StandardName" SG_ 1277 cell17 "Kraken_TsacCellboard4Temperature_cell17_degC";
BA_ "StandardName" SG_ 1277 cell12 "Kraken_TsacCellboard4Temperature_cell12_degC";
BA_ "StandardName" SG_ 1277 cell7 "Kraken_TsacCellboard4Temperature_cell7_degC";
BA_ "StandardName" SG_ 1277 cell2 "Kraken_TsacCellboard4Temperature_cell2_degC";
BA_ "StandardName" SG_ 1277 cell46 "Kraken_TsacCellboard4Temperature_cell46_degC";
BA_ "StandardName" SG_ 1277 cell41 "Kraken_TsacCellboard4Temperature_cell41_degC";
BA_ "StandardName" SG_ 1277 cell36 "Kraken_TsacCellboard4Temperature_cell36_degC";
BA_ "StandardName" SG_ 1277 cell31 "Kraken_TsacCellboard4Temperature_cell31_degC";
BA_ "StandardName" SG_ 1277 cell26 "Kraken_TsacCellboard4Temperature_cell26_degC";
BA_ "StandardName" SG_ 1277 cell21 "Kraken_TsacCellboard4Temperature_cell21_degC";
BA_ "StandardName" SG_ 1277 cell16 "Kraken_TsacCellboard4Temperature_cell16_degC";
BA_ "StandardName" SG_ 1277 cell11 "Kraken_TsacCellboard4Temperature_cell11_degC";
BA_ "StandardName" SG_ 1277 cell6 "Kraken_TsacCellboard4Temperature_cell6_degC";
BA_ "StandardName" SG_ 1277 cell1 "Kraken_TsacCellboard4Temperature_cell1_degC";
VAL_ 1227 status 0 "INIT" 1 "IDLE" 2 "ERROR" 3 "FLASH" ;
VAL_ 1230 status 0 "INIT" 1 "IDLE" 2 "ERROR" 3 "FLASH" ;
VAL_ 1235 status 0 "INIT" 1 "IDLE" 2 "ERROR" 3 "FLASH" ;
VAL_ 1240 status 0 "INIT" 1 "IDLE" 2 "ERROR" 3 "FLASH" 4 "AUTONOMOUS" ;
VAL_ 1241 status 0 "INIT" 1 "IDLE" 2 "ERROR" 3 "FLASH" ;
VAL_ 1246 status 0 "INIT" 1 "IDLE" 2 "ERROR" 3 "FLASH" ;
VAL_ 1248 status 0 "INIT" 1 "IDLE" 2 "ERROR" 3 "FLASH" ;
VAL_ 2 krakenStatus 0 "INIT" 1 "FATAL" 2 "IDLE" 3 "FLASH" 4 "PAUSE" 5 "MANUAL_WAIT_TS_PRECHARGE" 6 "AS_OFF" 7 "WAIT_DRIVER" 8 "MANUAL_WAIT_TS_DISCHARGE" 9 "MANUAL_WAIT_INV_ENABLE" 10 "DRIVING" 11 "MANUAL_WAIT_INV_DISABLE" 12 "AS_OFF_WAIT_TS_PRECHARGE" 13 "AS_READY" 14 "AS_READY_WAIT_INV_ENABLE" 15 "AS_EMERGENCY" 16 "AS_R2D" 17 "AS_DRIVING" 18 "AS_FINISHED" 19 "AS_OFF_WAIT_TS_DISCHARGE" 20 "AS_READY_WAIT_INV_DISABLE" 21 "AS_FINISHED_WAIT_INV_DISABLE" 22 "AS_FINISHED_WAIT_TS_DISCHARGE" 23 "AS_EMERGENCY_WAIT_INV_DISABLE" 24 "AS_EMERGENCY_WAIT_TS_DISCHARGE" ;
VAL_ 2 vehicleStatus 0 "INIT" 1 "IDLE" 2 "PRECHARGE" 3 "TSON" 4 "DISCHARGE" 5 "ASOFF" 6 "AS_READY" 7 "AS_DRIVING" 8 "ERROR" 9 "R2D" 10 "AS_R2D" 11 "AS_FINISHED" 12 "AS_EMERGENCY" ;
VAL_ 1255 status 0 "INIT" 1 "IDLE" 2 "SETUP_RUN" 3 "RUN" 4 "ERROR" ;
VAL_ 1265 status 0 "INIT" 1 "IDLE" 2 "ERROR" 3 "FLASH" ;
VAL_ 4 plausibility 0 "OK" 1 "IMPLAUSIBILITY_RECOVERABLE" 2 "IMPLAUSIBILITY_ERROR" 3 "CALLBACK_ERROR" ;
VAL_ 412 cellboard6Status 0 "INIT" 1 "IDLE" 2 "ERROR" 3 "FLASH" 4 "DISCHARGE" 5 "COOLDOWN" ;
VAL_ 412 cellboard5Status 0 "INIT" 1 "IDLE" 2 "ERROR" 3 "FLASH" 4 "DISCHARGE" 5 "COOLDOWN" ;
VAL_ 412 cellboard4Status 0 "INIT" 1 "IDLE" 2 "ERROR" 3 "FLASH" 4 "DISCHARGE" 5 "COOLDOWN" ;
VAL_ 412 cellboard3Status 0 "INIT" 1 "IDLE" 2 "ERROR" 3 "FLASH" 4 "DISCHARGE" 5 "COOLDOWN" ;
VAL_ 412 cellboard2Status 0 "INIT" 1 "IDLE" 2 "ERROR" 3 "FLASH" 4 "DISCHARGE" 5 "COOLDOWN" ;
VAL_ 412 cellboard1Status 0 "INIT" 1 "IDLE" 2 "ERROR" 3 "FLASH" 4 "DISCHARGE" 5 "COOLDOWN" ;
VAL_ 412 mainboardStatus 0 "INIT" 1 "IDLE" 2 "ERROR" 3 "FLASH" 4 "BALANCING" 5 "AIRN_CHECK" 6 "PRECHARGE" 7 "AIRP_CHECK" 8 "TS_ON" ;
